VERSION "HNNBNNNYNNNNNNNNNNNNNNNNNNNNNNNNNNNNNNNNNN/4/%%%/4/'%**4NNN///"

NS_ :

BS_:

BU_: Airbag BAP_Tester ICAS1_Gateway ICAS1_KommunikationsServer LE1 LE2 Motor_BEV Schaltbetaetigung

BO_ 514 Daempfer_03: 32 ICAS1_Gateway
 SG_ DR_Aufbaubeschleunigung_HR : 12|10@1+ (0.0327,-15.696) [-15.6960|15.6960] "Unit_MeterPerSeconSquar"  Motor_BEV
 SG_ DR_Aufbaubeschleunigung_VR : 22|10@1+ (0.0327,-15.696) [-15.6960|15.6960] "Unit_MeterPerSeconSquar"  Motor_BEV
 SG_ DR_Aufbaubeschleunigung_VL : 32|10@1+ (0.0327,-15.696) [-15.6960|15.6960] "Unit_MeterPerSeconSquar"  Motor_BEV
 SG_ DR_Aufbaubeschleunigung_HL : 42|10@1+ (0.0327,-15.696) [-15.6960|15.6960] "Unit_MeterPerSeconSquar"  Motor_BEV
 SG_ DR_Funktionsstatus : 52|2@1+ (1.0,0.0) [0.0|3] ""  Vector__XXX
 SG_ DR_Drehwinkelsensortausch_VL : 72|2@1+ (1,0) [1|3] ""  Vector__XXX
 SG_ DR_Drehwinkelsensortausch_VR : 74|2@1+ (1,0) [1|3] ""  Vector__XXX
 SG_ DR_Drehwinkelsensortausch_HL : 76|2@1+ (1,0) [1|3] ""  Vector__XXX
 SG_ DR_Drehwinkelsensortausch_HR : 78|2@1+ (1,0) [1|3] ""  Vector__XXX
 SG_ DR_Drehwinkel_VL : 80|12@1+ (0.088,0) [0.000|359.920] ""  Vector__XXX
 SG_ DR_Drehwinkel_VR : 92|12@1+ (0.088,0) [0.000|359.920] ""  Vector__XXX
 SG_ DR_Drehwinkel_HL : 104|12@1+ (0.088,0) [0.000|359.920] ""  Vector__XXX
 SG_ DR_Drehwinkel_HR : 116|12@1+ (0.088,0) [0.000|359.920] ""  Vector__XXX

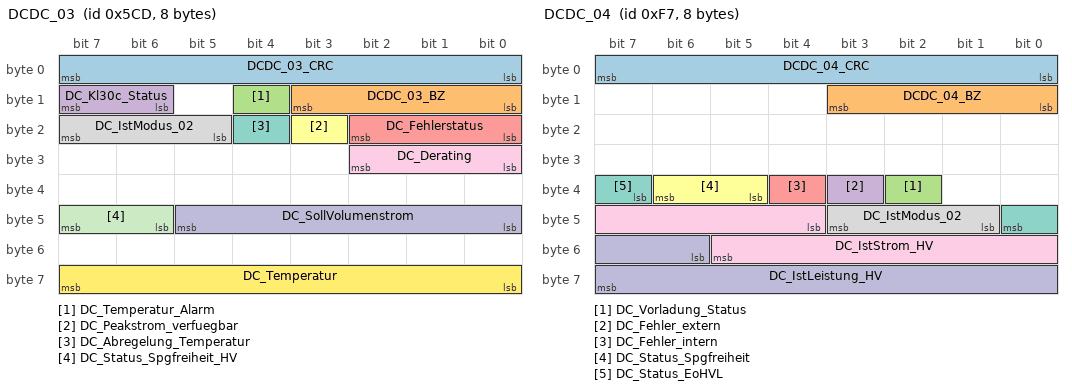
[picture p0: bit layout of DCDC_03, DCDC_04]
BO_ 1485 DCDC_03: 8 ICAS1_Gateway
 SG_ DCDC_03_CRC : 0|8@1+ (1,0) [0|255] ""  Motor_BEV
 SG_ DCDC_03_BZ : 8|4@1+ (1,0) [0|15] ""  Motor_BEV
 SG_ DC_Temperatur_Alarm : 12|1@1+ (1.0,0.0) [0.0|1] ""  Vector__XXX
 SG_ DC_Kl30c_Status : 14|2@1+ (1.0,0.0) [0.0|3] ""  Motor_BEV
 SG_ DC_Fehlerstatus : 16|3@1+ (1.0,0.0) [0.0|7] ""  Vector__XXX
 SG_ DC_Peakstrom_verfuegbar : 19|1@1+ (1.0,0.0) [0.0|1] ""  Vector__XXX
 SG_ DC_Abregelung_Temperatur : 20|1@1+ (1.0,0.0) [0.0|1] ""  Vector__XXX
 SG_ DC_IstModus_02 : 21|3@1+ (1.0,0.0) [0.0|7] ""  Vector__XXX
 SG_ DC_Derating : 24|3@1+ (1.0,0.0) [0.0|7] ""  Vector__XXX
 SG_ DC_SollVolumenstrom : 40|6@1+ (0.5,0) [0.0|30.5] "Unit_LiterPerMinut"  Motor_BEV
 SG_ DC_Status_Spgfreiheit_HV : 46|2@1+ (1.0,0.0) [0.0|3] ""  Vector__XXX
 SG_ DC_Temperatur : 56|8@1+ (1,-40) [-40|213] "Unit_DegreCelsi"  Motor_BEV

BO_ 247 DCDC_04: 8 ICAS1_Gateway
 SG_ DCDC_04_CRC : 0|8@1+ (1,0) [0|255] ""  Vector__XXX
 SG_ DCDC_04_BZ : 8|4@1+ (1,0) [0|15] ""  Vector__XXX
 SG_ DC_Vorladung_Status : 34|1@1+ (1.0,0.0) [0.0|1] ""  Motor_BEV
 SG_ DC_Fehler_extern : 35|1@1+ (1.0,0.0) [0.0|1] ""  Motor_BEV
 SG_ DC_Fehler_intern : 36|1@1+ (1.0,0.0) [0.0|1] ""  Motor_BEV
 SG_ DC_Status_Spgfreiheit : 37|2@1+ (1.0,0.0) [0.0|3] ""  Motor_BEV
 SG_ DC_Status_EoHVL : 39|2@1+ (1.0,0.0) [0.0|3] ""  Motor_BEV
 SG_ DC_IstModus_02 : 41|3@1+ (1.0,0.0) [0.0|7] ""  Motor_BEV
 SG_ DC_IstStrom_HV : 44|10@1+ (0.1,-51.1) [-51.1|51.0] "Unit_Amper"  Motor_BEV
 SG_ DC_IstLeistung_HV : 54|10@1+ (10,-4000) [-4000|6210] "Unit_Watt"  Motor_BEV

BO_ 2617027088 DEV_Airbag_ASM_01: 8 Airbag
 SG_ DEV_Airbag_ASM_01_Data : 0|64@1+ (1.0,0.0) [0.0|18446744073709551615] ""  Vector__XXX

BO_ 2617027072 DEV_Airbag_Resp_00: 8 Airbag
 SG_ DEV_Airbag_Resp_00_Data : 0|64@1+ (1.0,0.0) [0.0|18446744073709551615] ""  Vector__XXX

BO_ 2617027073 DEV_Airbag_Resp_01: 8 Airbag
 SG_ DEV_Airbag_Resp_01_Data : 0|64@1+ (1.0,0.0) [0.0|18446744073709551615] ""  Vector__XXX

BO_ 2617027074 DEV_Airbag_Resp_02: 8 Airbag
 SG_ DEV_Airbag_Resp_02_Data : 0|64@1+ (1.0,0.0) [0.0|18446744073709551615] ""  Vector__XXX

BO_ 2617027075 DEV_Airbag_Resp_03: 8 Airbag
 SG_ DEV_Airbag_Resp_03_Data : 0|64@1+ (1.0,0.0) [0.0|18446744073709551615] ""  Vector__XXX

BO_ 2617027076 DEV_Airbag_Resp_04: 8 Airbag
 SG_ DEV_Airbag_Resp_04_Data : 0|64@1+ (1.0,0.0) [0.0|18446744073709551615] ""  Vector__XXX

BO_ 2617027077 DEV_Airbag_Resp_05: 8 Airbag
 SG_ DEV_Airbag_Resp_05_Data : 0|64@1+ (1.0,0.0) [0.0|18446744073709551615] ""  Vector__XXX

BO_ 2617027078 DEV_Airbag_Resp_06: 8 Airbag
 SG_ DEV_Airbag_Resp_06_Data : 0|64@1+ (1.0,0.0) [0.0|18446744073709551615] ""  Vector__XXX

BO_ 2617027079 DEV_Airbag_Resp_07: 8 Airbag
 SG_ DEV_Airbag_Resp_07_Data : 0|64@1+ (1.0,0.0) [0.0|18446744073709551615] ""  Vector__XXX

BO_ 2617027080 DEV_Airbag_Resp_08: 8 Airbag
 SG_ DEV_Airbag_Resp_08_Data : 0|64@1+ (1.0,0.0) [0.0|18446744073709551615] ""  Vector__XXX

BO_ 2617027081 DEV_Airbag_Resp_09: 8 Airbag
 SG_ DEV_Airbag_Resp_09_Data : 0|64@1+ (1.0,0.0) [0.0|18446744073709551615] ""  Vector__XXX

BO_ 2617027082 DEV_Airbag_Resp_10: 8 Airbag
 SG_ DEV_Airbag_Resp_10_Data : 0|64@1+ (1.0,0.0) [0.0|18446744073709551615] ""  Vector__XXX

BO_ 2617027083 DEV_Airbag_Resp_11: 8 Airbag
 SG_ DEV_Airbag_Resp_11_Data : 0|64@1+ (1.0,0.0) [0.0|18446744073709551615] ""  Vector__XXX

BO_ 2617154048 DEV_Waehlhebel_Resp_00: 8 Schaltbetaetigung
 SG_ DEV_Waehlhebel_Resp_00_Data : 0|64@1+ (1.0,0.0) [0.0|18446744073709551615] ""  Vector__XXX

BO_ 2617154049 DEV_Waehlhebel_Resp_01: 8 Schaltbetaetigung
 SG_ DEV_Waehlhebel_Resp_01_Data : 0|64@1+ (1.0,0.0) [0.0|18446744073709551615] ""  Vector__XXX

BO_ 2617154050 DEV_Waehlhebel_Resp_02: 8 Schaltbetaetigung
 SG_ DEV_Waehlhebel_Resp_02_Data : 0|64@1+ (1.0,0.0) [0.0|18446744073709551615] ""  Vector__XXX

BO_ 2617154051 DEV_Waehlhebel_Resp_03: 8 Schaltbetaetigung
 SG_ DEV_Waehlhebel_Resp_03_Data : 0|64@1+ (1.0,0.0) [0.0|18446744073709551615] ""  Vector__XXX

BO_ 2617154052 DEV_Waehlhebel_Resp_04: 8 Schaltbetaetigung
 SG_ DEV_Waehlhebel_Resp_04_Data : 0|64@1+ (1.0,0.0) [0.0|18446744073709551615] ""  Vector__XXX

BO_ 2617154053 DEV_Waehlhebel_Resp_05: 8 Schaltbetaetigung
 SG_ DEV_Waehlhebel_Resp_05_Data : 0|64@1+ (1.0,0.0) [0.0|18446744073709551615] ""  Vector__XXX

BO_ 2549876269 Diag_Waehlhebel_Req: 8 Motor_BEV
 SG_ Diag_Waehlhebel_Req_Data : 0|64@1+ (1.0,0.0) [0.0|18446744073709551615] ""  Schaltbetaetigung

BO_ 2550007341 Diag_Waehlhebel_Resp: 8 Schaltbetaetigung
 SG_ Diag_Waehlhebel_Resp_Data : 0|64@1+ (1.0,0.0) [0.0|18446744073709551615] ""  Motor_BEV

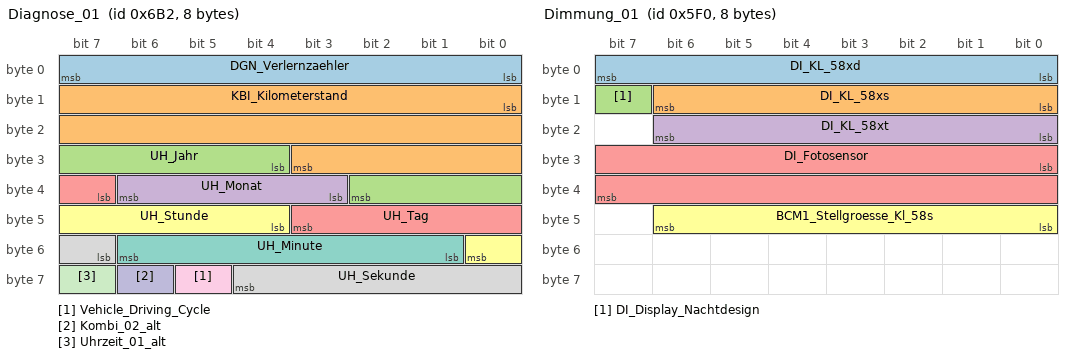
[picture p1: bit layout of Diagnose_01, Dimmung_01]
BO_ 1714 Diagnose_01: 8 ICAS1_Gateway
 SG_ DGN_Verlernzaehler : 0|8@1+ (1,0) [0|254] ""  Airbag,LE1,LE2,Motor_BEV
 SG_ KBI_Kilometerstand : 8|20@1+ (1,0) [0|1048573] "Unit_KiloMeter"  Airbag,LE1,LE2,Motor_BEV
 SG_ UH_Jahr : 28|7@1+ (1,2000) [2000|2127] "Unit_Year"  Airbag,LE1,LE2,Motor_BEV
 SG_ UH_Monat : 35|4@1+ (1,0) [1|12] "Unit_Month"  Airbag,LE1,LE2,Motor_BEV
 SG_ UH_Tag : 39|5@1+ (1,0) [1|31] "Unit_Day"  Airbag,LE1,LE2,Motor_BEV
 SG_ UH_Stunde : 44|5@1+ (1,0) [0|23] "Unit_Hours"  Airbag,LE1,LE2,Motor_BEV
 SG_ UH_Minute : 49|6@1+ (1,0) [0|59] "Unit_Minut"  Airbag,LE1,LE2,Motor_BEV
 SG_ UH_Sekunde : 55|6@1+ (1,0) [0|59] "Unit_Secon"  Airbag,LE1,LE2,Motor_BEV
 SG_ Vehicle_Driving_Cycle : 61|1@1+ (1.0,0.0) [0.0|1] ""  Airbag
 SG_ Kombi_02_alt : 62|1@1+ (1.0,0.0) [0.0|1] ""  Vector__XXX
 SG_ Uhrzeit_01_alt : 63|1@1+ (1.0,0.0) [0.0|1] ""  Vector__XXX

BO_ 851 DiETa_01: 8 ICAS1_Gateway
 SG_ DiETas_01_CRC : 0|8@1+ (1,0) [0|255] ""  Airbag
 SG_ DiETas_01_BZ : 8|4@1+ (1,0) [0|15] ""  Airbag
 SG_ DiETa_Reserve_Byte2_4 : 12|1@1+ (1.0,0.0) [0.0|1] ""  Vector__XXX
 SG_ DiETa_Status : 13|2@1+ (1.0,0.0) [0.0|3] ""  Airbag
 SG_ DiETa_ResponseError : 15|1@1+ (1.0,0.0) [0.0|1] ""  Vector__XXX
 SG_ DiETa_Car : 16|2@1+ (1.0,0.0) [0.0|3] ""  Vector__XXX
 SG_ DiETa_Klima : 18|2@1+ (1.0,0.0) [0.0|3] ""  Vector__XXX
 SG_ DiETa_Mode : 20|2@1+ (1.0,0.0) [0.0|3] ""  Vector__XXX
 SG_ DiETa_Parken : 22|2@1+ (1.0,0.0) [0.0|3] ""  Vector__XXX
 SG_ DiETa_FSH_Taste : 24|2@1+ (1.0,0.0) [0.0|3] ""  Vector__XXX
 SG_ DiETa_HSH_Taste : 26|2@1+ (1.0,0.0) [0.0|3] ""  Vector__XXX
 SG_ DiETa_Warnblink_Taste : 28|2@1+ (1.0,0.0) [0.0|3] ""  Vector__XXX
 SG_ DiETa_FAS_Stufe : 30|2@1+ (1.0,0.0) [0.0|3] ""  Vector__XXX
 SG_ DiETa_PAO_ON_Status : 32|2@1+ (1.0,0.0) [0.0|3] ""  Airbag
 SG_ DiETa_PAO_OFF_Status : 34|2@1+ (1.0,0.0) [0.0|3] ""  Airbag
 SG_ DiETa_Defrost_Taste : 36|2@1+ (1.0,0.0) [0.0|3] ""  Vector__XXX
 SG_ DiETa_Reserve_Byte5_6 : 38|2@1+ (1.0,0.0) [0.0|3] ""  Vector__XXX
 SG_ DiETa_Lock_Unlock_Taste : 40|3@1+ (1.0,0.0) [0.0|7] ""  Vector__XXX
 SG_ DiETa_Mode_roh : 43|1@1+ (1.0,0.0) [0.0|1] ""  Vector__XXX
 SG_ DiETa_Reserve_Byte6_3 : 44|4@1+ (1.0,0.0) [0.0|15] ""  Vector__XXX
 SG_ DiETa_Reserve_Byte7 : 48|8@1+ (1.0,0.0) [0.0|255] ""  Vector__XXX
 SG_ DiETa_Reserve_Byte8 : 56|8@1+ (1.0,0.0) [0.0|255] ""  Vector__XXX

BO_ 1520 Dimmung_01: 8 ICAS1_Gateway
 SG_ DI_KL_58xd : 0|8@1+ (1,0) [0|253] ""  Airbag,Schaltbetaetigung
 SG_ DI_KL_58xs : 8|7@1+ (1,0) [0|100] "Unit_PerCent"  Airbag
 SG_ DI_Display_Nachtdesign : 15|1@1+ (1.0,0.0) [0.0|1] ""  Vector__XXX
 SG_ DI_KL_58xt : 16|7@1+ (1,0) [0|100] "Unit_PerCent"  Airbag,Schaltbetaetigung
 SG_ DI_Fotosensor : 24|16@1+ (1,0) [0|65535] ""  Vector__XXX
 SG_ BCM1_Stellgroesse_Kl_58s : 40|7@1+ (1,0) [0|100] ""  Vector__XXX

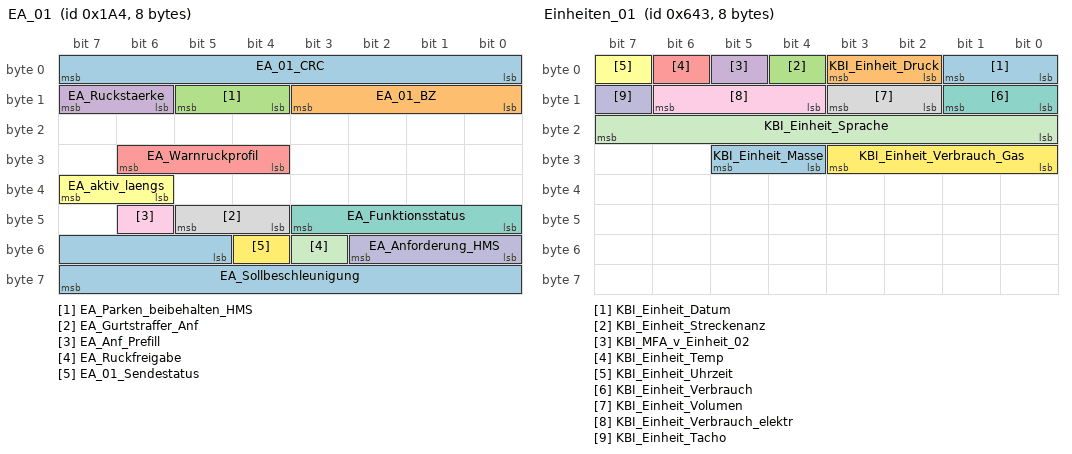
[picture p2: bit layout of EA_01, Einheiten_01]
BO_ 420 EA_01: 8 ICAS1_Gateway
 SG_ EA_01_CRC : 0|8@1+ (1,0) [0|255] ""  Motor_BEV
 SG_ EA_01_BZ : 8|4@1+ (1,0) [0|15] ""  Motor_BEV
 SG_ EA_Parken_beibehalten_HMS : 12|2@1+ (1.0,0.0) [0.0|3] ""  Vector__XXX
 SG_ EA_Ruckstaerke : 14|2@1+ (1.0,0.0) [0.0|3] ""  Vector__XXX
 SG_ EA_Warnruckprofil : 28|3@1+ (1.0,0.0) [0.0|7] ""  Vector__XXX
 SG_ EA_aktiv_laengs : 38|2@1+ (1.0,0.0) [0.0|3] ""  Motor_BEV
 SG_ EA_Funktionsstatus : 40|4@1+ (1.0,0.0) [0.0|15] ""  Motor_BEV
 SG_ EA_Gurtstraffer_Anf : 44|2@1+ (1.0,0.0) [0.0|3] ""  Airbag
 SG_ EA_Anf_Prefill : 46|1@1+ (1.0,0.0) [0.0|1] ""  Vector__XXX
 SG_ EA_Anforderung_HMS : 48|3@1+ (1.0,0.0) [0.0|7] ""  Vector__XXX
 SG_ EA_Ruckfreigabe : 51|1@1+ (1.0,0.0) [0.0|1] ""  Vector__XXX
 SG_ EA_01_Sendestatus : 52|1@1+ (1.0,0.0) [0.0|1] ""  Vector__XXX
 SG_ EA_Sollbeschleunigung : 53|11@1+ (0.005,-7.22) [-7.220|3.005] "Unit_MeterPerSeconSquar"  Motor_BEV

BO_ 374 EBKV_03: 8 ICAS1_Gateway
 SG_ EBKV_03_CRC : 0|8@1+ (1,0) [0|255] ""  Vector__XXX
 SG_ EBKV_03_BZ : 8|4@1+ (1,0) [0|15] ""  Vector__XXX
 SG_ EBKV_Activate_Fallback_ESP : 12|1@1+ (1.0,0.0) [0.0|1] ""  Vector__XXX
 SG_ EBKV_Restdruckabsenkung : 13|3@1+ (1.0,0.0) [0.0|7] ""  Vector__XXX
 SG_ EBKV_Status_02 : 16|4@1+ (1.0,0.0) [0.0|15] ""  Vector__XXX
 SG_ EBKV_Diagnose : 20|1@1+ (1.0,0.0) [0.0|1] ""  Vector__XXX
 SG_ EBKV_Fahrer_bremst : 21|1@1+ (1.0,0.0) [0.0|1] ""  Motor_BEV
 SG_ EBKV_QBit_Fahrer_bremst : 22|1@1+ (1.0,0.0) [0.0|1] ""  Motor_BEV
 SG_ EBKV_Fahrer_bremst_deutlich : 23|1@1+ (1.0,0.0) [0.0|1] ""  Vector__XXX
 SG_ EBKV_OBD_Status : 24|1@1+ (1.0,0.0) [0.0|1] ""  Motor_BEV
 SG_ EBKV_VMM_Sek_Notstopp_Status : 25|3@1+ (1.0,0.0) [0.0|7] ""  Vector__XXX
 SG_ EBKV_Anforderung_HMS : 28|3@1+ (1.0,0.0) [0.0|7] ""  Vector__XXX
 SG_ SBS_Anforderung_GE : 31|1@1+ (1.0,0.0) [0.0|1] ""  Vector__XXX
 SG_ EPB_Status_ext : 32|3@1+ (1.0,0.0) [0.0|7] ""  Motor_BEV
 SG_ EBKV_Bremspedalweg : 40|8@1+ (0.4,-0.4) [0.0|101.2] "Unit_PerCent"  Motor_BEV
 SG_ EBKV_Kraftblending_Reserve : 48|8@1+ (0.5,0) [0.0|125.0] "Unit_Bar"  Vector__XXX
 SG_ EBKV_Aussteuerdruck : 56|8@1+ (1,0) [0|250] "Unit_Bar"  Vector__XXX

BO_ 1603 Einheiten_01: 8 ICAS1_KommunikationsServer
 SG_ KBI_Einheit_Datum : 0|2@1+ (1.0,0.0) [0.0|3] ""  Vector__XXX
 SG_ KBI_Einheit_Druck : 2|2@1+ (1.0,0.0) [0.0|3] ""  Vector__XXX
 SG_ KBI_Einheit_Streckenanz : 4|1@1+ (1.0,0.0) [0.0|1] ""  Vector__XXX
 SG_ KBI_MFA_v_Einheit_02 : 5|1@1+ (1.0,0.0) [0.0|1] ""  Motor_BEV
 SG_ KBI_Einheit_Temp : 6|1@1+ (1.0,0.0) [0.0|1] ""  Vector__XXX
 SG_ KBI_Einheit_Uhrzeit : 7|1@1+ (1.0,0.0) [0.0|1] ""  Vector__XXX
 SG_ KBI_Einheit_Verbrauch : 8|2@1+ (1.0,0.0) [0.0|3] ""  Vector__XXX
 SG_ KBI_Einheit_Volumen : 10|2@1+ (1.0,0.0) [0.0|3] ""  Vector__XXX
 SG_ KBI_Einheit_Verbrauch_elektr : 12|3@1+ (1.0,0.0) [0.0|7] ""  Vector__XXX
 SG_ KBI_Einheit_Tacho : 15|1@1+ (1.0,0.0) [0.0|1] ""  Motor_BEV
 SG_ KBI_Einheit_Sprache : 16|8@1+ (1,0) [0|255] ""  Vector__XXX
 SG_ KBI_Einheit_Verbrauch_Gas : 24|4@1+ (1.0,0.0) [0.0|15] ""  Vector__XXX
 SG_ KBI_Einheit_Masse : 28|2@1+ (1.0,0.0) [0.0|3] ""  Vector__XXX

BO_ 192 EM1_01: 32 LE1
 SG_ EM1_01_CRC : 0|8@1+ (1,0) [0|255] ""  ICAS1_Gateway,Motor_BEV
 SG_ EM1_01_BZ : 8|4@1+ (1,0) [0|15] ""  ICAS1_Gateway,Motor_BEV
 SG_ EM1_Istmodus : 12|4@1+ (1.0,0.0) [0.0|15] ""  ICAS1_Gateway,Motor_BEV
 SG_ EM1_IstMoment : 16|12@1+ (0.5,-1023) [-1023.0|1023.5] "Unit_NewtoMeter"  ICAS1_Gateway,Motor_BEV
 SG_ EM1_Moment_AR_Eingriff : 28|12@1+ (0.5,-1023) [-1023.0|1023.5] "Unit_NewtoMeter"  ICAS1_Gateway,Motor_BEV
 SG_ EM1_IstDrehzahl : 40|15@1+ (1,-10000) [-10000|22765] "Unit_MinutInver"  ICAS1_Gateway,Motor_BEV
 SG_ EM1_AR_aktiv : 55|1@1+ (1.0,0.0) [0.0|1] ""  ICAS1_Gateway,Motor_BEV
 SG_ EM1_IstSpannung : 56|12@1+ (0.25,0) [0.00|1023.25] "Unit_Volt"  ICAS1_Gateway,Motor_BEV
 SG_ EM1_Strom_HV : 68|12@1+ (0.5,-1023) [-1023.0|1023.5] "Unit_Amper"  ICAS1_Gateway,Motor_BEV
 SG_ EM1_Max_Moment : 80|11@1+ (1,-1023) [-1023|1022] "Unit_NewtoMeter"  ICAS1_Gateway,Motor_BEV
 SG_ EM1_ErwGrenzen_aktiv : 91|1@1+ (1.0,0.0) [0.0|1] ""  ICAS1_Gateway,Motor_BEV
 SG_ EM1_Min_Moment : 92|11@1+ (1,-1023) [-1023|1022] "Unit_NewtoMeter"  ICAS1_Gateway,Motor_BEV
 SG_ EM1_Fehler_ElAntriebAbschaltung : 103|1@1+ (1.0,0.0) [0.0|1] ""  ICAS1_Gateway,Motor_BEV
 SG_ EM1_Max_Moment_Lim : 104|11@1+ (1,-1023) [-1023|1022] "Unit_NewtoMeter"  ICAS1_Gateway,Motor_BEV
 SG_ EM1_Fehler_Notabschaltung : 115|1@1+ (1.0,0.0) [0.0|1] ""  ICAS1_Gateway,Motor_BEV
 SG_ EM1_Min_Moment_Lim : 116|11@1+ (1,-1023) [-1023|1022] "Unit_NewtoMeter"  ICAS1_Gateway,Motor_BEV
 SG_ EM1_Status_DrzEingriff : 127|2@1+ (1.0,0.0) [0.0|3] ""  ICAS1_Gateway,Motor_BEV
 SG_ EM1_Mom_DrzEingriff : 129|11@1+ (1,-1023) [-1023|1022] "Unit_NewtoMeter"  ICAS1_Gateway,Motor_BEV

BO_ 2463978673 EM1_02: 32 LE1
 SG_ EM1_Status_Spgfreiheit : 12|2@1+ (1.0,0.0) [0.0|3] ""  Motor_BEV
 SG_ EM1_Status_EoHVL : 14|2@1+ (1.0,0.0) [0.0|3] ""  Motor_BEV
 SG_ EM1_Max_LeistungMech_Sockel : 16|13@1+ (200,-819000) [-819000|818800] "Unit_Watt"  Vector__XXX
 SG_ EM1_Max_Moment_Sockel : 29|11@1+ (1,-1023) [-1023|1022] "Unit_NewtoMeter"  Vector__XXX
 SG_ EM1_Min_LeistungMech_Sockel : 40|13@1+ (200,-819000) [-819000|818800] "Unit_Watt"  Vector__XXX
 SG_ EM1_Min_Moment_Sockel : 53|11@1+ (1,-1023) [-1023|1022] "Unit_NewtoMeter"  Vector__XXX
 SG_ EM1_PerfInd_MaxLeistung : 64|10@1+ (0.2,0) [0.0|200.0] "Unit_PerCent"  Motor_BEV
 SG_ EM1_PerfInd_MaxMoment : 74|10@1+ (0.2,0) [0.0|200.0] "Unit_PerCent"  Motor_BEV
 SG_ EM1_AnlernenElMotor_Anf : 84|1@1+ (1.0,0.0) [0.0|1] ""  Motor_BEV
 SG_ EM1_OBD_Lampe_Anf : 85|1@1+ (1.0,0.0) [0.0|1] ""  Motor_BEV
 SG_ EM1_Generator_Moment : 86|10@1+ (1,0) [0|1021] "Unit_NewtoMeter"  Motor_BEV
 SG_ EM1_PerfInd_Temperatur : 96|8@1+ (0.8,0) [0.0|200.0] "Unit_PerCent"  Motor_BEV
 SG_ EM1_MaxZul_Drehzahl : 104|8@1+ (80,0) [0|20240] "Unit_RevPerMinute"  Motor_BEV
 SG_ EM1_Min_Moment_Gesamt : 112|11@1+ (1,-1023) [-1023|1022] "Unit_NewtoMeter"  Motor_BEV
 SG_ EM1_Fehlerlampe_Anf : 123|1@1+ (1.0,0.0) [0.0|1] ""  Motor_BEV
 SG_ EM1_Max_Moment_Gesamt : 124|11@1+ (1,-1023) [-1023|1022] "Unit_NewtoMeter"  Motor_BEV
 SG_ EM1_Warnlampe_Anf : 135|1@1+ (1.0,0.0) [0.0|1] ""  Motor_BEV
 SG_ EM1_Rekuperation : 136|15@1+ (10,0) [0|327670] "Unit_WattSecond"  Motor_BEV
 SG_ EM1_Rekuperation_Ueberlauf : 151|1@1+ (1.0,0.0) [0.0|1] ""  Motor_BEV
 SG_ EM1_Verbrauch : 152|15@1+ (10,0) [0|327670] "Unit_WattSecond"  Motor_BEV
 SG_ EM1_Verbrauch_Ueberlauf : 167|1@1+ (1.0,0.0) [0.0|1] ""  Motor_BEV
 SG_ EM1_Fehler_AE : 168|1@1+ (1.0,0.0) [0.0|1] ""  Motor_BEV
 SG_ EM1_Fehler_Leistungsred : 169|1@1+ (1.0,0.0) [0.0|1] ""  Motor_BEV
 SG_ EM1_Fehler_ElAntriebFreilauf : 170|1@1+ (1.0,0.0) [0.0|1] ""  Motor_BEV
 SG_ EM1_PWR_SollVolumenstrom : 171|6@1+ (0.5,0) [0.0|30.5] "Unit_LiterPerMinut"  Motor_BEV

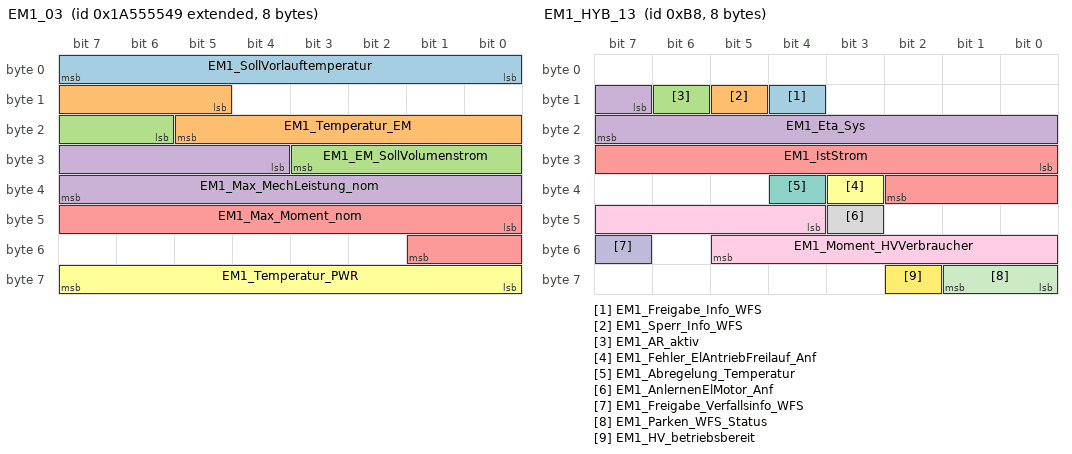
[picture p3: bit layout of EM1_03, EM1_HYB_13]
BO_ 2589283657 EM1_03: 8 LE1
 SG_ EM1_SollVorlauftemperatur : 0|8@1+ (0.5,-40) [-40.0|86.5] "Unit_DegreCelsi"  Motor_BEV
 SG_ EM1_Temperatur_EM : 13|9@1+ (1,-40) [-40|469] "Unit_DegreCelsi"  ICAS1_Gateway,Motor_BEV
 SG_ EM1_EM_SollVolumenstrom : 22|6@1+ (0.5,0) [0.0|30.5] "Unit_LiterPerMinut"  Motor_BEV
 SG_ EM1_Max_MechLeistung_nom : 28|12@1+ (200,0) [0|818600] "Unit_Watt"  Motor_BEV
 SG_ EM1_Max_Moment_nom : 40|10@1+ (1,0) [0|1021] "Unit_NewtoMeter"  Motor_BEV
 SG_ EM1_Temperatur_PWR : 56|8@1+ (1,-40) [-40|213] "Unit_DegreCelsi"  ICAS1_Gateway,Motor_BEV

BO_ 184 EM1_HYB_13: 8 LE1
 SG_ EM1_Freigabe_Info_WFS : 12|1@1+ (1.0,0.0) [0.0|1] ""  ICAS1_Gateway,Motor_BEV
 SG_ EM1_Sperr_Info_WFS : 13|1@1+ (1.0,0.0) [0.0|1] ""  ICAS1_Gateway,Motor_BEV
 SG_ EM1_AR_aktiv : 14|1@1+ (1.0,0.0) [0.0|1] ""  ICAS1_Gateway
 SG_ EM1_Eta_Sys : 15|9@1+ (0.2,0) [0.0|101.8] "Unit_PerCent"  ICAS1_Gateway
 SG_ EM1_IstStrom : 24|11@1+ (1,-1023) [-1023|1022] "Unit_Amper"  ICAS1_Gateway
 SG_ EM1_Fehler_ElAntriebFreilauf_Anf : 35|1@1+ (1.0,0.0) [0.0|1] ""  ICAS1_Gateway
 SG_ EM1_Abregelung_Temperatur : 36|1@1+ (1.0,0.0) [0.0|1] ""  ICAS1_Gateway
 SG_ EM1_AnlernenElMotor_Anf : 43|1@1+ (1.0,0.0) [0.0|1] ""  ICAS1_Gateway
 SG_ EM1_Moment_HVVerbraucher : 44|10@1+ (1,-511) [-511|511] "Unit_NewtoMeter"  ICAS1_Gateway
 SG_ EM1_Freigabe_Verfallsinfo_WFS : 55|1@1+ (1.0,0.0) [0.0|1] ""  ICAS1_Gateway,Motor_BEV
 SG_ EM1_Parken_WFS_Status : 56|2@1+ (1.0,0.0) [0.0|3] ""  ICAS1_Gateway
 SG_ EM1_HV_betriebsbereit : 58|1@1+ (1.0,0.0) [0.0|1] ""  ICAS1_Gateway

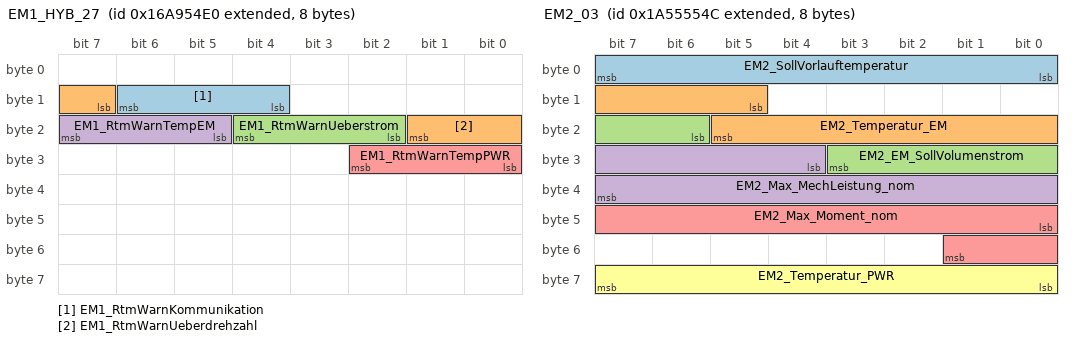
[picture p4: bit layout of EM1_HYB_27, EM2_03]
BO_ 2527679712 EM1_HYB_27: 8 LE1
 SG_ EM1_RtmWarnKommunikation : 12|3@1+ (1.0,0.0) [0.0|7] ""  Vector__XXX
 SG_ EM1_RtmWarnUeberdrehzahl : 15|3@1+ (1.0,0.0) [0.0|7] ""  ICAS1_Gateway
 SG_ EM1_RtmWarnUeberstrom : 18|3@1+ (1.0,0.0) [0.0|7] ""  ICAS1_Gateway
 SG_ EM1_RtmWarnTempEM : 21|3@1+ (1.0,0.0) [0.0|7] ""  ICAS1_Gateway
 SG_ EM1_RtmWarnTempPWR : 24|3@1+ (1.0,0.0) [0.0|7] ""  ICAS1_Gateway

BO_ 193 EM2_01: 32 LE2
 SG_ EM2_01_CRC : 0|8@1+ (1,0) [0|255] ""  Motor_BEV
 SG_ EM2_01_BZ : 8|4@1+ (1,0) [0|15] ""  Motor_BEV
 SG_ EM2_Istmodus : 12|4@1+ (1.0,0.0) [0.0|15] ""  ICAS1_Gateway,Motor_BEV
 SG_ EM2_IstMoment : 16|12@1+ (0.5,-1023) [-1023.0|1023.5] "Unit_NewtoMeter"  ICAS1_Gateway,Motor_BEV
 SG_ EM2_Moment_AR_Eingriff : 28|12@1+ (0.5,-1023) [-1023.0|1023.5] "Unit_NewtoMeter"  Motor_BEV
 SG_ EM2_IstDrehzahl : 40|15@1+ (1,-10000) [-10000|22765] "Unit_MinutInver"  ICAS1_Gateway,Motor_BEV
 SG_ EM2_AR_aktiv : 55|1@1+ (1.0,0.0) [0.0|1] ""  Motor_BEV
 SG_ EM2_IstSpannung : 56|12@1+ (0.25,0) [0.00|1023.25] "Unit_Volt"  ICAS1_Gateway,Motor_BEV
 SG_ EM2_Strom_HV : 68|12@1+ (0.5,-1023) [-1023.0|1023.5] "Unit_Amper"  ICAS1_Gateway,Motor_BEV
 SG_ EM2_Max_Moment : 80|11@1+ (1,-1023) [-1023|1022] "Unit_NewtoMeter"  Motor_BEV
 SG_ EM2_ErwGrenzen_aktiv : 91|1@1+ (1.0,0.0) [0.0|1] ""  Motor_BEV
 SG_ EM2_Min_Moment : 92|11@1+ (1,-1023) [-1023|1022] "Unit_NewtoMeter"  Motor_BEV
 SG_ EM2_Fehler_ElAntriebAbschaltung : 103|1@1+ (1.0,0.0) [0.0|1] ""  Motor_BEV
 SG_ EM2_Max_Moment_Lim : 104|11@1+ (1,-1023) [-1023|1022] "Unit_NewtoMeter"  Motor_BEV
 SG_ EM2_Fehler_Notabschaltung : 115|1@1+ (1.0,0.0) [0.0|1] ""  ICAS1_Gateway,Motor_BEV
 SG_ EM2_Min_Moment_Lim : 116|11@1+ (1,-1023) [-1023|1022] "Unit_NewtoMeter"  Motor_BEV
 SG_ EM2_Status_DrzEingriff : 127|2@1+ (1.0,0.0) [0.0|3] ""  ICAS1_Gateway,Motor_BEV
 SG_ EM2_Mom_DrzEingriff : 129|11@1+ (1,-1023) [-1023|1022] "Unit_NewtoMeter"  Motor_BEV

BO_ 2463978674 EM2_02: 32 LE2
 SG_ EM2_Status_Spgfreiheit : 12|2@1+ (1.0,0.0) [0.0|3] ""  Motor_BEV
 SG_ EM2_Status_EoHVL : 14|2@1+ (1.0,0.0) [0.0|3] ""  Motor_BEV
 SG_ EM2_Max_LeistungMech_Sockel : 16|13@1+ (200,-819000) [-819000|818800] "Unit_Watt"  Vector__XXX
 SG_ EM2_Max_Moment_Sockel : 29|11@1+ (1,-1023) [-1023|1022] "Unit_NewtoMeter"  Vector__XXX
 SG_ EM2_Min_LeistungMech_Sockel : 40|13@1+ (200,-819000) [-819000|818800] "Unit_Watt"  Vector__XXX
 SG_ EM2_Min_Moment_Sockel : 53|11@1+ (1,-1023) [-1023|1022] "Unit_NewtoMeter"  Vector__XXX
 SG_ EM2_PerfInd_MaxLeistung : 64|10@1+ (0.2,0) [0.0|200.0] "Unit_PerCent"  Motor_BEV
 SG_ EM2_PerfInd_MaxMoment : 74|10@1+ (0.2,0) [0.0|200.0] "Unit_PerCent"  Motor_BEV
 SG_ EM2_AnlernenElMotor_Anf : 84|1@1+ (1.0,0.0) [0.0|1] ""  Motor_BEV
 SG_ EM2_OBD_Lampe_Anf : 85|1@1+ (1.0,0.0) [0.0|1] ""  Motor_BEV
 SG_ EM2_Generator_Moment : 86|10@1+ (1,0) [0|1021] "Unit_NewtoMeter"  Motor_BEV
 SG_ EM2_PerfInd_Temperatur : 96|8@1+ (0.8,0) [0.0|200.0] "Unit_PerCent"  Motor_BEV
 SG_ EM2_MaxZul_Drehzahl : 104|8@1+ (80,0) [0|20240] "Unit_RevPerMinute"  Motor_BEV
 SG_ EM2_Min_Moment_Gesamt : 112|11@1+ (1,-1023) [-1023|1022] "Unit_NewtoMeter"  Motor_BEV
 SG_ EM2_Fehlerlampe_Anf : 123|1@1+ (1.0,0.0) [0.0|1] ""  Motor_BEV
 SG_ EM2_Max_Moment_Gesamt : 124|11@1+ (1,-1023) [-1023|1022] "Unit_NewtoMeter"  Motor_BEV
 SG_ EM2_Warnlampe_Anf : 135|1@1+ (1.0,0.0) [0.0|1] ""  Motor_BEV
 SG_ EM2_Rekuperation : 136|15@1+ (10,0) [0|327670] "Unit_WattSecond"  Motor_BEV
 SG_ EM2_Rekuperation_Ueberlauf : 151|1@1+ (1.0,0.0) [0.0|1] ""  Motor_BEV
 SG_ EM2_Verbrauch : 152|15@1+ (10,0) [0|327670] "Unit_WattSecond"  Motor_BEV
 SG_ EM2_Verbrauch_Ueberlauf : 167|1@1+ (1.0,0.0) [0.0|1] ""  Motor_BEV
 SG_ EM2_Fehler_AE : 168|1@1+ (1.0,0.0) [0.0|1] ""  Motor_BEV
 SG_ EM2_Fehler_Leistungsred : 169|1@1+ (1.0,0.0) [0.0|1] ""  Motor_BEV
 SG_ EM2_Fehler_ElAntriebFreilauf : 170|1@1+ (1.0,0.0) [0.0|1] ""  Motor_BEV
 SG_ EM2_PWR_SollVolumenstrom : 171|6@1+ (0.5,0) [0.0|30.5] "Unit_LiterPerMinut"  Motor_BEV

BO_ 2589283660 EM2_03: 8 LE2
 SG_ EM2_SollVorlauftemperatur : 0|8@1+ (0.5,-40) [-40.0|86.5] "Unit_DegreCelsi"  Motor_BEV
 SG_ EM2_Temperatur_EM : 13|9@1+ (1,-40) [-40|469] "Unit_DegreCelsi"  ICAS1_Gateway,Motor_BEV
 SG_ EM2_EM_SollVolumenstrom : 22|6@1+ (0.5,0) [0.0|30.5] "Unit_LiterPerMinut"  Motor_BEV
 SG_ EM2_Max_MechLeistung_nom : 28|12@1+ (200,0) [0|818600] "Unit_Watt"  Motor_BEV
 SG_ EM2_Max_Moment_nom : 40|10@1+ (1,0) [0|1021] "Unit_NewtoMeter"  Motor_BEV
 SG_ EM2_Temperatur_PWR : 56|8@1+ (1,-40) [-40|213] "Unit_DegreCelsi"  ICAS1_Gateway,Motor_BEV

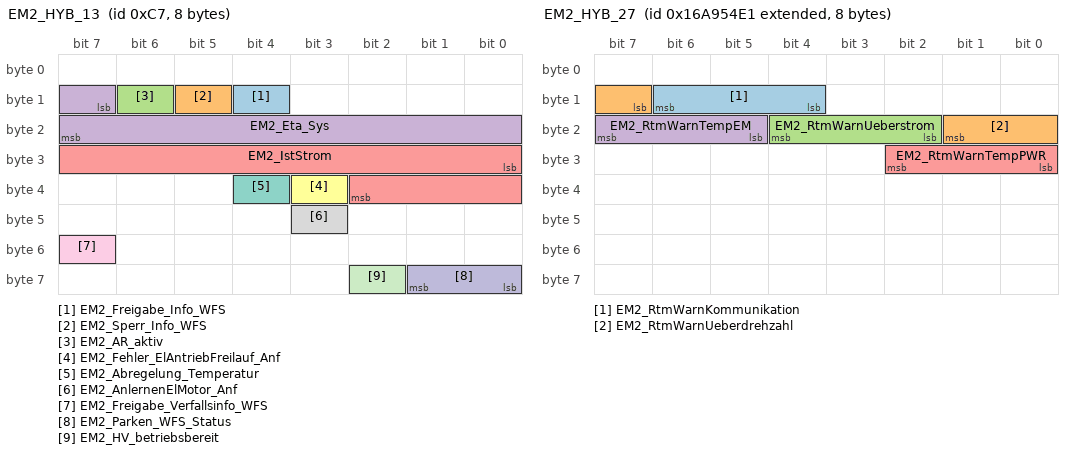
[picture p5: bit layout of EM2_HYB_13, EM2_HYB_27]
BO_ 199 EM2_HYB_13: 8 LE2
 SG_ EM2_Freigabe_Info_WFS : 12|1@1+ (1.0,0.0) [0.0|1] ""  ICAS1_Gateway,Motor_BEV
 SG_ EM2_Sperr_Info_WFS : 13|1@1+ (1.0,0.0) [0.0|1] ""  ICAS1_Gateway,Motor_BEV
 SG_ EM2_AR_aktiv : 14|1@1+ (1.0,0.0) [0.0|1] ""  ICAS1_Gateway
 SG_ EM2_Eta_Sys : 15|9@1+ (0.2,0) [0.0|101.8] "Unit_PerCent"  ICAS1_Gateway
 SG_ EM2_IstStrom : 24|11@1+ (1,-1023) [-1023|1022] "Unit_Amper"  ICAS1_Gateway
 SG_ EM2_Fehler_ElAntriebFreilauf_Anf : 35|1@1+ (1.0,0.0) [0.0|1] ""  ICAS1_Gateway
 SG_ EM2_Abregelung_Temperatur : 36|1@1+ (1.0,0.0) [0.0|1] ""  ICAS1_Gateway
 SG_ EM2_AnlernenElMotor_Anf : 43|1@1+ (1.0,0.0) [0.0|1] ""  ICAS1_Gateway
 SG_ EM2_Freigabe_Verfallsinfo_WFS : 55|1@1+ (1.0,0.0) [0.0|1] ""  ICAS1_Gateway,Motor_BEV
 SG_ EM2_Parken_WFS_Status : 56|2@1+ (1.0,0.0) [0.0|3] ""  ICAS1_Gateway
 SG_ EM2_HV_betriebsbereit : 58|1@1+ (1.0,0.0) [0.0|1] ""  ICAS1_Gateway

BO_ 2527679713 EM2_HYB_27: 8 LE2
 SG_ EM2_RtmWarnKommunikation : 12|3@1+ (1.0,0.0) [0.0|7] ""  Vector__XXX
 SG_ EM2_RtmWarnUeberdrehzahl : 15|3@1+ (1.0,0.0) [0.0|7] ""  ICAS1_Gateway
 SG_ EM2_RtmWarnUeberstrom : 18|3@1+ (1.0,0.0) [0.0|7] ""  ICAS1_Gateway
 SG_ EM2_RtmWarnTempEM : 21|3@1+ (1.0,0.0) [0.0|7] ""  ICAS1_Gateway
 SG_ EM2_RtmWarnTempPWR : 24|3@1+ (1.0,0.0) [0.0|7] ""  ICAS1_Gateway

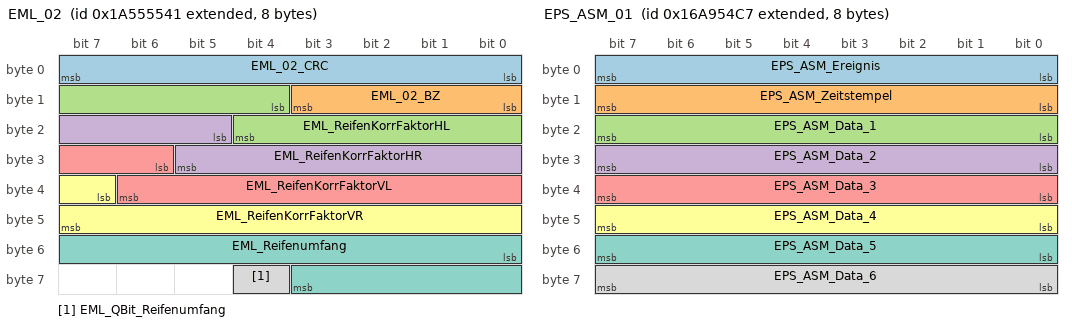
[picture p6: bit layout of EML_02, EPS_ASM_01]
BO_ 2589283649 EML_02: 8 ICAS1_Gateway
 SG_ EML_02_CRC : 0|8@1+ (1,0) [0|255] ""  Vector__XXX
 SG_ EML_02_BZ : 8|4@1+ (1,0) [0|15] ""  Vector__XXX
 SG_ EML_ReifenKorrFaktorHL : 12|9@1+ (0.00048828125,0.85) [0.85000000000|1.09853515625] ""  Vector__XXX
 SG_ EML_ReifenKorrFaktorHR : 21|9@1+ (0.00048828125,0.85) [0.85000000000|1.09853515625] ""  Vector__XXX
 SG_ EML_ReifenKorrFaktorVL : 30|9@1+ (0.00048828125,0.85) [0.85000000000|1.09853515625] ""  Vector__XXX
 SG_ EML_ReifenKorrFaktorVR : 39|9@1+ (0.00048828125,0.85) [0.85000000000|1.09853515625] ""  Vector__XXX
 SG_ EML_Reifenumfang : 48|12@1+ (1,0) [0|4095] "Unit_MilliMeter"  Motor_BEV
 SG_ EML_QBit_Reifenumfang : 60|1@1+ (1.0,0.0) [0.0|1] ""  Motor_BEV

BO_ 608 EML_07: 8 ICAS1_Gateway
 SG_ EML_AnzeigeGeschw : 54|10@1+ (0.32,0) [0.00|325.12] "Unit_KiloMeterPerHour"  Motor_BEV

BO_ 2589283751 Entfernungen_01: 8 ICAS1_KommunikationsServer
 SG_ KBI_Kilometerstand_HiRes_meter : 32|32@1+ (1,0) [0|4294967295] "Unit_Meter"  Motor_BEV

BO_ 2527679687 EPS_ASM_01: 8 ICAS1_Gateway
 SG_ EPS_ASM_Ereignis : 0|8@1+ (1,0) [1|254] "Unit_None"  Airbag
 SG_ EPS_ASM_Zeitstempel : 8|8@1+ (0.08,0) [0.00|20.32] "Unit_None"  Airbag
 SG_ EPS_ASM_Data_1 : 16|8@1+ (1,0) [0|255] "Unit_None"  Airbag
 SG_ EPS_ASM_Data_2 : 24|8@1+ (1,0) [0|255] "Unit_None"  Airbag
 SG_ EPS_ASM_Data_3 : 32|8@1+ (1,0) [0|255] "Unit_None"  Airbag
 SG_ EPS_ASM_Data_4 : 40|8@1+ (1,0) [0|255] "Unit_None"  Airbag
 SG_ EPS_ASM_Data_5 : 48|8@1+ (1,0) [0|255] "Unit_None"  Airbag
 SG_ EPS_ASM_Data_6 : 56|8@1+ (1,0) [0|255] "Unit_None"  Airbag

CM_ BO_ 1520 "ab MQB nach abgestimmten FLH Dimmung";
CM_ BO_ 1603 "ab MQB mit 8 Byte";

CM_ SG_ 514 DR_Aufbaubeschleunigung_HL "Aufbaubeschleunigungssensor
Auflösung 1g/300 
Wertebereich -1,6g..1,6g 
in m/s^2 übertragen.";
CM_ SG_ 514 DR_Aufbaubeschleunigung_HR "Aufbaubeschleunigungssensor
Auflösung 1g/300 
Wertebereich -1,6g..1,6g 
in m/s^2 übertragen.";
CM_ SG_ 514 DR_Aufbaubeschleunigung_VL "Aufbaubeschleunigungssensor
Auflösung 1g/300 
Wertebereich -1,6g..1,6g 
in m/s^2 übertragen.";
CM_ SG_ 514 DR_Aufbaubeschleunigung_VR "Aufbaubeschleunigungssensor
Auflösung 1g/300 
Wertebereich -1,6g..1,6g 
in m/s^2 übertragen.";
CM_ SG_ 514 DR_Drehwinkel_HL "Drehwinkelsensor zur Berechnung von Dämpferweg und  für LWR";
CM_ SG_ 514 DR_Drehwinkel_HR "Drehwinkelsensor zur Berechnung von Dämpferweg und  für LWR";
CM_ SG_ 514 DR_Drehwinkel_VL "Drehwinkelsensor zur Berechnung von Dämpferweg und  für LWR";
CM_ SG_ 514 DR_Drehwinkel_VR "Drehwinkelsensor zur Berechnung von Dämpferweg und  für LWR";
CM_ SG_ 514 DR_Drehwinkelsensortausch_HL "Zähler der bei jedem erkannten Drehwinkelsensortausch inkrementiert wird. Systeme die den Drehwinkelwert empfangen können notwendigen Inbetriebnahmefunktionen starten";
CM_ SG_ 514 DR_Drehwinkelsensortausch_HR "Zähler der bei jedem erkannten Drehwinkelsensortausch inkrementiert wird. Systeme die den Drehwinkelwert empfangen können notwendigen Inbetriebnahmefunktionen starten";
CM_ SG_ 514 DR_Drehwinkelsensortausch_VL "Zähler der bei jedem erkannten Drehwinkelsensortausch inkrementiert wird. Systeme die den Drehwinkelwert empfangen können notwendigen Inbetriebnahmefunktionen starten";
CM_ SG_ 514 DR_Drehwinkelsensortausch_VR "Zähler der bei jedem erkannten Drehwinkelsensortausch inkrementiert wird. Systeme die den Drehwinkelwert empfangen können notwendigen Inbetriebnahmefunktionen starten";
CM_ SG_ 514 DR_Funktionsstatus "Funktionsstatus des DCC_Gen3-SG";

CM_ SG_ 1485 DC_Abregelung_Temperatur "Abregelung aufgrund Übertemperatur im Leistungsteil (Hochtemperatur-Abregelung)";
CM_ SG_ 1485 DC_Derating "Signalisierung, ob der DC/DC-Wandler sich in der Abregelung befindet:
0=keine_Abregelung
1= Abregelung_Ursache_NV
2= Abregelung_Ursache_HV
3= Abregelung_Ursache_Temp
4= Abregelung_Ursache_Intern";
CM_ SG_ 1485 DC_Fehlerstatus "aktueller Fehlerstatus des DCDC-Wandler:";
CM_ SG_ 1485 DC_IstModus_02 "aktuelle Betriebsart des DC/DC Wandlers;
0: Standby; Kommunikation aktiv
1: HV_On_Vorladen
2: Tiefsetzen
3: Hochsetzen
4: Pruefimpuls_12V
5: interner Fehler DC/DC-Wandler / angeforderter Sollmodus kann nicht eingestellt werden
6: reserve
7: Initia";
CM_ SG_ 1485 DC_Kl30c_Status "Signalisierung des
Stecker-Zustandes der Klemme 30c (Service-Disconnect)

0=Init
1=geschlossen
2=offen
3=Fehler";
CM_ SG_ 1485 DC_Peakstrom_verfuegbar "Peakstrom verfügbar/nicht verfügbar";
CM_ SG_ 1485 DC_SollVolumenstrom "Für die Kühlung des DC/DC Wandler aktuell mindestens benötigter Kühlwasservolumenstrom";
CM_ SG_ 1485 DC_Status_Spgfreiheit_HV "HV DC/DC-Wandler Status HV-Spannungsfreiheit";
CM_ SG_ 1485 DC_Temperatur "Momentanwert: Temperatur des DC/DC Wandlers";
CM_ SG_ 1485 DC_Temperatur_Alarm "Temperatur-Alarm DCDC-Wandler RTM";
CM_ SG_ 1485 DCDC_03_CRC "Für MLB:
'Berechnung siehe Lastenheft 'Kommunikationsabsicherung für FlexRay und CAN''

Ab MQB und MLBevo:
'Berechnung siehe Lastenheft 'End-to-End Kommunikationsabsicherung''

Endwerte siehe Begleitdokument 'S-PDU Kennungsfolgen'";

CM_ SG_ 247 DC_Fehler_extern "Fehler/Abschaltung: DC/DC-Wandler ist aufgrund einer Umgebungsbedingung (z.B. HV-Spannung, NV-Spannung Kühlmitteltemperatur oder Systemfehler (ZK-Vorladung) ) nicht in der Lage geforderten Regelbetrieb einzuhalten.";
CM_ SG_ 247 DC_Fehler_intern "Fehler: DC/DC-Wandler ist aufgrund eines internen Hardware-Fehlers abgeschaltet";
CM_ SG_ 247 DC_IstLeistung_HV "Aktuelle Ist-Leistung des Bordnetzwandlers auf der HV-Seite. 

Tiefsetzen - positiv
Hochsetzen- negativ";
CM_ SG_ 247 DC_IstModus_02 "aktuelle Betriebsart des DC/DC Wandlers;
0: Standby; Kommunikation aktiv
1: HV_On_Vorladen
2: Tiefsetzen
3: Hochsetzen
4: Pruefimpuls_12V
5: interner Fehler DC/DC-Wandler / angeforderter Sollmodus kann nicht eingestellt werden
6: reserve
7: Initia";
CM_ SG_ 247 DC_IstStrom_HV "Momentanwert:  Strom aus dem Traktionsnetz in den DC/DC Wandler";
CM_ SG_ 247 DC_Status_EoHVL "Status der EoHVL am DCDC :
0=Init
1=Keine offene HV-Leitung erkannt
2=offene HV-Leitung erkannt
3=Fehler";
CM_ SG_ 247 DC_Status_Spgfreiheit "Status der Spannungsfreiheit für den Standalone DCDC-Wandler (HV-NV)
0=Init (ohne Funktion)
1=BMS Zwischenkreis spannungsfrei (U_Zwkr < 20V)
2=BMS Zwischenkreis nicht spannungsfrei (U_Zwkr >/= 25V, Hysterese)
3=Fehler (z.B. Fehler in der Sensorik)";
CM_ SG_ 247 DC_Vorladung_Status "Status der ZK-Vorladung:

=0, nicht_abgeschlossen
=1, abgeschlossen

DCDC-Wandler gibt Empfehlung für schließen der Schützen. 
HVK/BMS prüft die ZK-Spannung und entscheidet ob die Schütze geschlossen werden können.";
CM_ SG_ 247 DCDC_04_BZ "4bit Botschaftszähler, wird mit jeder Sendebotschaft inkrementiert";
CM_ SG_ 247 DCDC_04_CRC "Für MLB:
Berechnung siehe Lastenheft 'Kommunikationsabsicherung für FlexRay und CAN'
Ab MQB und MLBevo:
Berechnung siehe Lastenheft 'End-to-End Kommunikationsabsicherung'

Endwerte siehe Begleitdokument 'S-PDU Kennungsfolgen'";

CM_ SG_ 2549876269 Diag_Waehlhebel_Req_Data "UDS-Diagnose
ISO-TP Datenkanal - FID2NA
Request Funktion 0x06 Diagnosezugriff vom DK4-Master auf DK1/2-Knoten 0x62D";

CM_ SG_ 2550007341 Diag_Waehlhebel_Resp_Data "UDS-Diganose
ISO-TP Datenkanal - FID2NA
Response DK1/2-Knoten 0x62D an Funktion 0x06 Diagnosezugriff vom DK4-Master";

CM_ SG_ 1714 DGN_Verlernzaehler "wrap around 254 --> 0";
CM_ SG_ 1714 KBI_Kilometerstand "Fehler wird ausgegeben, falls Kilometerstand nicht restaurierbar
";
CM_ SG_ 1714 UH_Minute "0x3C- 0x3f = Werte ungültig";
CM_ SG_ 1714 UH_Monat "0x0D, 0xF =  Werte ungültig
0x0E = reserviert (nur VW)";
CM_ SG_ 1714 UH_Sekunde "0x3C- 0x3f = Werte ungültig";
CM_ SG_ 1714 UH_Stunde "0x18 - 0x1F = Werte ungültig";
CM_ SG_ 1714 UH_Tag "0x0: reserviert bei VW";
CM_ SG_ 1714 Uhrzeit_01_alt "
";
CM_ SG_ 1714 Vehicle_Driving_Cycle "Optimierung der Inbetriebnahme von Steuergeräten in einem Teilverbau in der Produktion.
Siehe VW80114. Signal bildet (durch eine Gateway-Funktion) den Inhalt des Signals OBD_Driving_Cycle ab.";

CM_ SG_ 851 DiETa_Car "Status Car-Taste";
CM_ SG_ 851 DiETa_Defrost_Taste "Max. Defrost AN/AUS";
CM_ SG_ 851 DiETa_FAS_Stufe "Status FAS-Taste";
CM_ SG_ 851 DiETa_FSH_Taste "Frontscheibenheizung AN/AUS";
CM_ SG_ 851 DiETa_HSH_Taste "Heckscheibenheizung AN/AUS";
CM_ SG_ 851 DiETa_Klima "Status Klimataste";
CM_ SG_ 851 DiETa_Lock_Unlock_Taste "Lock-/Unlock-Taste";
CM_ SG_ 851 DiETa_Mode "Status Modetaste";
CM_ SG_ 851 DiETa_Mode_roh "Erweitertes SIgnal zur Erfüllung der OBD-Relevanz für die Funktion Mode auf der DiETa";
CM_ SG_ 851 DiETa_PAO_OFF_Status "Istwert für LED 'OFF' in Anzeige Passenger Airbag On/Off";
CM_ SG_ 851 DiETa_PAO_ON_Status "Istwert für LED 'ON' in Anzeige Passenger Airbag On/Off";
CM_ SG_ 851 DiETa_Parken "Status Parkentaste";
CM_ SG_ 851 DiETa_Reserve_Byte2_4 "Vorhalt, Initialisierung mit '0'";
CM_ SG_ 851 DiETa_Reserve_Byte5_6 "Vorhalt, Initialisierung mit '0'";
CM_ SG_ 851 DiETa_Reserve_Byte6_3 "Vorhalt, Initialisierung mit '0'";
CM_ SG_ 851 DiETa_Reserve_Byte7 "Vorhalt, Initialisierung mit '0'";
CM_ SG_ 851 DiETa_Reserve_Byte8 "Vorhalt, Initialisierung mit '0'";
CM_ SG_ 851 DiETa_ResponseError "siehe LIN2.0-Specification
(Darf nicht über ein Fehlergueltigkeitsbit abgesichtert werden!)";
CM_ SG_ 851 DiETa_Status "Betriebszustand Direkteinstiegstasten";
CM_ SG_ 851 DiETa_Warnblink_Taste "Status Warnblinktaster";
CM_ SG_ 851 DiETas_01_BZ "4bit Botschaftszähler, wird mit jeder Sendebotschaft inkrementiert";
CM_ SG_ 851 DiETas_01_CRC "Für MLB:
Berechnung siehe Lastenheft 'Kommunikationsabsicherung für FlexRay und CAN'
Ab MQB und MLBevo:
Berechnung siehe Lastenheft 'End-to-End Kommunikationsabsicherung'

Endwerte siehe Begleitdokument 'S-PDU Kennungsfolgen'";

CM_ SG_ 1520 BCM1_Stellgroesse_Kl_58s "Rohwert Dimmpoti";
CM_ SG_ 1520 DI_Display_Nachtdesign "Für Displays sind oft  automatische Umschaltungen von Tag-/Nachtdesign vorgesehen.
Es gibt jedoch Zustände, an denen auch tagsüber das Abblendlicht eingeschaltet ist.
z.B. Dauerfahrlicht, Geschwindigkeitsabhängiges 'Licht-An-Bei-Autobahn', 'Regenlicht',";
CM_ SG_ 1520 DI_Fotosensor "Helligkeitswert Fotosensor
Für die Dimmung relevanter Wert zur Sensierung der Umgebungshelligkeit
Im Detail beschrieben im 'Funktionslastenheft Dimmung MQB'.";
CM_ SG_ 1520 DI_KL_58xd "Klemme 58xd Display- und Funktionsbeleuchtung
Mit der Klemme 58xd wird die Helligkeit der Display- und der Funktionsbeleuchtungen der Schalter gesteuert.
Im Detail beschrieben im 'Funktionslastenheft Dimmung MQB'.";
CM_ SG_ 1520 DI_KL_58xs "Suchbeleuchtung Schalter
EIN-AUS-Schaltalgorithmus der allgemeinen Schaltersuchbeleuchtung. 
Im Detail beschrieben im 'Funktionslastenheft Dimmung MQB'.
";
CM_ SG_ 1520 DI_KL_58xt "Timergesteuerte Suchbeleuchtung
Der EIN-AUS-Schaltalgorithmus für die vor- und nachlaufende Schaltersuchbeleuchtungen beim Ein- & Aussteigen; z.B.: Start/Stop-Taster.
Im Detail beschrieben im 'Funktionslastenheft Dimmung MQB'.";

CM_ SG_ 420 EA_01_BZ "EA Botschaftszähler";
CM_ SG_ 420 EA_01_CRC "Ab MQB und MLBevo:
'Berechnung siehe Lastenheft 'End-to-End Kommunikationsabsicherung''";
CM_ SG_ 420 EA_01_Sendestatus "Gibt den Sendestatus der Botschaft EA_01 an (notwendig für IL-Unterstützung)";
CM_ SG_ 420 EA_aktiv_laengs "Zeigt an, ob der Emergency Assist aktiv längs regelt.";
CM_ SG_ 420 EA_Anf_Prefill "Emergency Assist Anforderung an Prefill";
CM_ SG_ 420 EA_Anforderung_HMS "Emergency Assist Anforderung an HMS";
CM_ SG_ 420 EA_Funktionsstatus "Emergency Assist Funktionsstatus";
CM_ SG_ 420 EA_Gurtstraffer_Anf "Emergency Assist Anforderung reversibler Gurtstraffer";
CM_ SG_ 420 EA_Parken_beibehalten_HMS "Anforderung um automatisches lösen der Parkbremse zu verhindern";
CM_ SG_ 420 EA_Ruckfreigabe "Emergency Alert Freigabit für die Warnruck-Anforderung an das ESP";
CM_ SG_ 420 EA_Ruckstaerke "Anforderung der Ruckstaerke in schwach, mittel oder stark.";
CM_ SG_ 420 EA_Sollbeschleunigung "Emergency Assist Beschleunigungsanforderung";
CM_ SG_ 420 EA_Warnruckprofil "Emergency Assist Anforderung an ESP, welcher Ruck verwendet werden soll.";

CM_ SG_ 374 EBKV_03_BZ "4bit Botschaftszähler, wird mit jeder Sendebotschaft inkrementiert";
CM_ SG_ 374 EBKV_03_CRC "Für MLB:
Berechnung siehe Lastenheft 'Kommunikationsabsicherung für FlexRay und CAN'
Ab MQB und MLBevo:
Berechnung siehe Lastenheft 'End-to-End Kommunikationsabsicherung'

Endwerte siehe Begleitdokument 'S-PDU Kennungsfolgen'";
CM_ SG_ 374 EBKV_Activate_Fallback_ESP "Das Signal aktiviert im ESC die Rückfallebene.";
CM_ SG_ 374 EBKV_Anforderung_HMS "Anforderung an dem Haltemanager vom EBKV";
CM_ SG_ 374 EBKV_Aussteuerdruck "Das Signal übermittelt seitens des EBKVs frühzeitig den aktuellen, Fahrsituations-abhängig-variablen Brems-Vordruck an das ESC, bei dem die maximale Bremskraftunterstützung des EBVK erreicht ist. 
Über diesen übermittelten Druck-Wert erkennt das ESC den ";
CM_ SG_ 374 EBKV_Bremspedalweg "Bremspedalwert in Prozent. Der Wert ist Nullpunkt-abgeglichen.
Bremspedalweg von der EBKV eingelesen.";
CM_ SG_ 374 EBKV_Diagnose "eBKV im Diagnosemodus";
CM_ SG_ 374 EBKV_Fahrer_bremst "Fahrer will bremsen (Eintreterkennung).
Wird benötigt, um ACC oder GRA abzuschalten.";
CM_ SG_ 374 EBKV_Fahrer_bremst_deutlich "Rückmeldung des eBKVs, ob der Fahrer deutlich eine Bremsung wünscht.

Eine Aktivierung des Signals erfolgt bei 50N Pedalkraft (Druckäquivalent= 20bar, verwendet in AWV-Fkt.)
";
CM_ SG_ 374 EBKV_Kraftblending_Reserve "Maximale Druckdifferenz, die durch Pedalkraftblending noch simuliert werden kann";
CM_ SG_ 374 EBKV_OBD_Status "Ansteuerung der MIL-Lampe über den MIL-Master (Motorsteuergerät)";
CM_ SG_ 374 EBKV_QBit_Fahrer_bremst "
";
CM_ SG_ 374 EBKV_Restdruckabsenkung "Dieses Signal ermöglicht die Steuerung einer Routine zur Restdruckabsenkung aus dem eBKV heraus.
Die genaue Funktionsausprägung muss für das jeweilige Projekt festgelegt werden.";
CM_ SG_ 374 EBKV_Status_02 "eBKV Status Signal für 2 und 3 Box Systeme";
CM_ SG_ 374 EBKV_VMM_Sek_Notstopp_Status "Beschreibt den eBKV -seitigen Status zur Kommunikation mit der Steuerung der Notstopp Rückfallebene im ESC";
CM_ SG_ 374 EPB_Status_ext "Zustand des separat angeschlossenen Aktuators. Signal wird nur im MEB verwendet.";
CM_ SG_ 374 SBS_Anforderung_GE "Das Sekundärbremssystem (SBS) realisiert mit dieser Schnittstelle ein Sichern des Fahrzeugs. Nach einer Bremsung in den Stillstand über die direkte Verzögerungsschnittstelle wird hierüber die Getriebesperre angefordert.";

CM_ SG_ 1603 KBI_Einheit_Datum "Anzeigevariante des Datums";
CM_ SG_ 1603 KBI_Einheit_Druck "Einheit des Druckes";
CM_ SG_ 1603 KBI_Einheit_Masse "Einheit der Masse (Verwendung z.B. ASTA)";
CM_ SG_ 1603 KBI_Einheit_Sprache "Siehe BAP-Datenfestlegung UnitMaster";
CM_ SG_ 1603 KBI_Einheit_Streckenanz "Einheit der Streckenanzeige";
CM_ SG_ 1603 KBI_Einheit_Tacho "Information, ob es sich um Meilen- oder Kmh-Kombi handelt, Einheit des Tachos entspricht dem Zifferblatt, Grösse ist nicht veränderlich";
CM_ SG_ 1603 KBI_Einheit_Temp "Einheit der Temperatur";
CM_ SG_ 1603 KBI_Einheit_Uhrzeit "Anzeigevariante der Uhrzeit";
CM_ SG_ 1603 KBI_Einheit_Verbrauch "Einheit der Verbrauchs";
CM_ SG_ 1603 KBI_Einheit_Verbrauch_elektr "Einheit elektrischer Verbrauch";
CM_ SG_ 1603 KBI_Einheit_Verbrauch_Gas "Unterscheidung zwischen M3/h und kg/h für Komfortverbrauchsberechnung.";
CM_ SG_ 1603 KBI_Einheit_Volumen "Einheit des Volumens";
CM_ SG_ 1603 KBI_MFA_v_Einheit_02 "Einheit der Geschwindigkeit, die vom Fahrer im Car-Menü gewählt wurde. Veränderliche Grösse, im Gegensatz zur Einheit des Tachokranzes.

Redundant in der Einheiten_01 Botschaft definiert, um Konsistenz zur BAP-Festlegung zu haben.";

CM_ SG_ 192 EM1_01_BZ "4bit Botschaftszähler, wird mit jeder Sendebotschaft inkrementiert";
CM_ SG_ 192 EM1_01_CRC "Für MLB:
Berechnung siehe Lastenheft 'Kommunikationsabsicherung für FlexRay und CAN'
Ab MQB und MLBevo:
Berechnung siehe Lastenheft 'End-to-End Kommunikationsabsicherung'

Endwerte siehe Begleitdokument 'S-PDU Kennungsfolgen'";
CM_ SG_ 192 EM1_AR_aktiv "Ruckeldämpfer aktiv";
CM_ SG_ 192 EM1_ErwGrenzen_aktiv "Die absoluten Momentengrenzen sind für die Durchführung eines VKM-Starts ggf. aufgeweitet";
CM_ SG_ 192 EM1_Fehler_ElAntriebAbschaltung "Fehler: PWR befindet sich im aktiven Kurzschluss
alle vom EMS gesendeten Max- und Min-Momente und das aktuelle EM-Moment nehmen in diesem Zustand den Wert des für die aktuelle Drehzahl entsprechenden Schleppmoments der E-Maschine an";
CM_ SG_ 192 EM1_Fehler_Notabschaltung "Fehler: Leistungselektronik fordert Abschaltung des HV-Netzes wegen eines schweren Fehlers an";
CM_ SG_ 192 EM1_IstDrehzahl "Momentanwert: E-Maschinen Drehzahl";
CM_ SG_ 192 EM1_Istmodus "aktuelle Betriebsart der E-Maschine...
0: Standby; Kommunikation aktiv; PSM: Aktiver Kurzschluss eingenommen
1: Momentenreglung
2: Drehzahlregeung (interner Regelkreis)
3: Spannungsregelung
4: Drehzahlregelung (externer Regelkreis)
5: interner Inver";
CM_ SG_ 192 EM1_IstMoment "Momentanwert: E-Maschinen Moment";
CM_ SG_ 192 EM1_IstSpannung "Momentanwert: HV-Spannung am PWR";
CM_ SG_ 192 EM1_Max_Moment "maximal darstellbares Moment für eine im Funktionslastenheft definierte Dauer

Die Berechnung der Momentengrenzen wird projektspezifisch festgelegt";
CM_ SG_ 192 EM1_Max_Moment_Lim "Maximales Moment bei der momentanen Maschinendrehzahl, motorischer Betrieb, berechnet aus Abregelstrom MO_EMx_Max_Strom_Lim und aktueller Spannung";
CM_ SG_ 192 EM1_Min_Moment "minimal darstellbares Moment für eine im Funktionslastenheft definierte Dauer

Die Berechnung der Momentengrenzen wird projektspezifisch festgelegt
";
CM_ SG_ 192 EM1_Min_Moment_Lim "Minimales Moment bei der momentanen Maschinendrehzahl, generatorischer Betrieb, berechnet aus Abregelstrom MO_EMx_Min_Strom_Lim und aktueller Spannung";
CM_ SG_ 192 EM1_Mom_DrzEingriff "Wirksames Moment der EM zum Begrenzen der Drehzahl auf Drehzahlbegrenzung";
CM_ SG_ 192 EM1_Moment_AR_Eingriff "Momentanwert: Eingriffsmoment der Anti-Ruckel-Funktion im PWR";
CM_ SG_ 192 EM1_Status_DrzEingriff "Status ASR-Eingriff über EM-Regelung";
CM_ SG_ 192 EM1_Strom_HV "Momentanwert: HV DC-Strom des PWR";

CM_ SG_ 2463978673 EM1_AnlernenElMotor_Anf "Diagnoseanforderung von E-Maschine/PWR: Hybrid-Controller schaltet über MO_EM_Sollmodus=6 bzw. MY3_EM_modeReq=6 E-Maschine/PWR aktiv in den Kalibriermodus (Strategie muss sicherstellen, dass kein Moment bei der EM angefordert wird.)";
CM_ SG_ 2463978673 EM1_Fehler_AE "Ausgabe eines Fehlers in der Funktion aktive Entladung im PWR";
CM_ SG_ 2463978673 EM1_Fehler_ElAntriebFreilauf "Fehler: EM im Freilauf; Leistungselektronik fordert Begrenzung der maximalen Drehzahl an, um Überspannung im HV-Zwischenkreis zu vermeiden";
CM_ SG_ 2463978673 EM1_Fehler_Leistungsred "Eingeschränkte Leistungsfähigkeit auf Grund eins internen Fehlers";
CM_ SG_ 2463978673 EM1_Fehlerlampe_Anf "Anforderung der roten Hybrid-Warnlampe im Kombi";
CM_ SG_ 2463978673 EM1_Generator_Moment "Erforderliches generatorisches Moment zur Darstellung der elektrischen Wunschleistung bei der momentanen Maschinendrehzahl";
CM_ SG_ 2463978673 EM1_Max_LeistungMech_Sockel "Maximal mögliche mechanische Leistung oberhalb des Eckpunkts, bezogen auf die zugeteilte elektrische Leistung,";
CM_ SG_ 2463978673 EM1_Max_Moment_Gesamt "Maximal mögliches Moment bei der momentanen Maschinendrehzahl bezogen auf die im System verfügbare elektrische Gesamtleistung MO_EM1_Max_Leistung_Gesamt, motorischer Betrieb";
CM_ SG_ 2463978673 EM1_Max_Moment_Sockel "Maximal mögliches Moment bis zum Eckpunkt bezogen auf die zugeteilte elektrische Leistung, motorischer Betrieb";
CM_ SG_ 2463978673 EM1_MaxZul_Drehzahl "EM1_MaxZul_Drehzahl stellt die maximale Drehzahlgrenze für LE bzw. EM dar die im Freilauf zulässig ist. Für Drehzahlen größer dieser Grenze wird die LE zum Komponentenschutz unabhängig von der Kommandierung in den AKS umschalten.";
CM_ SG_ 2463978673 EM1_Min_LeistungMech_Sockel "Minimal mögliche mechanische Leistung oberhalb des Eckpunkts, bezogen auf die zugeteilte elektrische Leistung, generatorischer Betrieb";
CM_ SG_ 2463978673 EM1_Min_Moment_Gesamt "Minimal mögliches Moment bei der momentanen Maschinendrehzahl bezogen auf die vom System aufnehmbare elektrische Gesamtleistung MO_EM1_Min_Leistung_Gesamt, generatorischer Betrieb";
CM_ SG_ 2463978673 EM1_Min_Moment_Sockel "Minimal mögliches Moment bis zum Eckpunkt bezogen auf die zugeteilte elektrische Leistung, generatorischer Betrieb";
CM_ SG_ 2463978673 EM1_OBD_Lampe_Anf "In allen VW-/Audi-Fahrzeugen ist ein MIL-Master-Konzept umgesetzt. Dazu ermittelt jedes OBD-Steuergerät den eigenen MIL-Status. Eine MIL-Ansteuerung wird vom betroffenen OBD-Steuergerät per MIL-Request über CAN an den MIL-Master weitergegeben. Der MIL-Mas";
CM_ SG_ 2463978673 EM1_PerfInd_MaxLeistung "Performance-Indikator für die Verfügbarkeit der Maximalleistung";
CM_ SG_ 2463978673 EM1_PerfInd_MaxMoment "Performance-Indikator für die Verfügbarkeit des Maximalmoments";
CM_ SG_ 2463978673 EM1_PerfInd_Temperatur "Thermischer Performance-Indikator abhängig von Maschinen- und LE-Temperatur";
CM_ SG_ 2463978673 EM1_PWR_SollVolumenstrom "Für die Kühlung des PWR aktuell mindestens benötigter Kühlwasservolumenstrom";
CM_ SG_ 2463978673 EM1_Rekuperation "Rekuperation-Energie der EM getriebeintegriert";
CM_ SG_ 2463978673 EM1_Rekuperation_Ueberlauf "Rekuperationleistungssignal EM1_Rekuperation mindest 1x übergelaufen";
CM_ SG_ 2463978673 EM1_Status_EoHVL "Status der HV-Spannung am PWR für die Funktion EoHVL";
CM_ SG_ 2463978673 EM1_Status_Spgfreiheit "0 = Init (ohne Funktion)
1 = Leistungselektronik HV-Komponenten spannungsfrei (U_Zwkr < 20V)
2 = Leistungselektronik HV_Komponenten nicht spannungsfrei (U_Zwkr >= 20V)
3 = Fehler (z. B. Fehler in der Sensorik)";
CM_ SG_ 2463978673 EM1_Verbrauch "Antriebs-Energie der EM1 getriebeintegriert";
CM_ SG_ 2463978673 EM1_Verbrauch_Ueberlauf "Überlauf-Bit für das Signal EM1_Verbrauch.
Rekuperationleistungssignal mindest 1x übergelaufen;";
CM_ SG_ 2463978673 EM1_Warnlampe_Anf "Anforderung der gelben Hybrid-Warnlampe im Kombi";

CM_ SG_ 2589283657 EM1_EM_SollVolumenstrom "Für die Kühlung der E-Maschine aktuell mindestens benötigter Kühlwasservolumenstrom


MQB/MEB: funktional 500ms (Cyclic) Zykluszeit notwendig

MLBevo: funktional 50ms (OnChange) Zykluszeit notwendig";
CM_ SG_ 2589283657 EM1_Max_MechLeistung_nom "Maximale parametrierte Leistung des elektrischen Antriebs bestehend aus PWR und EM, interne Begrenzung";
CM_ SG_ 2589283657 EM1_Max_Moment_nom "Maximales parametriertes Moment des elektrischen Antriebs bestehend aus PWR und EM, interne Begrenzung";
CM_ SG_ 2589283657 EM1_SollVorlauftemperatur "Solltemperatur des Kühlmittels am Vorlauf des PWR";
CM_ SG_ 2589283657 EM1_Temperatur_EM "Temperatur der E-Maschine";
CM_ SG_ 2589283657 EM1_Temperatur_PWR "Momentanwert: Temperatur des PWR";

CM_ SG_ 184 EM1_Abregelung_Temperatur "Leistungsbegrenzung aufgrund Übertemperatur der E-Maschine / des PWR";
CM_ SG_ 184 EM1_AnlernenElMotor_Anf "Diagnoseanforderung von E-Maschine/PWR: Hybrid-Controller schaltet über MO_EM_Sollmodus=6 bzw. MY3_EM_modeReq=6 E-Maschine/PWR aktiv in den Kalibriermodus (Strategie muss sicherstellen, dass kein Moment bei der EM angefordert wird.)";
CM_ SG_ 184 EM1_AR_aktiv "Ruckeldämpfer aktiv";
CM_ SG_ 184 EM1_Eta_Sys "Instantaneous efficiency of electrical drive EM1 / Momentaner Wirkungsgrad elektrischer Antrieb EM1";
CM_ SG_ 184 EM1_Fehler_ElAntriebFreilauf_Anf "Wird gesetzt um den zwingenden Bedarf einer Umschaltung in den Freilauf anzuzeigen. Vergleiche Signal EM1_MaxZul_Drehzahl.";
CM_ SG_ 184 EM1_Freigabe_Info_WFS "WFS-Freigabeinformation";
CM_ SG_ 184 EM1_Freigabe_Verfallsinfo_WFS "WFS";
CM_ SG_ 184 EM1_HV_betriebsbereit "1: Ready_HV / 1: HV-Netz Spannung im Betriebsbereich";
CM_ SG_ 184 EM1_IstStrom "Momentanwert: Strom über PWR";
CM_ SG_ 184 EM1_Moment_HVVerbraucher "rechnerisch benötigtes Generator-Moment, um den Bedarf der el. Nebenverbraucher incl. Batterieladung abzudecken";
CM_ SG_ 184 EM1_Parken_WFS_Status "Status der Limitierung";
CM_ SG_ 184 EM1_Sperr_Info_WFS "WFS-Sperrinformation
";

CM_ SG_ 2527679712 EM1_RtmWarnKommunikation "Real Time Monitoring EM1 bus communication fault";
CM_ SG_ 2527679712 EM1_RtmWarnTempEM "RTM Signal over-temp warning EM1";
CM_ SG_ 2527679712 EM1_RtmWarnTempPWR "RTM Signal over-temp warning EM1-PWR";
CM_ SG_ 2527679712 EM1_RtmWarnUeberdrehzahl "RTM Signal overspeed warning EM1";
CM_ SG_ 2527679712 EM1_RtmWarnUeberstrom "RTM Signal over-current warning EM1";

CM_ SG_ 193 EM2_01_BZ "4bit Botschaftszähler, wird mit jeder Sendebotschaft inkrementiert";
CM_ SG_ 193 EM2_01_CRC "Für MLB:
Berechnung siehe Lastenheft 'Kommunikationsabsicherung für FlexRay und CAN'
Ab MQB und MLBevo:
Berechnung siehe Lastenheft 'End-to-End Kommunikationsabsicherung'

Endwerte siehe Begleitdokument 'S-PDU Kennungsfolgen'";
CM_ SG_ 193 EM2_AR_aktiv "Ruckeldämpfer aktiv";
CM_ SG_ 193 EM2_ErwGrenzen_aktiv "Die absoluten Momentengrenzen sind für die Durchführung eines VKM-Starts ggf. aufgeweitet";
CM_ SG_ 193 EM2_Fehler_ElAntriebAbschaltung "Fehler: PWR befindet sich im aktiven Kurzschluss
alle vom EMS gesendeten Max- und Min-Momente und das aktuelle EM-Moment nehmen in diesem Zustand den Wert des für die aktuelle Drehzahl entsprechenden Schleppmoments der E-Maschine an";
CM_ SG_ 193 EM2_Fehler_Notabschaltung "Fehler: Leistungselektronik fordert Abschaltung des HV-Netzes wegen eines schweren Fehlers an";
CM_ SG_ 193 EM2_IstDrehzahl "Momentanwert: E-Maschinen Drehzahl";
CM_ SG_ 193 EM2_Istmodus "aktuelle Betriebsart der E-Maschine...
0: Standby; Kommunikation aktiv; PSM: Aktiver Kurzschluss eingenommen
1: Momentenreglung
2: Drezahlregeung (interner Regelkreis)
3: Spannungsregelung
4: Drehzahlregelung (externer Regelkreis)
5: interner Invert";
CM_ SG_ 193 EM2_IstMoment "Momentanwert: E-Maschinen Moment";
CM_ SG_ 193 EM2_IstSpannung "Momentanwert: HV-Spannung am PWR";
CM_ SG_ 193 EM2_Max_Moment "maximal darstellbares Moment für eine im Funktionslastenheft definierte Dauer

Die Berechnung der Momentengrenzen wird projektspezifisch festgelegt
";
CM_ SG_ 193 EM2_Max_Moment_Lim "Maximales Moment bei der momentanen Maschinendrehzahl, motorischer Betrieb, berechnet aus Abregelstrom MO_EMx_Max_Strom_Lim und aktueller Spannung";
CM_ SG_ 193 EM2_Min_Moment "minimal darstellbares Moment für eine im Funktionslastenheft definierte Dauer

Die Berechnung der Momentengrenzen wird projektspezifisch festgelegt
";
CM_ SG_ 193 EM2_Min_Moment_Lim "Minimales Moment bei der momentanen Maschinendrehzahl, generatorischer Betrieb, berechnet aus Abregelstrom MO_EMx_Min_Strom_Lim und aktueller Spannung";
CM_ SG_ 193 EM2_Mom_DrzEingriff "Wirksames Moment der EM zum Begrenzen der Drehzahl auf Drehzahlbegrenzung";
CM_ SG_ 193 EM2_Moment_AR_Eingriff "Momentanwert: Eingriffsmoment der Anti-Ruckel-Funktion im PWR";
CM_ SG_ 193 EM2_Status_DrzEingriff "Status ASR-Eingriff über EM-Regelung";
CM_ SG_ 193 EM2_Strom_HV "Momentanwert: HV DC-Strom des PWR";

CM_ SG_ 2463978674 EM2_AnlernenElMotor_Anf "Diagnoseanforderung von E-Maschine/PWR: Hybrid-Controller schaltet über MO_EM_Sollmodus=6 bzw. MY3_EM_modeReq=6 E-Maschine/PWR aktiv in den Kalibriermodus (Strategie muss sicherstellen, dass kein Moment bei der EM angefordert wird.)";
CM_ SG_ 2463978674 EM2_Fehler_AE "Ausgabe eines Fehlers in der Funktion aktive Entladung im PWR";
CM_ SG_ 2463978674 EM2_Fehler_ElAntriebFreilauf "Fehler: EM im Freilauf; Leistungselektronik fordert Begrenzung der maximalen Drehzahl an, um Überspannung im HV-Zwischenkreis zu vermeiden";
CM_ SG_ 2463978674 EM2_Fehler_Leistungsred "Eingeschränkte Leistungsfähigkeit auf Grund eins internen Fehlers";
CM_ SG_ 2463978674 EM2_Fehlerlampe_Anf "Anforderung der roten Hybrid-Warnlampe im Kombi";
CM_ SG_ 2463978674 EM2_Generator_Moment "Erforderliches generatorisches Moment zur Darstellung der elektrischen Wunschleistung bei der momentanen Maschinendrehzahl";
CM_ SG_ 2463978674 EM2_Max_LeistungMech_Sockel "Maximal mögliche mechanische Leistung oberhalb des Eckpunkts, bezogen auf die zugeteilte elektrische Leistung,";
CM_ SG_ 2463978674 EM2_Max_Moment_Gesamt "Maximal mögliches Moment bei der momentanen Maschinendrehzahl bezogen auf die im System verfügbare elektrische Gesamtleistung MO_EM1_Max_Leistung_Gesamt, motorischer Betrieb";
CM_ SG_ 2463978674 EM2_Max_Moment_Sockel "Maximal mögliches Moment bis zum Eckpunkt bezogen auf die zugeteilte elektrische Leistung, motorischer Betrieb";
CM_ SG_ 2463978674 EM2_MaxZul_Drehzahl "EM2_MaxZul_Drehzahl stellt die maximale Drehzahlgrenze für LE bzw. EM dar die im Freilauf zulässig ist. Für Drehzahlen größer dieser Grenze wird die LE zum Komponentenschutz unabhängig von der Kommandierung in den AKS umschalten.";
CM_ SG_ 2463978674 EM2_Min_LeistungMech_Sockel "Minimal mögliche mechanische Leistung oberhalb des Eckpunkts, bezogen auf die zugeteilte elektrische Leistung, generatorischer Betrieb";
CM_ SG_ 2463978674 EM2_Min_Moment_Gesamt "Minimal mögliches Moment bei der momentanen Maschinendrehzahl bezogen auf die vom System aufnehmbare elektrische Gesamtleistung MO_EM1_Min_Leistung_Gesamt, generatorischer Betrieb";
CM_ SG_ 2463978674 EM2_Min_Moment_Sockel "Minimal mögliches Moment bis zum Eckpunkt bezogen auf die zugeteilte elektrische Leistung, generatorischer Betrieb";
CM_ SG_ 2463978674 EM2_OBD_Lampe_Anf "In allen VW-/Audi-Fahrzeugen ist ein MIL-Master-Konzept umgesetzt. Dazu ermittelt jedes OBD-Steuergerät den eigenen MIL-Status. Eine MIL-Ansteuerung wird vom betroffenen OBD-Steuergerät per MIL-Request über CAN an den MIL-Master weitergegeben. Der MIL-Mas";
CM_ SG_ 2463978674 EM2_PerfInd_MaxLeistung "Performance-Indikator für die Verfügbarkeit der Maximalleistung";
CM_ SG_ 2463978674 EM2_PerfInd_MaxMoment "Performance-Indikator für die Verfügbarkeit des Maximalmoments";
CM_ SG_ 2463978674 EM2_PerfInd_Temperatur "Thermischer Performance-Indikator abhängig von Maschinen- und LE-Temperatur";
CM_ SG_ 2463978674 EM2_PWR_SollVolumenstrom "Für die Kühlung des PWR aktuell mindestens benötigter Kühlwasservolumenstrom";
CM_ SG_ 2463978674 EM2_Rekuperation "Rekuperation-Energie der EM hinterachsintegriert";
CM_ SG_ 2463978674 EM2_Rekuperation_Ueberlauf "Rekuperationleistungssignal EM2_Rekuperation mindest 1x übergelaufen";
CM_ SG_ 2463978674 EM2_Status_EoHVL "Status der HV-Spannung am PWR für die Funktion EoHVL";
CM_ SG_ 2463978674 EM2_Status_Spgfreiheit "0 = Init (ohne Funktion)
1 = Leistungselektronik HV-Komponenten spannungsfrei (U_Zwkr < 20V)
2 = Leistungselektronik HV_Komponenten nicht spannungsfrei (U_Zwkr >= 20V)
3 = Fehler (z. B. Fehler in der Sensorik)";
CM_ SG_ 2463978674 EM2_Verbrauch "Antriebs-Energie der EM2 hinterachsintegriert";
CM_ SG_ 2463978674 EM2_Verbrauch_Ueberlauf "Überlauf-Bit für das Signal EM2_Verbrauch.
Rekuperationleistungssignal mindest 1x übergelaufen;";
CM_ SG_ 2463978674 EM2_Warnlampe_Anf "Anforderung der gelben Hybrid-Warnlampe im Kombi";

CM_ SG_ 2589283660 EM2_EM_SollVolumenstrom "Für die Kühlung der E-Maschine aktuell mindestens benötigter Kühlwasservolumenstrom


MQB/MEB: funktional 500ms (Cyclic) Zykluszeit notwendig

MLBevo: funktional 50ms (OnChange) Zykluszeit notwendig";
CM_ SG_ 2589283660 EM2_Max_MechLeistung_nom "Maximale parametrierte Leistung des elektrischen Antriebs bestehend aus PWR und EM, interne Begrenzung";
CM_ SG_ 2589283660 EM2_Max_Moment_nom "Maximales parametriertes Moment des elektrischen Antriebs bestehend aus PWR und EM, interne Begrenzung";
CM_ SG_ 2589283660 EM2_SollVorlauftemperatur "Solltemperatur des Kühlmittels am Vorlauf des PWR";
CM_ SG_ 2589283660 EM2_Temperatur_EM "Temperatur der E-Maschine";
CM_ SG_ 2589283660 EM2_Temperatur_PWR "Momentanwert: Temperatur des PWR";

CM_ SG_ 199 EM2_Abregelung_Temperatur "Leistungsbegrenzung aufgrund Übertemperatur der E-Maschine / des PWR";
CM_ SG_ 199 EM2_AnlernenElMotor_Anf "Diagnoseanforderung von E-Maschine/PWR: Hybrid-Controller schaltet über MO_EM_Sollmodus=6 bzw. MY3_EM_modeReq=6 E-Maschine/PWR aktiv in den Kalibriermodus (Strategie muss sicherstellen, dass kein Moment bei der EM angefordert wird.)";
CM_ SG_ 199 EM2_AR_aktiv "Ruckeldämpfer aktiv";
CM_ SG_ 199 EM2_Eta_Sys "Instantaneous efficiency of electrical drive EM2 / Momentaner Wirkungsgrad elektrischer Antrieb EM2";
CM_ SG_ 199 EM2_Fehler_ElAntriebFreilauf_Anf "Wird gesetzt um den zwingenden Bedarf einer Umschaltung in den Freilauf anzuzeigen. Vergleiche Signal EM1_MaxZul_Drehzahl.";
CM_ SG_ 199 EM2_Freigabe_Info_WFS "WFS-Freigabeinformation

";
CM_ SG_ 199 EM2_Freigabe_Verfallsinfo_WFS "WFS";
CM_ SG_ 199 EM2_HV_betriebsbereit "1: Ready_HV / 1: HV-Netz Spannung im Betriebsbereich";
CM_ SG_ 199 EM2_IstStrom "Momentanwert: Strom über PWR";
CM_ SG_ 199 EM2_Parken_WFS_Status "Status der Limitierung";
CM_ SG_ 199 EM2_Sperr_Info_WFS "WFS-Sperrinformation
";

CM_ SG_ 2527679713 EM2_RtmWarnKommunikation "Real Time Monitoring EM2 bus communication fault";
CM_ SG_ 2527679713 EM2_RtmWarnTempEM "RTM Signal over-temp warning EM2";
CM_ SG_ 2527679713 EM2_RtmWarnTempPWR "RTM Signal over-temp warning EM2-PWR";
CM_ SG_ 2527679713 EM2_RtmWarnUeberdrehzahl "RTM Signal overspeed warning EM2";
CM_ SG_ 2527679713 EM2_RtmWarnUeberstrom "RTM Signal over-current warning EM2";

CM_ SG_ 2589283649 EML_02_BZ "4bit Botschaftszähler, wird mit jeder Sendebotschaft inkrementiert";
CM_ SG_ 2589283649 EML_02_CRC "Für MLB:
Berechnung siehe Lastenheft 'Kommunikationsabsicherung für FlexRay und CAN'
Ab MQB und MLBevo:
Berechnung siehe Lastenheft 'End-to-End Kommunikationsabsicherung'

Endwerte siehe Begleitdokument 'S-PDU Kennungsfolgen'";
CM_ SG_ 2589283649 EML_QBit_Reifenumfang "QBit des mittleren Reifenumfangs. Gesetzt bei Ersatzwert, Init oder Fehler.";
CM_ SG_ 2589283649 EML_ReifenKorrFaktorHL "Korrekturfaktor Reifenumfang Hinten Links";
CM_ SG_ 2589283649 EML_ReifenKorrFaktorHR "Korrekturfaktor Reifenumfang Hinten Rechts";
CM_ SG_ 2589283649 EML_ReifenKorrFaktorVL "Korrekturfaktor Reifenumfang Vorne Links";
CM_ SG_ 2589283649 EML_ReifenKorrFaktorVR "Korrekturfaktor Reifenumfang Vorne Rechts";
CM_ SG_ 2589283649 EML_Reifenumfang "Mittlerer Reifenumfang des EML in Millimeter. Bei ASIL-Anforderungen ist die Fachabteilung zu kontaktieren.";

CM_ SG_ 608 EML_AnzeigeGeschw "Betrag des aktuellen Geschwindigkeitssignals in Fahrzeugbewegungsrichtung zur Anzeige nach Euro NCAP. Bei ASIL-Anforderungen ist die Fachabteilung zu kontaktieren.";

CM_ SG_ 2589283751 KBI_Kilometerstand_HiRes_meter "Höchauflösenderes Signal als KBI_Kilometerstand_HiRes um Umrechnung zu vermindern und eine höhere Auflösung als 0,1km zu erhalten.
Auflösung 1m / Bit
4 Byte länge (Doubleword)";

CM_ SG_ 2527679687 EPS_ASM_Data_1 "Diese Signal wird von mehreren Funktionen auf dem EPS-SG gemäß der ASM-Datendefinition befüllt und an den Assistenzsystemmonitor ASM gesendet";
CM_ SG_ 2527679687 EPS_ASM_Data_2 "Diese Signal wird von mehreren Funktionen auf dem EPS-SG gemäß der ASM-Datendefinition befüllt und an den Assistenzsystemmonitor ASM gesendet";
CM_ SG_ 2527679687 EPS_ASM_Data_3 "Diese Signal wird von mehreren Funktionen auf dem EPS-SG gemäß der ASM-Datendefinition befüllt und an den Assistenzsystemmonitor ASM gesendet";
CM_ SG_ 2527679687 EPS_ASM_Data_4 "Diese Signal wird von mehreren Funktionen auf dem EPS-SG gemäß der ASM-Datendefinition befüllt und an den Assistenzsystemmonitor ASM gesendet";
CM_ SG_ 2527679687 EPS_ASM_Data_5 "Diese Signal wird von mehreren Funktionen auf dem EPS-SG gemäß der ASM-Datendefinition befüllt und an den Assistenzsystemmonitor ASM gesendet";
CM_ SG_ 2527679687 EPS_ASM_Data_6 "Diese Signal wird von mehreren Funktionen auf dem EPS-SG gemäß der ASM-Datendefinition befüllt und an den Assistenzsystemmonitor ASM gesendet";
CM_ SG_ 2527679687 EPS_ASM_Ereignis "Dieses Signal definiert, welche Funktion und welche Art von Aktivität das Senden der Botschaft an den Assistenzsystemmonitor ASM veranlasst hat.";
CM_ SG_ 2527679687 EPS_ASM_Zeitstempel "Dieses Signal ermöglicht die zeitliche Zuordnung der von mehreren Funktionen auf dem EPS-SG an den Assistenzsystemmonitor ASM gesendeten Statusbotschaften.";
BA_DEF_REL_ BU_SG_REL_  "GenSigTimeoutTime" INT 0 65535;
BA_DEF_ BO_  "DiagRequest" ENUM "No", "Yes";
BA_DEF_ BO_  "DiagResponse" ENUM "No", "Yes";
BA_DEF_ BO_  "DiagState" ENUM "No", "Yes";
BA_DEF_ BO_  "GenMsgChkConstant" HEX 0 4095;
BA_DEF_ BO_  "GenMsgCycleTime" INT 0 65535;
BA_DEF_ BO_  "GenMsgCycleTimeFast" INT 0 65535;
BA_DEF_ BO_  "GenMsgDelayTime" INT 0 100000;
BA_DEF_ BO_  "GenMsgILSupport" ENUM "No", "Yes";
BA_DEF_ BO_  "GenMsgNrOfRepetition" INT 0 100;
BA_DEF_ BO_  "GenMsgPDUConstants" STRING;
BA_DEF_ BO_  "GenMsgSendType" ENUM "Cyclic", "not_used", "not_used", "not_used", "not_used", "not_used", "not_used", "IfActive", "NoMsgSendType";
BA_DEF_ BO_  "GenMsgStartDelayTime" INT 0 100000;
BA_DEF_ BO_  "NmMessage" ENUM "No", "Yes";
BA_DEF_ BO_  "NmhMessage" ENUM "No", "Yes";
BA_DEF_ BO_  "MsgType" ENUM "Application", "NM ", "NMH", "TP2.0", "ISO-TP ", "BAP", "EID", "KS";
BA_DEF_ BO_  "VAGTP20_API" HEX 0 255;
BA_DEF_ BO_  "VAGTP20_DynConnection" ENUM "No", "Yes";
BA_DEF_ BO_  "VAGTP20_DynSetup" ENUM "No", "Yes";
BA_DEF_ BO_  "VAGTP20_StatConnection" ENUM "No", "Yes";
BA_DEF_ BO_  "CANFD_BRS" ENUM "0", "1";
BA_DEF_ BO_  "VFrameFormat" ENUM "StandardCAN", "ExtendedCAN", "reserved", "reserved", "reserved", "reserved", "reserved", "reserved", "reserved", "reserved", "reserved", "reserved", "reserved", "reserved", "StandardCAN_FD", "ExtendedCAN_FD";
BA_DEF_ SG_  "GenSigActiveRepetitions" INT -2147483648 2147483647;
BA_DEF_ SG_  "GenSigInactiveValue" INT -2147483648 2147483647;
BA_DEF_ SG_  "GenSigSendType" ENUM "Cyclic", "OnWrite", "OnWriteWithRepetition", "OnChange", "OnChangeWithRepetition", "IfActive", "IfActiveWithRepetition", "NoSigSendType", "OnChangeAndIfActive", "OnChangeAndIfActiveWithRepetition";
BA_DEF_ SG_  "GenSigStartValue" INT -2147483648 2147483647;
BA_DEF_ SG_  "NWM-WakeupAllowed" ENUM "No", "Yes";
BA_DEF_ SG_  "GenSigFuncType" ENUM "NoFunction", "MsgCounter", "CRC-8", "XOR", "XOR-2", "DatedBit", "SW-Kl15", "CHK", "Constant", "Protocol", "CRC-8-SAE_J1850";
BA_DEF_ SG_  "GenSigSwitchedByIgnition" ENUM "No", "Yes";
BA_DEF_ SG_  "Fehlerwert" HEX 0 2147483647;
BA_DEF_ SG_  "GenSigMissingSourceValue" HEX 0 2147483647;
BA_DEF_DEF_REL_  "GenSigTimeoutTime" 0;
BA_DEF_DEF_  "DiagRequest" "No";
BA_DEF_DEF_  "DiagResponse" "No";
BA_DEF_DEF_  "DiagState" "No";
BA_DEF_DEF_  "GenMsgChkConstant" 0;
BA_DEF_DEF_  "GenMsgCycleTime" 0;
BA_DEF_DEF_  "GenMsgCycleTimeFast" 0;
BA_DEF_DEF_  "GenMsgDelayTime" 0;
BA_DEF_DEF_  "GenMsgILSupport" "No";
BA_DEF_DEF_  "GenMsgNrOfRepetition" 0;
BA_DEF_DEF_  "GenMsgPDUConstants" "";
BA_DEF_DEF_  "GenMsgSendType" "NoMsgSendType";
BA_DEF_DEF_  "GenMsgStartDelayTime" 0;
BA_DEF_DEF_  "NmMessage" "No";
BA_DEF_DEF_  "NmhMessage" "No";
BA_DEF_DEF_  "MsgType" "Application";
BA_DEF_DEF_  "VAGTP20_API" 0;
BA_DEF_DEF_  "VAGTP20_DynConnection" "No";
BA_DEF_DEF_  "VAGTP20_DynSetup" "No";
BA_DEF_DEF_  "VAGTP20_StatConnection" "No";
BA_DEF_DEF_  "CANFD_BRS" "1";
BA_DEF_DEF_  "VFrameFormat" "StandardCAN";
BA_DEF_DEF_  "GenSigActiveRepetitions" 0;
BA_DEF_DEF_  "GenSigInactiveValue" 0;
BA_DEF_DEF_  "GenSigSendType" "NoSigSendType";
BA_DEF_DEF_  "GenSigStartValue" 0;
BA_DEF_DEF_  "NWM-WakeupAllowed" "No";
BA_DEF_DEF_  "GenSigFuncType" "NoFunction";
BA_DEF_DEF_  "GenSigSwitchedByIgnition" "Yes";
BA_DEF_DEF_  "Fehlerwert" 0;
BA_DEF_DEF_  "GenSigMissingSourceValue" 0;
BA_ "GenMsgCycleTime" BO_ 514 20;
BA_ "GenMsgILSupport" BO_ 514 1;
BA_ "GenMsgSendType" BO_ 514 0;
BA_ "VFrameFormat" BO_ 514 14;
BA_ "GenMsgCycleTime" BO_ 1485 500;
BA_ "GenMsgCycleTimeFast" BO_ 1485 100;
BA_ "GenMsgDelayTime" BO_ 1485 50;
BA_ "GenMsgILSupport" BO_ 1485 1;
BA_ "GenMsgNrOfRepetition" BO_ 1485 5;
BA_ "GenMsgPDUConstants" BO_ 1485 "0x93,0x04,0x18,0x69,0xce,0x8f,0xb1,0x53,0x40,0x2d,0xe4,0xca,0x90,0x25,0x79,0x8c";
BA_ "GenMsgSendType" BO_ 1485 0;
BA_ "VFrameFormat" BO_ 1485 14;
BA_ "GenMsgCycleTime" BO_ 247 10;
BA_ "GenMsgILSupport" BO_ 247 1;
BA_ "GenMsgPDUConstants" BO_ 247 "0x5f,0xa0,0x44,0xd0,0x63,0x59,0x5b,0xa2,0x68,0x04,0x90,0x87,0x52,0x12,0xb4,0x9e";
BA_ "GenMsgSendType" BO_ 247 0;
BA_ "VFrameFormat" BO_ 247 14;
BA_ "MsgType" BO_ 2617027088 6;
BA_ "CANFD_BRS" BO_ 2617027088 0;
BA_ "VFrameFormat" BO_ 2617027088 1;
BA_ "MsgType" BO_ 2617027072 6;
BA_ "CANFD_BRS" BO_ 2617027072 0;
BA_ "VFrameFormat" BO_ 2617027072 1;
BA_ "MsgType" BO_ 2617027073 6;
BA_ "CANFD_BRS" BO_ 2617027073 0;
BA_ "VFrameFormat" BO_ 2617027073 1;
BA_ "MsgType" BO_ 2617027074 6;
BA_ "CANFD_BRS" BO_ 2617027074 0;
BA_ "VFrameFormat" BO_ 2617027074 1;
BA_ "MsgType" BO_ 2617027075 6;
BA_ "CANFD_BRS" BO_ 2617027075 0;
BA_ "VFrameFormat" BO_ 2617027075 1;
BA_ "MsgType" BO_ 2617027076 6;
BA_ "CANFD_BRS" BO_ 2617027076 0;
BA_ "VFrameFormat" BO_ 2617027076 1;
BA_ "MsgType" BO_ 2617027077 6;
BA_ "CANFD_BRS" BO_ 2617027077 0;
BA_ "VFrameFormat" BO_ 2617027077 1;
BA_ "MsgType" BO_ 2617027078 6;
BA_ "CANFD_BRS" BO_ 2617027078 0;
BA_ "VFrameFormat" BO_ 2617027078 1;
BA_ "MsgType" BO_ 2617027079 6;
BA_ "CANFD_BRS" BO_ 2617027079 0;
BA_ "VFrameFormat" BO_ 2617027079 1;
BA_ "MsgType" BO_ 2617027080 6;
BA_ "CANFD_BRS" BO_ 2617027080 0;
BA_ "VFrameFormat" BO_ 2617027080 1;
BA_ "MsgType" BO_ 2617027081 6;
BA_ "CANFD_BRS" BO_ 2617027081 0;
BA_ "VFrameFormat" BO_ 2617027081 1;
BA_ "MsgType" BO_ 2617027082 6;
BA_ "CANFD_BRS" BO_ 2617027082 0;
BA_ "VFrameFormat" BO_ 2617027082 1;
BA_ "MsgType" BO_ 2617027083 6;
BA_ "CANFD_BRS" BO_ 2617027083 0;
BA_ "VFrameFormat" BO_ 2617027083 1;
BA_ "MsgType" BO_ 2617154048 6;
BA_ "VFrameFormat" BO_ 2617154048 15;
BA_ "MsgType" BO_ 2617154049 6;
BA_ "VFrameFormat" BO_ 2617154049 15;
BA_ "MsgType" BO_ 2617154050 6;
BA_ "VFrameFormat" BO_ 2617154050 15;
BA_ "MsgType" BO_ 2617154051 6;
BA_ "VFrameFormat" BO_ 2617154051 15;
BA_ "MsgType" BO_ 2617154052 6;
BA_ "VFrameFormat" BO_ 2617154052 15;
BA_ "MsgType" BO_ 2617154053 6;
BA_ "VFrameFormat" BO_ 2617154053 15;
BA_ "DiagRequest" BO_ 2549876269 1;
BA_ "MsgType" BO_ 2549876269 4;
BA_ "VFrameFormat" BO_ 2549876269 15;
BA_ "DiagResponse" BO_ 2550007341 1;
BA_ "MsgType" BO_ 2550007341 4;
BA_ "VFrameFormat" BO_ 2550007341 15;
BA_ "GenMsgCycleTime" BO_ 1714 1000;
BA_ "GenMsgILSupport" BO_ 1714 1;
BA_ "GenMsgSendType" BO_ 1714 0;
BA_ "VFrameFormat" BO_ 1714 14;
BA_ "GenMsgCycleTime" BO_ 851 80;
BA_ "GenMsgILSupport" BO_ 851 1;
BA_ "GenMsgPDUConstants" BO_ 851 "0x3a,0x97,0x6b,0x70,0x1e,0x84,0xe1,0xb4,0xde,0xb8,0x03,0xe7,0x33,0x20,0x3f,0x7c";
BA_ "GenMsgSendType" BO_ 851 0;
BA_ "VFrameFormat" BO_ 851 14;
BA_ "GenMsgCycleTime" BO_ 1520 200;
BA_ "GenMsgDelayTime" BO_ 1520 50;
BA_ "GenMsgILSupport" BO_ 1520 1;
BA_ "GenMsgSendType" BO_ 1520 0;
BA_ "VFrameFormat" BO_ 1520 14;
BA_ "GenMsgCycleTime" BO_ 420 500;
BA_ "GenMsgCycleTimeFast" BO_ 420 20;
BA_ "GenMsgDelayTime" BO_ 420 20;
BA_ "GenMsgILSupport" BO_ 420 1;
BA_ "GenMsgNrOfRepetition" BO_ 420 5;
BA_ "GenMsgPDUConstants" BO_ 420 "0x69,0xbb,0x54,0xe6,0x4e,0x46,0x8d,0x7b,0xea,0x87,0xe9,0xb3,0x63,0xce,0xf8,0xbf";
BA_ "GenMsgSendType" BO_ 420 0;
BA_ "VFrameFormat" BO_ 420 14;
BA_ "GenMsgCycleTime" BO_ 374 20;
BA_ "GenMsgILSupport" BO_ 374 1;
BA_ "GenMsgPDUConstants" BO_ 374 "0x3c,0x60,0xeb,0x76,0x91,0x27,0x04,0x02,0xa4,0x3a,0x3f,0xa8,0x24,0x32,0x38,0x51";
BA_ "GenMsgSendType" BO_ 374 0;
BA_ "VFrameFormat" BO_ 374 14;
BA_ "GenMsgCycleTime" BO_ 1603 1000;
BA_ "GenMsgDelayTime" BO_ 1603 100;
BA_ "GenMsgILSupport" BO_ 1603 1;
BA_ "GenMsgSendType" BO_ 1603 0;
BA_ "VFrameFormat" BO_ 1603 14;
BA_ "GenMsgCycleTime" BO_ 192 10;
BA_ "GenMsgILSupport" BO_ 192 1;
BA_ "GenMsgPDUConstants" BO_ 192 "0x2f,0x44,0x72,0xd3,0x07,0xf2,0x39,0x09,0x8d,0x6f,0x57,0x20,0x37,0xf9,0x9b,0xfa";
BA_ "GenMsgSendType" BO_ 192 0;
BA_ "VFrameFormat" BO_ 192 14;
BA_ "GenMsgCycleTime" BO_ 2463978673 100;
BA_ "GenMsgILSupport" BO_ 2463978673 1;
BA_ "GenMsgSendType" BO_ 2463978673 0;
BA_ "VFrameFormat" BO_ 2463978673 15;
BA_ "GenMsgCycleTime" BO_ 2589283657 500;
BA_ "GenMsgILSupport" BO_ 2589283657 1;
BA_ "GenMsgSendType" BO_ 2589283657 0;
BA_ "VFrameFormat" BO_ 2589283657 15;
BA_ "GenMsgCycleTime" BO_ 184 500;
BA_ "GenMsgDelayTime" BO_ 184 20;
BA_ "GenMsgILSupport" BO_ 184 1;
BA_ "GenMsgSendType" BO_ 184 0;
BA_ "VFrameFormat" BO_ 184 14;
BA_ "GenMsgCycleTime" BO_ 2527679712 1000;
BA_ "GenMsgILSupport" BO_ 2527679712 1;
BA_ "GenMsgSendType" BO_ 2527679712 0;
BA_ "VFrameFormat" BO_ 2527679712 15;
BA_ "GenMsgCycleTime" BO_ 193 10;
BA_ "GenMsgILSupport" BO_ 193 1;
BA_ "GenMsgPDUConstants" BO_ 193 "0xd7,0x12,0x85,0x7e,0x0b,0x34,0xfa,0x16,0x7a,0x25,0x2d,0x8f,0x04,0x8e,0x5d,0x35";
BA_ "GenMsgSendType" BO_ 193 0;
BA_ "VFrameFormat" BO_ 193 14;
BA_ "GenMsgCycleTime" BO_ 2463978674 100;
BA_ "GenMsgILSupport" BO_ 2463978674 1;
BA_ "GenMsgSendType" BO_ 2463978674 0;
BA_ "VFrameFormat" BO_ 2463978674 15;
BA_ "GenMsgCycleTime" BO_ 2589283660 500;
BA_ "GenMsgILSupport" BO_ 2589283660 1;
BA_ "GenMsgSendType" BO_ 2589283660 0;
BA_ "VFrameFormat" BO_ 2589283660 15;
BA_ "GenMsgCycleTime" BO_ 199 500;
BA_ "GenMsgDelayTime" BO_ 199 20;
BA_ "GenMsgILSupport" BO_ 199 1;
BA_ "GenMsgSendType" BO_ 199 0;
BA_ "VFrameFormat" BO_ 199 14;
BA_ "GenMsgCycleTime" BO_ 2527679713 1000;
BA_ "GenMsgILSupport" BO_ 2527679713 1;
BA_ "GenMsgSendType" BO_ 2527679713 0;
BA_ "VFrameFormat" BO_ 2527679713 15;
BA_ "GenMsgCycleTime" BO_ 2589283649 200;
BA_ "GenMsgILSupport" BO_ 2589283649 1;
BA_ "GenMsgPDUConstants" BO_ 2589283649 "0x3e,0xb4,0x25,0xc1,0x31,0x1f,0xf1,0xd7,0xb1,0xbe,0xcc,0xe0,0x0f,0x46,0x51,0xb2";
BA_ "GenMsgSendType" BO_ 2589283649 0;
BA_ "VFrameFormat" BO_ 2589283649 15;
BA_ "GenMsgCycleTime" BO_ 608 50;
BA_ "GenMsgILSupport" BO_ 608 1;
BA_ "GenMsgSendType" BO_ 608 0;
BA_ "VFrameFormat" BO_ 608 14;
BA_ "GenMsgCycleTime" BO_ 2589283751 500;
BA_ "GenMsgILSupport" BO_ 2589283751 1;
BA_ "GenMsgSendType" BO_ 2589283751 0;
BA_ "VFrameFormat" BO_ 2589283751 15;
BA_ "GenMsgCycleTime" BO_ 2527679687 2000;
BA_ "GenMsgDelayTime" BO_ 2527679687 100;
BA_ "GenMsgILSupport" BO_ 2527679687 1;
BA_ "GenMsgSendType" BO_ 2527679687 0;
BA_ "VFrameFormat" BO_ 2527679687 15;
BA_ "GenSigSendType" SG_ 514 DR_Aufbaubeschleunigung_HL 0;
BA_ "GenSigStartValue" SG_ 514 DR_Aufbaubeschleunigung_HL 1022;
BA_ "GenSigSwitchedByIgnition" SG_ 514 DR_Aufbaubeschleunigung_HL 0;
BA_ "Fehlerwert" SG_ 514 DR_Aufbaubeschleunigung_HL 1023;
BA_ "GenSigSendType" SG_ 514 DR_Aufbaubeschleunigung_HR 0;
BA_ "GenSigStartValue" SG_ 514 DR_Aufbaubeschleunigung_HR 1022;
BA_ "GenSigSwitchedByIgnition" SG_ 514 DR_Aufbaubeschleunigung_HR 0;
BA_ "Fehlerwert" SG_ 514 DR_Aufbaubeschleunigung_HR 1023;
BA_ "GenSigSendType" SG_ 514 DR_Aufbaubeschleunigung_VL 0;
BA_ "GenSigStartValue" SG_ 514 DR_Aufbaubeschleunigung_VL 1022;
BA_ "GenSigSwitchedByIgnition" SG_ 514 DR_Aufbaubeschleunigung_VL 0;
BA_ "Fehlerwert" SG_ 514 DR_Aufbaubeschleunigung_VL 1023;
BA_ "GenSigSendType" SG_ 514 DR_Aufbaubeschleunigung_VR 0;
BA_ "GenSigStartValue" SG_ 514 DR_Aufbaubeschleunigung_VR 1022;
BA_ "GenSigSwitchedByIgnition" SG_ 514 DR_Aufbaubeschleunigung_VR 0;
BA_ "Fehlerwert" SG_ 514 DR_Aufbaubeschleunigung_VR 1023;
BA_ "GenSigSendType" SG_ 514 DR_Drehwinkel_HL 0;
BA_ "GenSigStartValue" SG_ 514 DR_Drehwinkel_HL 4094;
BA_ "GenSigSwitchedByIgnition" SG_ 514 DR_Drehwinkel_HL 0;
BA_ "Fehlerwert" SG_ 514 DR_Drehwinkel_HL 4095;
BA_ "GenSigSendType" SG_ 514 DR_Drehwinkel_HR 0;
BA_ "GenSigStartValue" SG_ 514 DR_Drehwinkel_HR 4094;
BA_ "GenSigSwitchedByIgnition" SG_ 514 DR_Drehwinkel_HR 0;
BA_ "Fehlerwert" SG_ 514 DR_Drehwinkel_HR 4095;
BA_ "GenSigSendType" SG_ 514 DR_Drehwinkel_VL 0;
BA_ "GenSigStartValue" SG_ 514 DR_Drehwinkel_VL 4094;
BA_ "GenSigSwitchedByIgnition" SG_ 514 DR_Drehwinkel_VL 0;
BA_ "Fehlerwert" SG_ 514 DR_Drehwinkel_VL 4095;
BA_ "GenSigSendType" SG_ 514 DR_Drehwinkel_VR 0;
BA_ "GenSigStartValue" SG_ 514 DR_Drehwinkel_VR 4094;
BA_ "GenSigSwitchedByIgnition" SG_ 514 DR_Drehwinkel_VR 0;
BA_ "Fehlerwert" SG_ 514 DR_Drehwinkel_VR 4095;
BA_ "GenSigSendType" SG_ 514 DR_Drehwinkelsensortausch_HL 0;
BA_ "GenSigSwitchedByIgnition" SG_ 514 DR_Drehwinkelsensortausch_HL 0;
BA_ "GenSigSendType" SG_ 514 DR_Drehwinkelsensortausch_HR 0;
BA_ "GenSigSwitchedByIgnition" SG_ 514 DR_Drehwinkelsensortausch_HR 0;
BA_ "GenSigSendType" SG_ 514 DR_Drehwinkelsensortausch_VL 0;
BA_ "GenSigSwitchedByIgnition" SG_ 514 DR_Drehwinkelsensortausch_VL 0;
BA_ "GenSigSendType" SG_ 514 DR_Drehwinkelsensortausch_VR 0;
BA_ "GenSigSwitchedByIgnition" SG_ 514 DR_Drehwinkelsensortausch_VR 0;
BA_ "GenSigSendType" SG_ 514 DR_Funktionsstatus 0;
BA_ "GenSigSwitchedByIgnition" SG_ 514 DR_Funktionsstatus 0;
BA_ "GenSigSendType" SG_ 1485 DC_Abregelung_Temperatur 3;
BA_ "GenSigSwitchedByIgnition" SG_ 1485 DC_Abregelung_Temperatur 0;
BA_ "GenSigSendType" SG_ 1485 DC_Derating 3;
BA_ "GenSigSwitchedByIgnition" SG_ 1485 DC_Derating 0;
BA_ "GenSigSendType" SG_ 1485 DC_Fehlerstatus 3;
BA_ "GenSigStartValue" SG_ 1485 DC_Fehlerstatus 7;
BA_ "GenSigSwitchedByIgnition" SG_ 1485 DC_Fehlerstatus 0;
BA_ "GenSigSendType" SG_ 1485 DC_IstModus_02 3;
BA_ "GenSigStartValue" SG_ 1485 DC_IstModus_02 7;
BA_ "GenSigSwitchedByIgnition" SG_ 1485 DC_IstModus_02 0;
BA_ "Fehlerwert" SG_ 1485 DC_IstModus_02 5;
BA_ "GenSigSendType" SG_ 1485 DC_Kl30c_Status 4;
BA_ "GenSigSwitchedByIgnition" SG_ 1485 DC_Kl30c_Status 0;
BA_ "Fehlerwert" SG_ 1485 DC_Kl30c_Status 3;
BA_ "GenSigSendType" SG_ 1485 DC_Peakstrom_verfuegbar 3;
BA_ "GenSigSwitchedByIgnition" SG_ 1485 DC_Peakstrom_verfuegbar 0;
BA_ "GenSigSendType" SG_ 1485 DC_SollVolumenstrom 0;
BA_ "GenSigStartValue" SG_ 1485 DC_SollVolumenstrom 62;
BA_ "GenSigSwitchedByIgnition" SG_ 1485 DC_SollVolumenstrom 0;
BA_ "Fehlerwert" SG_ 1485 DC_SollVolumenstrom 63;
BA_ "GenSigSendType" SG_ 1485 DC_Status_Spgfreiheit_HV 3;
BA_ "GenSigSwitchedByIgnition" SG_ 1485 DC_Status_Spgfreiheit_HV 0;
BA_ "GenSigSendType" SG_ 1485 DC_Temperatur 0;
BA_ "GenSigStartValue" SG_ 1485 DC_Temperatur 254;
BA_ "GenSigSwitchedByIgnition" SG_ 1485 DC_Temperatur 0;
BA_ "Fehlerwert" SG_ 1485 DC_Temperatur 255;
BA_ "GenSigSendType" SG_ 1485 DC_Temperatur_Alarm 0;
BA_ "GenSigSwitchedByIgnition" SG_ 1485 DC_Temperatur_Alarm 0;
BA_ "Fehlerwert" SG_ 1485 DC_Temperatur_Alarm 1;
BA_ "GenSigSendType" SG_ 1485 DCDC_03_BZ 0;
BA_ "GenSigFuncType" SG_ 1485 DCDC_03_BZ 1;
BA_ "GenSigSwitchedByIgnition" SG_ 1485 DCDC_03_BZ 0;
BA_ "GenSigSendType" SG_ 1485 DCDC_03_CRC 0;
BA_ "GenSigFuncType" SG_ 1485 DCDC_03_CRC 2;
BA_ "GenSigSwitchedByIgnition" SG_ 1485 DCDC_03_CRC 0;
BA_ "GenSigSendType" SG_ 247 DC_Fehler_extern 0;
BA_ "GenSigSwitchedByIgnition" SG_ 247 DC_Fehler_extern 0;
BA_ "Fehlerwert" SG_ 247 DC_Fehler_extern 1;
BA_ "GenSigSendType" SG_ 247 DC_Fehler_intern 0;
BA_ "GenSigSwitchedByIgnition" SG_ 247 DC_Fehler_intern 0;
BA_ "GenSigSendType" SG_ 247 DC_IstLeistung_HV 0;
BA_ "GenSigStartValue" SG_ 247 DC_IstLeistung_HV 1022;
BA_ "GenSigSwitchedByIgnition" SG_ 247 DC_IstLeistung_HV 0;
BA_ "Fehlerwert" SG_ 247 DC_IstLeistung_HV 1023;
BA_ "GenSigSendType" SG_ 247 DC_IstModus_02 0;
BA_ "GenSigStartValue" SG_ 247 DC_IstModus_02 7;
BA_ "GenSigSwitchedByIgnition" SG_ 247 DC_IstModus_02 0;
BA_ "Fehlerwert" SG_ 247 DC_IstModus_02 5;
BA_ "GenSigSendType" SG_ 247 DC_IstStrom_HV 0;
BA_ "GenSigStartValue" SG_ 247 DC_IstStrom_HV 1022;
BA_ "GenSigSwitchedByIgnition" SG_ 247 DC_IstStrom_HV 0;
BA_ "Fehlerwert" SG_ 247 DC_IstStrom_HV 1023;
BA_ "GenSigSendType" SG_ 247 DC_Status_EoHVL 0;
BA_ "GenSigSwitchedByIgnition" SG_ 247 DC_Status_EoHVL 0;
BA_ "Fehlerwert" SG_ 247 DC_Status_EoHVL 3;
BA_ "GenSigSendType" SG_ 247 DC_Status_Spgfreiheit 0;
BA_ "GenSigSwitchedByIgnition" SG_ 247 DC_Status_Spgfreiheit 0;
BA_ "GenSigSendType" SG_ 247 DC_Vorladung_Status 0;
BA_ "GenSigSwitchedByIgnition" SG_ 247 DC_Vorladung_Status 0;
BA_ "GenSigSendType" SG_ 247 DCDC_04_BZ 0;
BA_ "GenSigFuncType" SG_ 247 DCDC_04_BZ 1;
BA_ "GenSigSwitchedByIgnition" SG_ 247 DCDC_04_BZ 0;
BA_ "GenSigSendType" SG_ 247 DCDC_04_CRC 0;
BA_ "GenSigFuncType" SG_ 247 DCDC_04_CRC 2;
BA_ "GenSigSwitchedByIgnition" SG_ 247 DCDC_04_CRC 0;
BA_ "GenSigSwitchedByIgnition" SG_ 2617027088 DEV_Airbag_ASM_01_Data 0;
BA_ "GenSigSwitchedByIgnition" SG_ 2617027072 DEV_Airbag_Resp_00_Data 0;
BA_ "GenSigSwitchedByIgnition" SG_ 2617027073 DEV_Airbag_Resp_01_Data 0;
BA_ "GenSigSwitchedByIgnition" SG_ 2617027074 DEV_Airbag_Resp_02_Data 0;
BA_ "GenSigSwitchedByIgnition" SG_ 2617027075 DEV_Airbag_Resp_03_Data 0;
BA_ "GenSigSwitchedByIgnition" SG_ 2617027076 DEV_Airbag_Resp_04_Data 0;
BA_ "GenSigSwitchedByIgnition" SG_ 2617027077 DEV_Airbag_Resp_05_Data 0;
BA_ "GenSigSwitchedByIgnition" SG_ 2617027078 DEV_Airbag_Resp_06_Data 0;
BA_ "GenSigSwitchedByIgnition" SG_ 2617027079 DEV_Airbag_Resp_07_Data 0;
BA_ "GenSigSwitchedByIgnition" SG_ 2617027080 DEV_Airbag_Resp_08_Data 0;
BA_ "GenSigSwitchedByIgnition" SG_ 2617027081 DEV_Airbag_Resp_09_Data 0;
BA_ "GenSigSwitchedByIgnition" SG_ 2617027082 DEV_Airbag_Resp_10_Data 0;
BA_ "GenSigSwitchedByIgnition" SG_ 2617027083 DEV_Airbag_Resp_11_Data 0;
BA_ "GenSigSwitchedByIgnition" SG_ 2617154048 DEV_Waehlhebel_Resp_00_Data 0;
BA_ "GenSigSwitchedByIgnition" SG_ 2617154049 DEV_Waehlhebel_Resp_01_Data 0;
BA_ "GenSigSwitchedByIgnition" SG_ 2617154050 DEV_Waehlhebel_Resp_02_Data 0;
BA_ "GenSigSwitchedByIgnition" SG_ 2617154051 DEV_Waehlhebel_Resp_03_Data 0;
BA_ "GenSigSwitchedByIgnition" SG_ 2617154052 DEV_Waehlhebel_Resp_04_Data 0;
BA_ "GenSigSwitchedByIgnition" SG_ 2617154053 DEV_Waehlhebel_Resp_05_Data 0;
BA_ "GenSigSendType" SG_ 2549876269 Diag_Waehlhebel_Req_Data 3;
BA_ "GenSigSwitchedByIgnition" SG_ 2549876269 Diag_Waehlhebel_Req_Data 0;
BA_ "GenSigSendType" SG_ 2550007341 Diag_Waehlhebel_Resp_Data 3;
BA_ "GenSigSwitchedByIgnition" SG_ 2550007341 Diag_Waehlhebel_Resp_Data 0;
BA_ "GenSigSendType" SG_ 1714 DGN_Verlernzaehler 0;
BA_ "GenSigSwitchedByIgnition" SG_ 1714 DGN_Verlernzaehler 0;
BA_ "GenSigSendType" SG_ 1714 KBI_Kilometerstand 0;
BA_ "GenSigStartValue" SG_ 1714 KBI_Kilometerstand 1048574;
BA_ "GenSigSwitchedByIgnition" SG_ 1714 KBI_Kilometerstand 0;
BA_ "Fehlerwert" SG_ 1714 KBI_Kilometerstand 1048575;
BA_ "GenSigSendType" SG_ 1714 Kombi_02_alt 0;
BA_ "GenSigStartValue" SG_ 1714 Kombi_02_alt 1;
BA_ "GenSigFuncType" SG_ 1714 Kombi_02_alt 5;
BA_ "GenSigSwitchedByIgnition" SG_ 1714 Kombi_02_alt 0;
BA_ "GenSigSendType" SG_ 1714 UH_Jahr 0;
BA_ "GenSigSwitchedByIgnition" SG_ 1714 UH_Jahr 0;
BA_ "GenSigSendType" SG_ 1714 UH_Minute 0;
BA_ "GenSigSwitchedByIgnition" SG_ 1714 UH_Minute 0;
BA_ "GenSigSendType" SG_ 1714 UH_Monat 0;
BA_ "GenSigSwitchedByIgnition" SG_ 1714 UH_Monat 0;
BA_ "Fehlerwert" SG_ 1714 UH_Monat 15;
BA_ "GenSigSendType" SG_ 1714 UH_Sekunde 0;
BA_ "GenSigSwitchedByIgnition" SG_ 1714 UH_Sekunde 0;
BA_ "GenSigSendType" SG_ 1714 UH_Stunde 0;
BA_ "GenSigSwitchedByIgnition" SG_ 1714 UH_Stunde 0;
BA_ "GenSigSendType" SG_ 1714 UH_Tag 0;
BA_ "GenSigSwitchedByIgnition" SG_ 1714 UH_Tag 0;
BA_ "GenSigSendType" SG_ 1714 Uhrzeit_01_alt 0;
BA_ "GenSigStartValue" SG_ 1714 Uhrzeit_01_alt 1;
BA_ "GenSigFuncType" SG_ 1714 Uhrzeit_01_alt 5;
BA_ "GenSigSwitchedByIgnition" SG_ 1714 Uhrzeit_01_alt 0;
BA_ "GenSigSendType" SG_ 1714 Vehicle_Driving_Cycle 0;
BA_ "GenSigSwitchedByIgnition" SG_ 1714 Vehicle_Driving_Cycle 0;
BA_ "GenSigSendType" SG_ 851 DiETa_Car 0;
BA_ "GenSigSwitchedByIgnition" SG_ 851 DiETa_Car 0;
BA_ "Fehlerwert" SG_ 851 DiETa_Car 3;
BA_ "GenSigSendType" SG_ 851 DiETa_Defrost_Taste 0;
BA_ "GenSigSwitchedByIgnition" SG_ 851 DiETa_Defrost_Taste 0;
BA_ "Fehlerwert" SG_ 851 DiETa_Defrost_Taste 3;
BA_ "GenSigSendType" SG_ 851 DiETa_FAS_Stufe 0;
BA_ "GenSigSwitchedByIgnition" SG_ 851 DiETa_FAS_Stufe 0;
BA_ "Fehlerwert" SG_ 851 DiETa_FAS_Stufe 3;
BA_ "GenSigSendType" SG_ 851 DiETa_FSH_Taste 0;
BA_ "GenSigSwitchedByIgnition" SG_ 851 DiETa_FSH_Taste 0;
BA_ "Fehlerwert" SG_ 851 DiETa_FSH_Taste 3;
BA_ "GenSigSendType" SG_ 851 DiETa_HSH_Taste 0;
BA_ "GenSigSwitchedByIgnition" SG_ 851 DiETa_HSH_Taste 0;
BA_ "Fehlerwert" SG_ 851 DiETa_HSH_Taste 3;
BA_ "GenSigSendType" SG_ 851 DiETa_Klima 0;
BA_ "GenSigSwitchedByIgnition" SG_ 851 DiETa_Klima 0;
BA_ "Fehlerwert" SG_ 851 DiETa_Klima 3;
BA_ "GenSigSendType" SG_ 851 DiETa_Lock_Unlock_Taste 0;
BA_ "GenSigSwitchedByIgnition" SG_ 851 DiETa_Lock_Unlock_Taste 0;
BA_ "Fehlerwert" SG_ 851 DiETa_Lock_Unlock_Taste 7;
BA_ "GenSigSendType" SG_ 851 DiETa_Mode 0;
BA_ "GenSigSwitchedByIgnition" SG_ 851 DiETa_Mode 0;
BA_ "Fehlerwert" SG_ 851 DiETa_Mode 3;
BA_ "GenSigSendType" SG_ 851 DiETa_Mode_roh 0;
BA_ "GenSigSwitchedByIgnition" SG_ 851 DiETa_Mode_roh 0;
BA_ "GenSigSendType" SG_ 851 DiETa_PAO_OFF_Status 0;
BA_ "GenSigSwitchedByIgnition" SG_ 851 DiETa_PAO_OFF_Status 0;
BA_ "GenSigSendType" SG_ 851 DiETa_PAO_ON_Status 0;
BA_ "GenSigSwitchedByIgnition" SG_ 851 DiETa_PAO_ON_Status 0;
BA_ "GenSigSendType" SG_ 851 DiETa_Parken 0;
BA_ "GenSigSwitchedByIgnition" SG_ 851 DiETa_Parken 0;
BA_ "Fehlerwert" SG_ 851 DiETa_Parken 3;
BA_ "GenSigSendType" SG_ 851 DiETa_Reserve_Byte2_4 0;
BA_ "GenSigSwitchedByIgnition" SG_ 851 DiETa_Reserve_Byte2_4 0;
BA_ "GenSigSendType" SG_ 851 DiETa_Reserve_Byte5_6 0;
BA_ "GenSigSwitchedByIgnition" SG_ 851 DiETa_Reserve_Byte5_6 0;
BA_ "GenSigSendType" SG_ 851 DiETa_Reserve_Byte6_3 0;
BA_ "GenSigSwitchedByIgnition" SG_ 851 DiETa_Reserve_Byte6_3 0;
BA_ "GenSigSendType" SG_ 851 DiETa_Reserve_Byte7 0;
BA_ "GenSigSwitchedByIgnition" SG_ 851 DiETa_Reserve_Byte7 0;
BA_ "GenSigSendType" SG_ 851 DiETa_Reserve_Byte8 0;
BA_ "GenSigSwitchedByIgnition" SG_ 851 DiETa_Reserve_Byte8 0;
BA_ "GenSigSendType" SG_ 851 DiETa_ResponseError 0;
BA_ "GenSigSwitchedByIgnition" SG_ 851 DiETa_ResponseError 0;
BA_ "Fehlerwert" SG_ 851 DiETa_ResponseError 1;
BA_ "GenSigSendType" SG_ 851 DiETa_Status 0;
BA_ "GenSigStartValue" SG_ 851 DiETa_Status 2;
BA_ "GenSigSwitchedByIgnition" SG_ 851 DiETa_Status 0;
BA_ "GenSigSendType" SG_ 851 DiETa_Warnblink_Taste 0;
BA_ "GenSigSwitchedByIgnition" SG_ 851 DiETa_Warnblink_Taste 0;
BA_ "Fehlerwert" SG_ 851 DiETa_Warnblink_Taste 3;
BA_ "GenSigSendType" SG_ 851 DiETas_01_BZ 0;
BA_ "GenSigFuncType" SG_ 851 DiETas_01_BZ 1;
BA_ "GenSigSwitchedByIgnition" SG_ 851 DiETas_01_BZ 0;
BA_ "GenSigSendType" SG_ 851 DiETas_01_CRC 0;
BA_ "GenSigFuncType" SG_ 851 DiETas_01_CRC 2;
BA_ "GenSigSwitchedByIgnition" SG_ 851 DiETas_01_CRC 0;
BA_ "GenSigSendType" SG_ 1520 BCM1_Stellgroesse_Kl_58s 3;
BA_ "GenSigStartValue" SG_ 1520 BCM1_Stellgroesse_Kl_58s 126;
BA_ "GenSigSwitchedByIgnition" SG_ 1520 BCM1_Stellgroesse_Kl_58s 0;
BA_ "Fehlerwert" SG_ 1520 BCM1_Stellgroesse_Kl_58s 127;
BA_ "GenSigSendType" SG_ 1520 DI_Display_Nachtdesign 3;
BA_ "GenSigSwitchedByIgnition" SG_ 1520 DI_Display_Nachtdesign 0;
BA_ "GenSigSendType" SG_ 1520 DI_Fotosensor 3;
BA_ "GenSigSwitchedByIgnition" SG_ 1520 DI_Fotosensor 0;
BA_ "GenSigSendType" SG_ 1520 DI_KL_58xd 3;
BA_ "GenSigStartValue" SG_ 1520 DI_KL_58xd 254;
BA_ "GenSigSwitchedByIgnition" SG_ 1520 DI_KL_58xd 0;
BA_ "Fehlerwert" SG_ 1520 DI_KL_58xd 255;
BA_ "GenSigSendType" SG_ 1520 DI_KL_58xs 3;
BA_ "GenSigStartValue" SG_ 1520 DI_KL_58xs 126;
BA_ "GenSigSwitchedByIgnition" SG_ 1520 DI_KL_58xs 0;
BA_ "Fehlerwert" SG_ 1520 DI_KL_58xs 127;
BA_ "GenSigSendType" SG_ 1520 DI_KL_58xt 3;
BA_ "GenSigStartValue" SG_ 1520 DI_KL_58xt 126;
BA_ "GenSigSwitchedByIgnition" SG_ 1520 DI_KL_58xt 0;
BA_ "Fehlerwert" SG_ 1520 DI_KL_58xt 127;
BA_ "GenSigSendType" SG_ 420 EA_01_BZ 0;
BA_ "GenSigFuncType" SG_ 420 EA_01_BZ 1;
BA_ "GenSigSendType" SG_ 420 EA_01_CRC 0;
BA_ "GenSigFuncType" SG_ 420 EA_01_CRC 2;
BA_ "GenSigSendType" SG_ 420 EA_01_Sendestatus 6;
BA_ "GenSigSwitchedByIgnition" SG_ 420 EA_01_Sendestatus 0;
BA_ "GenSigSendType" SG_ 420 EA_aktiv_laengs 0;
BA_ "GenSigSendType" SG_ 420 EA_Anf_Prefill 0;
BA_ "GenSigSendType" SG_ 420 EA_Anforderung_HMS 0;
BA_ "GenSigSendType" SG_ 420 EA_Funktionsstatus 0;
BA_ "GenSigSendType" SG_ 420 EA_Gurtstraffer_Anf 3;
BA_ "GenSigSendType" SG_ 420 EA_Parken_beibehalten_HMS 0;
BA_ "GenSigStartValue" SG_ 420 EA_Parken_beibehalten_HMS 2;
BA_ "Fehlerwert" SG_ 420 EA_Parken_beibehalten_HMS 3;
BA_ "GenSigSendType" SG_ 420 EA_Ruckfreigabe 0;
BA_ "GenSigSendType" SG_ 420 EA_Ruckstaerke 0;
BA_ "GenSigSendType" SG_ 420 EA_Sollbeschleunigung 0;
BA_ "GenSigStartValue" SG_ 420 EA_Sollbeschleunigung 2046;
BA_ "Fehlerwert" SG_ 420 EA_Sollbeschleunigung 2047;
BA_ "GenSigSendType" SG_ 420 EA_Warnruckprofil 0;
BA_ "GenSigSendType" SG_ 374 EBKV_03_BZ 0;
BA_ "GenSigFuncType" SG_ 374 EBKV_03_BZ 1;
BA_ "GenSigSwitchedByIgnition" SG_ 374 EBKV_03_BZ 0;
BA_ "GenSigSendType" SG_ 374 EBKV_03_CRC 0;
BA_ "GenSigFuncType" SG_ 374 EBKV_03_CRC 2;
BA_ "GenSigSwitchedByIgnition" SG_ 374 EBKV_03_CRC 0;
BA_ "GenSigSendType" SG_ 374 EBKV_Activate_Fallback_ESP 0;
BA_ "GenSigSwitchedByIgnition" SG_ 374 EBKV_Activate_Fallback_ESP 0;
BA_ "GenSigSendType" SG_ 374 EBKV_Anforderung_HMS 0;
BA_ "GenSigSwitchedByIgnition" SG_ 374 EBKV_Anforderung_HMS 0;
BA_ "GenSigSendType" SG_ 374 EBKV_Aussteuerdruck 0;
BA_ "GenSigStartValue" SG_ 374 EBKV_Aussteuerdruck 254;
BA_ "GenSigSwitchedByIgnition" SG_ 374 EBKV_Aussteuerdruck 0;
BA_ "Fehlerwert" SG_ 374 EBKV_Aussteuerdruck 255;
BA_ "GenSigSendType" SG_ 374 EBKV_Bremspedalweg 0;
BA_ "GenSigSwitchedByIgnition" SG_ 374 EBKV_Bremspedalweg 0;
BA_ "Fehlerwert" SG_ 374 EBKV_Bremspedalweg 255;
BA_ "GenSigSendType" SG_ 374 EBKV_Diagnose 0;
BA_ "GenSigSwitchedByIgnition" SG_ 374 EBKV_Diagnose 0;
BA_ "GenSigSendType" SG_ 374 EBKV_Fahrer_bremst 0;
BA_ "GenSigSwitchedByIgnition" SG_ 374 EBKV_Fahrer_bremst 0;
BA_ "GenSigSendType" SG_ 374 EBKV_Fahrer_bremst_deutlich 0;
BA_ "GenSigSwitchedByIgnition" SG_ 374 EBKV_Fahrer_bremst_deutlich 0;
BA_ "GenSigSendType" SG_ 374 EBKV_Kraftblending_Reserve 0;
BA_ "GenSigStartValue" SG_ 374 EBKV_Kraftblending_Reserve 254;
BA_ "GenSigSwitchedByIgnition" SG_ 374 EBKV_Kraftblending_Reserve 0;
BA_ "Fehlerwert" SG_ 374 EBKV_Kraftblending_Reserve 255;
BA_ "GenSigSendType" SG_ 374 EBKV_OBD_Status 0;
BA_ "GenSigSwitchedByIgnition" SG_ 374 EBKV_OBD_Status 0;
BA_ "GenSigSendType" SG_ 374 EBKV_QBit_Fahrer_bremst 0;
BA_ "GenSigStartValue" SG_ 374 EBKV_QBit_Fahrer_bremst 1;
BA_ "GenSigSwitchedByIgnition" SG_ 374 EBKV_QBit_Fahrer_bremst 0;
BA_ "GenSigSendType" SG_ 374 EBKV_Restdruckabsenkung 0;
BA_ "GenSigSwitchedByIgnition" SG_ 374 EBKV_Restdruckabsenkung 0;
BA_ "GenSigSendType" SG_ 374 EBKV_Status_02 0;
BA_ "GenSigSwitchedByIgnition" SG_ 374 EBKV_Status_02 0;
BA_ "GenSigSendType" SG_ 374 EBKV_VMM_Sek_Notstopp_Status 0;
BA_ "GenSigSwitchedByIgnition" SG_ 374 EBKV_VMM_Sek_Notstopp_Status 0;
BA_ "GenSigSendType" SG_ 374 EPB_Status_ext 0;
BA_ "GenSigStartValue" SG_ 374 EPB_Status_ext 6;
BA_ "GenSigSwitchedByIgnition" SG_ 374 EPB_Status_ext 0;
BA_ "GenSigSendType" SG_ 374 SBS_Anforderung_GE 0;
BA_ "GenSigSwitchedByIgnition" SG_ 374 SBS_Anforderung_GE 0;
BA_ "GenSigSendType" SG_ 1603 KBI_Einheit_Datum 3;
BA_ "GenSigSwitchedByIgnition" SG_ 1603 KBI_Einheit_Datum 0;
BA_ "GenSigSendType" SG_ 1603 KBI_Einheit_Druck 3;
BA_ "GenSigSwitchedByIgnition" SG_ 1603 KBI_Einheit_Druck 0;
BA_ "GenSigSendType" SG_ 1603 KBI_Einheit_Masse 3;
BA_ "GenSigSwitchedByIgnition" SG_ 1603 KBI_Einheit_Masse 0;
BA_ "GenSigSendType" SG_ 1603 KBI_Einheit_Sprache 3;
BA_ "GenSigSwitchedByIgnition" SG_ 1603 KBI_Einheit_Sprache 0;
BA_ "GenSigSendType" SG_ 1603 KBI_Einheit_Streckenanz 3;
BA_ "GenSigSwitchedByIgnition" SG_ 1603 KBI_Einheit_Streckenanz 0;
BA_ "GenSigSendType" SG_ 1603 KBI_Einheit_Tacho 3;
BA_ "GenSigSwitchedByIgnition" SG_ 1603 KBI_Einheit_Tacho 0;
BA_ "GenSigSendType" SG_ 1603 KBI_Einheit_Temp 3;
BA_ "GenSigSwitchedByIgnition" SG_ 1603 KBI_Einheit_Temp 0;
BA_ "GenSigSendType" SG_ 1603 KBI_Einheit_Uhrzeit 3;
BA_ "GenSigSwitchedByIgnition" SG_ 1603 KBI_Einheit_Uhrzeit 0;
BA_ "GenSigSendType" SG_ 1603 KBI_Einheit_Verbrauch 3;
BA_ "GenSigSwitchedByIgnition" SG_ 1603 KBI_Einheit_Verbrauch 0;
BA_ "GenSigSendType" SG_ 1603 KBI_Einheit_Verbrauch_elektr 3;
BA_ "GenSigSwitchedByIgnition" SG_ 1603 KBI_Einheit_Verbrauch_elektr 0;
BA_ "GenSigSendType" SG_ 1603 KBI_Einheit_Verbrauch_Gas 3;
BA_ "GenSigSwitchedByIgnition" SG_ 1603 KBI_Einheit_Verbrauch_Gas 0;
BA_ "GenSigSendType" SG_ 1603 KBI_Einheit_Volumen 3;
BA_ "GenSigSwitchedByIgnition" SG_ 1603 KBI_Einheit_Volumen 0;
BA_ "GenSigSendType" SG_ 1603 KBI_MFA_v_Einheit_02 3;
BA_ "GenSigSwitchedByIgnition" SG_ 1603 KBI_MFA_v_Einheit_02 0;
BA_ "GenSigSendType" SG_ 192 EM1_01_BZ 0;
BA_ "GenSigFuncType" SG_ 192 EM1_01_BZ 1;
BA_ "GenSigSwitchedByIgnition" SG_ 192 EM1_01_BZ 0;
BA_ "GenSigSendType" SG_ 192 EM1_01_CRC 0;
BA_ "GenSigFuncType" SG_ 192 EM1_01_CRC 2;
BA_ "GenSigSwitchedByIgnition" SG_ 192 EM1_01_CRC 0;
BA_ "GenSigSendType" SG_ 192 EM1_AR_aktiv 0;
BA_ "GenSigSwitchedByIgnition" SG_ 192 EM1_AR_aktiv 0;
BA_ "GenSigSendType" SG_ 192 EM1_ErwGrenzen_aktiv 0;
BA_ "GenSigSwitchedByIgnition" SG_ 192 EM1_ErwGrenzen_aktiv 0;
BA_ "GenSigSendType" SG_ 192 EM1_Fehler_ElAntriebAbschaltung 0;
BA_ "GenSigSwitchedByIgnition" SG_ 192 EM1_Fehler_ElAntriebAbschaltung 0;
BA_ "GenSigSendType" SG_ 192 EM1_Fehler_Notabschaltung 0;
BA_ "GenSigSwitchedByIgnition" SG_ 192 EM1_Fehler_Notabschaltung 0;
BA_ "Fehlerwert" SG_ 192 EM1_Fehler_Notabschaltung 1;
BA_ "GenSigSendType" SG_ 192 EM1_IstDrehzahl 0;
BA_ "GenSigStartValue" SG_ 192 EM1_IstDrehzahl 32766;
BA_ "GenSigSwitchedByIgnition" SG_ 192 EM1_IstDrehzahl 0;
BA_ "Fehlerwert" SG_ 192 EM1_IstDrehzahl 32767;
BA_ "GenSigSendType" SG_ 192 EM1_Istmodus 0;
BA_ "GenSigStartValue" SG_ 192 EM1_Istmodus 15;
BA_ "GenSigSwitchedByIgnition" SG_ 192 EM1_Istmodus 0;
BA_ "GenSigSendType" SG_ 192 EM1_IstMoment 0;
BA_ "GenSigStartValue" SG_ 192 EM1_IstMoment 4094;
BA_ "GenSigSwitchedByIgnition" SG_ 192 EM1_IstMoment 0;
BA_ "Fehlerwert" SG_ 192 EM1_IstMoment 4095;
BA_ "GenSigSendType" SG_ 192 EM1_IstSpannung 0;
BA_ "GenSigStartValue" SG_ 192 EM1_IstSpannung 4094;
BA_ "GenSigSwitchedByIgnition" SG_ 192 EM1_IstSpannung 0;
BA_ "Fehlerwert" SG_ 192 EM1_IstSpannung 4095;
BA_ "GenSigSendType" SG_ 192 EM1_Max_Moment 0;
BA_ "GenSigStartValue" SG_ 192 EM1_Max_Moment 2046;
BA_ "GenSigSwitchedByIgnition" SG_ 192 EM1_Max_Moment 0;
BA_ "Fehlerwert" SG_ 192 EM1_Max_Moment 2047;
BA_ "GenSigSendType" SG_ 192 EM1_Max_Moment_Lim 0;
BA_ "GenSigStartValue" SG_ 192 EM1_Max_Moment_Lim 2046;
BA_ "GenSigSwitchedByIgnition" SG_ 192 EM1_Max_Moment_Lim 0;
BA_ "Fehlerwert" SG_ 192 EM1_Max_Moment_Lim 2047;
BA_ "GenSigSendType" SG_ 192 EM1_Min_Moment 0;
BA_ "GenSigStartValue" SG_ 192 EM1_Min_Moment 2046;
BA_ "GenSigSwitchedByIgnition" SG_ 192 EM1_Min_Moment 0;
BA_ "Fehlerwert" SG_ 192 EM1_Min_Moment 2047;
BA_ "GenSigSendType" SG_ 192 EM1_Min_Moment_Lim 0;
BA_ "GenSigStartValue" SG_ 192 EM1_Min_Moment_Lim 2046;
BA_ "GenSigSwitchedByIgnition" SG_ 192 EM1_Min_Moment_Lim 0;
BA_ "Fehlerwert" SG_ 192 EM1_Min_Moment_Lim 2047;
BA_ "GenSigSendType" SG_ 192 EM1_Mom_DrzEingriff 0;
BA_ "GenSigStartValue" SG_ 192 EM1_Mom_DrzEingriff 2046;
BA_ "GenSigSwitchedByIgnition" SG_ 192 EM1_Mom_DrzEingriff 0;
BA_ "Fehlerwert" SG_ 192 EM1_Mom_DrzEingriff 2047;
BA_ "GenSigSendType" SG_ 192 EM1_Moment_AR_Eingriff 0;
BA_ "GenSigStartValue" SG_ 192 EM1_Moment_AR_Eingriff 4094;
BA_ "GenSigSwitchedByIgnition" SG_ 192 EM1_Moment_AR_Eingriff 0;
BA_ "Fehlerwert" SG_ 192 EM1_Moment_AR_Eingriff 4095;
BA_ "GenSigSendType" SG_ 192 EM1_Status_DrzEingriff 0;
BA_ "GenSigSwitchedByIgnition" SG_ 192 EM1_Status_DrzEingriff 0;
BA_ "Fehlerwert" SG_ 192 EM1_Status_DrzEingriff 3;
BA_ "GenSigSendType" SG_ 192 EM1_Strom_HV 0;
BA_ "GenSigStartValue" SG_ 192 EM1_Strom_HV 4094;
BA_ "GenSigSwitchedByIgnition" SG_ 192 EM1_Strom_HV 0;
BA_ "Fehlerwert" SG_ 192 EM1_Strom_HV 4095;
BA_ "GenSigSendType" SG_ 2463978673 EM1_AnlernenElMotor_Anf 0;
BA_ "GenSigSwitchedByIgnition" SG_ 2463978673 EM1_AnlernenElMotor_Anf 0;
BA_ "GenSigSendType" SG_ 2463978673 EM1_Fehler_AE 0;
BA_ "GenSigSwitchedByIgnition" SG_ 2463978673 EM1_Fehler_AE 0;
BA_ "GenSigSendType" SG_ 2463978673 EM1_Fehler_ElAntriebFreilauf 0;
BA_ "GenSigSwitchedByIgnition" SG_ 2463978673 EM1_Fehler_ElAntriebFreilauf 0;
BA_ "GenSigSendType" SG_ 2463978673 EM1_Fehler_Leistungsred 0;
BA_ "GenSigSwitchedByIgnition" SG_ 2463978673 EM1_Fehler_Leistungsred 0;
BA_ "GenSigSendType" SG_ 2463978673 EM1_Fehlerlampe_Anf 0;
BA_ "GenSigSwitchedByIgnition" SG_ 2463978673 EM1_Fehlerlampe_Anf 0;
BA_ "GenSigSendType" SG_ 2463978673 EM1_Generator_Moment 0;
BA_ "GenSigStartValue" SG_ 2463978673 EM1_Generator_Moment 1022;
BA_ "GenSigSwitchedByIgnition" SG_ 2463978673 EM1_Generator_Moment 0;
BA_ "Fehlerwert" SG_ 2463978673 EM1_Generator_Moment 1023;
BA_ "GenSigSendType" SG_ 2463978673 EM1_Max_LeistungMech_Sockel 0;
BA_ "GenSigStartValue" SG_ 2463978673 EM1_Max_LeistungMech_Sockel 8190;
BA_ "GenSigSwitchedByIgnition" SG_ 2463978673 EM1_Max_LeistungMech_Sockel 0;
BA_ "Fehlerwert" SG_ 2463978673 EM1_Max_LeistungMech_Sockel 8191;
BA_ "GenSigSendType" SG_ 2463978673 EM1_Max_Moment_Gesamt 0;
BA_ "GenSigStartValue" SG_ 2463978673 EM1_Max_Moment_Gesamt 2046;
BA_ "GenSigSwitchedByIgnition" SG_ 2463978673 EM1_Max_Moment_Gesamt 0;
BA_ "Fehlerwert" SG_ 2463978673 EM1_Max_Moment_Gesamt 2047;
BA_ "GenSigSendType" SG_ 2463978673 EM1_Max_Moment_Sockel 0;
BA_ "GenSigStartValue" SG_ 2463978673 EM1_Max_Moment_Sockel 2046;
BA_ "GenSigSwitchedByIgnition" SG_ 2463978673 EM1_Max_Moment_Sockel 0;
BA_ "Fehlerwert" SG_ 2463978673 EM1_Max_Moment_Sockel 2047;
BA_ "GenSigSendType" SG_ 2463978673 EM1_MaxZul_Drehzahl 0;
BA_ "GenSigStartValue" SG_ 2463978673 EM1_MaxZul_Drehzahl 254;
BA_ "GenSigSwitchedByIgnition" SG_ 2463978673 EM1_MaxZul_Drehzahl 0;
BA_ "Fehlerwert" SG_ 2463978673 EM1_MaxZul_Drehzahl 255;
BA_ "GenSigSendType" SG_ 2463978673 EM1_Min_LeistungMech_Sockel 0;
BA_ "GenSigStartValue" SG_ 2463978673 EM1_Min_LeistungMech_Sockel 8190;
BA_ "GenSigSwitchedByIgnition" SG_ 2463978673 EM1_Min_LeistungMech_Sockel 0;
BA_ "Fehlerwert" SG_ 2463978673 EM1_Min_LeistungMech_Sockel 8191;
BA_ "GenSigSendType" SG_ 2463978673 EM1_Min_Moment_Gesamt 0;
BA_ "GenSigStartValue" SG_ 2463978673 EM1_Min_Moment_Gesamt 2046;
BA_ "GenSigSwitchedByIgnition" SG_ 2463978673 EM1_Min_Moment_Gesamt 0;
BA_ "Fehlerwert" SG_ 2463978673 EM1_Min_Moment_Gesamt 2047;
BA_ "GenSigSendType" SG_ 2463978673 EM1_Min_Moment_Sockel 0;
BA_ "GenSigStartValue" SG_ 2463978673 EM1_Min_Moment_Sockel 2046;
BA_ "GenSigSwitchedByIgnition" SG_ 2463978673 EM1_Min_Moment_Sockel 0;
BA_ "Fehlerwert" SG_ 2463978673 EM1_Min_Moment_Sockel 2047;
BA_ "GenSigSendType" SG_ 2463978673 EM1_OBD_Lampe_Anf 0;
BA_ "GenSigSwitchedByIgnition" SG_ 2463978673 EM1_OBD_Lampe_Anf 0;
BA_ "GenSigSendType" SG_ 2463978673 EM1_PerfInd_MaxLeistung 0;
BA_ "GenSigStartValue" SG_ 2463978673 EM1_PerfInd_MaxLeistung 1022;
BA_ "GenSigSwitchedByIgnition" SG_ 2463978673 EM1_PerfInd_MaxLeistung 0;
BA_ "GenSigSendType" SG_ 2463978673 EM1_PerfInd_MaxMoment 0;
BA_ "GenSigStartValue" SG_ 2463978673 EM1_PerfInd_MaxMoment 1022;
BA_ "GenSigSwitchedByIgnition" SG_ 2463978673 EM1_PerfInd_MaxMoment 0;
BA_ "GenSigSendType" SG_ 2463978673 EM1_PerfInd_Temperatur 0;
BA_ "GenSigStartValue" SG_ 2463978673 EM1_PerfInd_Temperatur 254;
BA_ "GenSigSwitchedByIgnition" SG_ 2463978673 EM1_PerfInd_Temperatur 0;
BA_ "GenSigSendType" SG_ 2463978673 EM1_PWR_SollVolumenstrom 0;
BA_ "GenSigStartValue" SG_ 2463978673 EM1_PWR_SollVolumenstrom 62;
BA_ "GenSigSwitchedByIgnition" SG_ 2463978673 EM1_PWR_SollVolumenstrom 0;
BA_ "Fehlerwert" SG_ 2463978673 EM1_PWR_SollVolumenstrom 63;
BA_ "GenSigSendType" SG_ 2463978673 EM1_Rekuperation 0;
BA_ "GenSigSwitchedByIgnition" SG_ 2463978673 EM1_Rekuperation 0;
BA_ "GenSigSendType" SG_ 2463978673 EM1_Rekuperation_Ueberlauf 0;
BA_ "GenSigSwitchedByIgnition" SG_ 2463978673 EM1_Rekuperation_Ueberlauf 0;
BA_ "GenSigSendType" SG_ 2463978673 EM1_Status_EoHVL 0;
BA_ "GenSigSwitchedByIgnition" SG_ 2463978673 EM1_Status_EoHVL 0;
BA_ "Fehlerwert" SG_ 2463978673 EM1_Status_EoHVL 3;
BA_ "GenSigSendType" SG_ 2463978673 EM1_Status_Spgfreiheit 0;
BA_ "GenSigSwitchedByIgnition" SG_ 2463978673 EM1_Status_Spgfreiheit 0;
BA_ "GenSigSendType" SG_ 2463978673 EM1_Verbrauch 0;
BA_ "GenSigSwitchedByIgnition" SG_ 2463978673 EM1_Verbrauch 0;
BA_ "GenSigSendType" SG_ 2463978673 EM1_Verbrauch_Ueberlauf 0;
BA_ "GenSigSwitchedByIgnition" SG_ 2463978673 EM1_Verbrauch_Ueberlauf 0;
BA_ "GenSigSendType" SG_ 2463978673 EM1_Warnlampe_Anf 0;
BA_ "GenSigSwitchedByIgnition" SG_ 2463978673 EM1_Warnlampe_Anf 0;
BA_ "GenSigSendType" SG_ 2589283657 EM1_EM_SollVolumenstrom 0;
BA_ "GenSigStartValue" SG_ 2589283657 EM1_EM_SollVolumenstrom 62;
BA_ "GenSigSwitchedByIgnition" SG_ 2589283657 EM1_EM_SollVolumenstrom 0;
BA_ "Fehlerwert" SG_ 2589283657 EM1_EM_SollVolumenstrom 63;
BA_ "GenSigSendType" SG_ 2589283657 EM1_Max_MechLeistung_nom 0;
BA_ "GenSigStartValue" SG_ 2589283657 EM1_Max_MechLeistung_nom 4094;
BA_ "GenSigSwitchedByIgnition" SG_ 2589283657 EM1_Max_MechLeistung_nom 0;
BA_ "Fehlerwert" SG_ 2589283657 EM1_Max_MechLeistung_nom 4095;
BA_ "GenSigSendType" SG_ 2589283657 EM1_Max_Moment_nom 0;
BA_ "GenSigStartValue" SG_ 2589283657 EM1_Max_Moment_nom 1022;
BA_ "GenSigSwitchedByIgnition" SG_ 2589283657 EM1_Max_Moment_nom 0;
BA_ "Fehlerwert" SG_ 2589283657 EM1_Max_Moment_nom 1023;
BA_ "GenSigSendType" SG_ 2589283657 EM1_SollVorlauftemperatur 0;
BA_ "GenSigStartValue" SG_ 2589283657 EM1_SollVorlauftemperatur 254;
BA_ "GenSigSwitchedByIgnition" SG_ 2589283657 EM1_SollVorlauftemperatur 0;
BA_ "Fehlerwert" SG_ 2589283657 EM1_SollVorlauftemperatur 255;
BA_ "GenSigSendType" SG_ 2589283657 EM1_Temperatur_EM 0;
BA_ "GenSigStartValue" SG_ 2589283657 EM1_Temperatur_EM 510;
BA_ "GenSigSwitchedByIgnition" SG_ 2589283657 EM1_Temperatur_EM 0;
BA_ "Fehlerwert" SG_ 2589283657 EM1_Temperatur_EM 511;
BA_ "GenSigSendType" SG_ 2589283657 EM1_Temperatur_PWR 0;
BA_ "GenSigStartValue" SG_ 2589283657 EM1_Temperatur_PWR 254;
BA_ "GenSigSwitchedByIgnition" SG_ 2589283657 EM1_Temperatur_PWR 0;
BA_ "Fehlerwert" SG_ 2589283657 EM1_Temperatur_PWR 255;
BA_ "GenSigSendType" SG_ 184 EM1_Abregelung_Temperatur 0;
BA_ "GenSigSwitchedByIgnition" SG_ 184 EM1_Abregelung_Temperatur 0;
BA_ "GenSigSendType" SG_ 184 EM1_AnlernenElMotor_Anf 0;
BA_ "GenSigSwitchedByIgnition" SG_ 184 EM1_AnlernenElMotor_Anf 0;
BA_ "GenSigSendType" SG_ 184 EM1_AR_aktiv 0;
BA_ "GenSigSwitchedByIgnition" SG_ 184 EM1_AR_aktiv 0;
BA_ "GenSigSendType" SG_ 184 EM1_Eta_Sys 0;
BA_ "GenSigStartValue" SG_ 184 EM1_Eta_Sys 510;
BA_ "GenSigSwitchedByIgnition" SG_ 184 EM1_Eta_Sys 0;
BA_ "Fehlerwert" SG_ 184 EM1_Eta_Sys 511;
BA_ "GenSigSendType" SG_ 184 EM1_Fehler_ElAntriebFreilauf_Anf 0;
BA_ "GenSigSwitchedByIgnition" SG_ 184 EM1_Fehler_ElAntriebFreilauf_Anf 0;
BA_ "GenSigSendType" SG_ 184 EM1_Freigabe_Info_WFS 3;
BA_ "GenSigSwitchedByIgnition" SG_ 184 EM1_Freigabe_Info_WFS 0;
BA_ "GenSigSendType" SG_ 184 EM1_Freigabe_Verfallsinfo_WFS 3;
BA_ "GenSigSwitchedByIgnition" SG_ 184 EM1_Freigabe_Verfallsinfo_WFS 0;
BA_ "GenSigSendType" SG_ 184 EM1_HV_betriebsbereit 0;
BA_ "GenSigSwitchedByIgnition" SG_ 184 EM1_HV_betriebsbereit 0;
BA_ "GenSigSendType" SG_ 184 EM1_IstStrom 0;
BA_ "GenSigStartValue" SG_ 184 EM1_IstStrom 2046;
BA_ "GenSigSwitchedByIgnition" SG_ 184 EM1_IstStrom 0;
BA_ "Fehlerwert" SG_ 184 EM1_IstStrom 2047;
BA_ "GenSigSendType" SG_ 184 EM1_Moment_HVVerbraucher 0;
BA_ "GenSigStartValue" SG_ 184 EM1_Moment_HVVerbraucher 1023;
BA_ "GenSigSwitchedByIgnition" SG_ 184 EM1_Moment_HVVerbraucher 0;
BA_ "GenSigSendType" SG_ 184 EM1_Parken_WFS_Status 0;
BA_ "GenSigSwitchedByIgnition" SG_ 184 EM1_Parken_WFS_Status 0;
BA_ "GenSigSendType" SG_ 184 EM1_Sperr_Info_WFS 3;
BA_ "GenSigSwitchedByIgnition" SG_ 184 EM1_Sperr_Info_WFS 0;
BA_ "GenSigSendType" SG_ 2527679712 EM1_RtmWarnKommunikation 0;
BA_ "GenSigSwitchedByIgnition" SG_ 2527679712 EM1_RtmWarnKommunikation 0;
BA_ "GenSigSendType" SG_ 2527679712 EM1_RtmWarnTempEM 0;
BA_ "GenSigSwitchedByIgnition" SG_ 2527679712 EM1_RtmWarnTempEM 0;
BA_ "GenSigSendType" SG_ 2527679712 EM1_RtmWarnTempPWR 0;
BA_ "GenSigSwitchedByIgnition" SG_ 2527679712 EM1_RtmWarnTempPWR 0;
BA_ "GenSigSendType" SG_ 2527679712 EM1_RtmWarnUeberdrehzahl 0;
BA_ "GenSigSwitchedByIgnition" SG_ 2527679712 EM1_RtmWarnUeberdrehzahl 0;
BA_ "GenSigSendType" SG_ 2527679712 EM1_RtmWarnUeberstrom 0;
BA_ "GenSigSwitchedByIgnition" SG_ 2527679712 EM1_RtmWarnUeberstrom 0;
BA_ "GenSigSendType" SG_ 193 EM2_01_BZ 0;
BA_ "GenSigFuncType" SG_ 193 EM2_01_BZ 1;
BA_ "GenSigSwitchedByIgnition" SG_ 193 EM2_01_BZ 0;
BA_ "GenSigSendType" SG_ 193 EM2_01_CRC 0;
BA_ "GenSigFuncType" SG_ 193 EM2_01_CRC 2;
BA_ "GenSigSwitchedByIgnition" SG_ 193 EM2_01_CRC 0;
BA_ "GenSigSendType" SG_ 193 EM2_AR_aktiv 0;
BA_ "GenSigSwitchedByIgnition" SG_ 193 EM2_AR_aktiv 0;
BA_ "GenSigSendType" SG_ 193 EM2_ErwGrenzen_aktiv 0;
BA_ "GenSigSwitchedByIgnition" SG_ 193 EM2_ErwGrenzen_aktiv 0;
BA_ "GenSigSendType" SG_ 193 EM2_Fehler_ElAntriebAbschaltung 0;
BA_ "GenSigSwitchedByIgnition" SG_ 193 EM2_Fehler_ElAntriebAbschaltung 0;
BA_ "GenSigSendType" SG_ 193 EM2_Fehler_Notabschaltung 0;
BA_ "GenSigSwitchedByIgnition" SG_ 193 EM2_Fehler_Notabschaltung 0;
BA_ "Fehlerwert" SG_ 193 EM2_Fehler_Notabschaltung 1;
BA_ "GenSigSendType" SG_ 193 EM2_IstDrehzahl 0;
BA_ "GenSigStartValue" SG_ 193 EM2_IstDrehzahl 32766;
BA_ "GenSigSwitchedByIgnition" SG_ 193 EM2_IstDrehzahl 0;
BA_ "Fehlerwert" SG_ 193 EM2_IstDrehzahl 32767;
BA_ "GenSigSendType" SG_ 193 EM2_Istmodus 0;
BA_ "GenSigStartValue" SG_ 193 EM2_Istmodus 15;
BA_ "GenSigSwitchedByIgnition" SG_ 193 EM2_Istmodus 0;
BA_ "GenSigSendType" SG_ 193 EM2_IstMoment 0;
BA_ "GenSigStartValue" SG_ 193 EM2_IstMoment 4094;
BA_ "GenSigSwitchedByIgnition" SG_ 193 EM2_IstMoment 0;
BA_ "Fehlerwert" SG_ 193 EM2_IstMoment 4095;
BA_ "GenSigSendType" SG_ 193 EM2_IstSpannung 0;
BA_ "GenSigStartValue" SG_ 193 EM2_IstSpannung 4094;
BA_ "GenSigSwitchedByIgnition" SG_ 193 EM2_IstSpannung 0;
BA_ "Fehlerwert" SG_ 193 EM2_IstSpannung 4095;
BA_ "GenSigSendType" SG_ 193 EM2_Max_Moment 0;
BA_ "GenSigStartValue" SG_ 193 EM2_Max_Moment 2046;
BA_ "GenSigSwitchedByIgnition" SG_ 193 EM2_Max_Moment 0;
BA_ "Fehlerwert" SG_ 193 EM2_Max_Moment 2047;
BA_ "GenSigSendType" SG_ 193 EM2_Max_Moment_Lim 0;
BA_ "GenSigStartValue" SG_ 193 EM2_Max_Moment_Lim 2046;
BA_ "GenSigSwitchedByIgnition" SG_ 193 EM2_Max_Moment_Lim 0;
BA_ "Fehlerwert" SG_ 193 EM2_Max_Moment_Lim 2047;
BA_ "GenSigSendType" SG_ 193 EM2_Min_Moment 0;
BA_ "GenSigStartValue" SG_ 193 EM2_Min_Moment 2046;
BA_ "GenSigSwitchedByIgnition" SG_ 193 EM2_Min_Moment 0;
BA_ "Fehlerwert" SG_ 193 EM2_Min_Moment 2047;
BA_ "GenSigSendType" SG_ 193 EM2_Min_Moment_Lim 0;
BA_ "GenSigStartValue" SG_ 193 EM2_Min_Moment_Lim 2046;
BA_ "GenSigSwitchedByIgnition" SG_ 193 EM2_Min_Moment_Lim 0;
BA_ "Fehlerwert" SG_ 193 EM2_Min_Moment_Lim 2047;
BA_ "GenSigSendType" SG_ 193 EM2_Mom_DrzEingriff 0;
BA_ "GenSigStartValue" SG_ 193 EM2_Mom_DrzEingriff 2046;
BA_ "GenSigSwitchedByIgnition" SG_ 193 EM2_Mom_DrzEingriff 0;
BA_ "Fehlerwert" SG_ 193 EM2_Mom_DrzEingriff 2047;
BA_ "GenSigSendType" SG_ 193 EM2_Moment_AR_Eingriff 0;
BA_ "GenSigStartValue" SG_ 193 EM2_Moment_AR_Eingriff 4094;
BA_ "GenSigSwitchedByIgnition" SG_ 193 EM2_Moment_AR_Eingriff 0;
BA_ "Fehlerwert" SG_ 193 EM2_Moment_AR_Eingriff 4095;
BA_ "GenSigSendType" SG_ 193 EM2_Status_DrzEingriff 0;
BA_ "GenSigSwitchedByIgnition" SG_ 193 EM2_Status_DrzEingriff 0;
BA_ "Fehlerwert" SG_ 193 EM2_Status_DrzEingriff 3;
BA_ "GenSigSendType" SG_ 193 EM2_Strom_HV 0;
BA_ "GenSigStartValue" SG_ 193 EM2_Strom_HV 4094;
BA_ "GenSigSwitchedByIgnition" SG_ 193 EM2_Strom_HV 0;
BA_ "Fehlerwert" SG_ 193 EM2_Strom_HV 4095;
BA_ "GenSigSendType" SG_ 2463978674 EM2_AnlernenElMotor_Anf 0;
BA_ "GenSigSwitchedByIgnition" SG_ 2463978674 EM2_AnlernenElMotor_Anf 0;
BA_ "GenSigSendType" SG_ 2463978674 EM2_Fehler_AE 0;
BA_ "GenSigSwitchedByIgnition" SG_ 2463978674 EM2_Fehler_AE 0;
BA_ "GenSigSendType" SG_ 2463978674 EM2_Fehler_ElAntriebFreilauf 0;
BA_ "GenSigSwitchedByIgnition" SG_ 2463978674 EM2_Fehler_ElAntriebFreilauf 0;
BA_ "GenSigSendType" SG_ 2463978674 EM2_Fehler_Leistungsred 0;
BA_ "GenSigSwitchedByIgnition" SG_ 2463978674 EM2_Fehler_Leistungsred 0;
BA_ "GenSigSendType" SG_ 2463978674 EM2_Fehlerlampe_Anf 0;
BA_ "GenSigSwitchedByIgnition" SG_ 2463978674 EM2_Fehlerlampe_Anf 0;
BA_ "GenSigSendType" SG_ 2463978674 EM2_Generator_Moment 0;
BA_ "GenSigStartValue" SG_ 2463978674 EM2_Generator_Moment 1022;
BA_ "GenSigSwitchedByIgnition" SG_ 2463978674 EM2_Generator_Moment 0;
BA_ "Fehlerwert" SG_ 2463978674 EM2_Generator_Moment 1023;
BA_ "GenSigSendType" SG_ 2463978674 EM2_Max_LeistungMech_Sockel 0;
BA_ "GenSigStartValue" SG_ 2463978674 EM2_Max_LeistungMech_Sockel 8190;
BA_ "GenSigSwitchedByIgnition" SG_ 2463978674 EM2_Max_LeistungMech_Sockel 0;
BA_ "Fehlerwert" SG_ 2463978674 EM2_Max_LeistungMech_Sockel 8191;
BA_ "GenSigSendType" SG_ 2463978674 EM2_Max_Moment_Gesamt 0;
BA_ "GenSigStartValue" SG_ 2463978674 EM2_Max_Moment_Gesamt 2046;
BA_ "GenSigSwitchedByIgnition" SG_ 2463978674 EM2_Max_Moment_Gesamt 0;
BA_ "Fehlerwert" SG_ 2463978674 EM2_Max_Moment_Gesamt 2047;
BA_ "GenSigSendType" SG_ 2463978674 EM2_Max_Moment_Sockel 0;
BA_ "GenSigStartValue" SG_ 2463978674 EM2_Max_Moment_Sockel 2046;
BA_ "GenSigSwitchedByIgnition" SG_ 2463978674 EM2_Max_Moment_Sockel 0;
BA_ "Fehlerwert" SG_ 2463978674 EM2_Max_Moment_Sockel 2047;
BA_ "GenSigSendType" SG_ 2463978674 EM2_MaxZul_Drehzahl 0;
BA_ "GenSigStartValue" SG_ 2463978674 EM2_MaxZul_Drehzahl 254;
BA_ "GenSigSwitchedByIgnition" SG_ 2463978674 EM2_MaxZul_Drehzahl 0;
BA_ "Fehlerwert" SG_ 2463978674 EM2_MaxZul_Drehzahl 255;
BA_ "GenSigSendType" SG_ 2463978674 EM2_Min_LeistungMech_Sockel 0;
BA_ "GenSigStartValue" SG_ 2463978674 EM2_Min_LeistungMech_Sockel 8190;
BA_ "GenSigSwitchedByIgnition" SG_ 2463978674 EM2_Min_LeistungMech_Sockel 0;
BA_ "Fehlerwert" SG_ 2463978674 EM2_Min_LeistungMech_Sockel 8191;
BA_ "GenSigSendType" SG_ 2463978674 EM2_Min_Moment_Gesamt 0;
BA_ "GenSigStartValue" SG_ 2463978674 EM2_Min_Moment_Gesamt 2046;
BA_ "GenSigSwitchedByIgnition" SG_ 2463978674 EM2_Min_Moment_Gesamt 0;
BA_ "Fehlerwert" SG_ 2463978674 EM2_Min_Moment_Gesamt 2047;
BA_ "GenSigSendType" SG_ 2463978674 EM2_Min_Moment_Sockel 0;
BA_ "GenSigStartValue" SG_ 2463978674 EM2_Min_Moment_Sockel 2046;
BA_ "GenSigSwitchedByIgnition" SG_ 2463978674 EM2_Min_Moment_Sockel 0;
BA_ "Fehlerwert" SG_ 2463978674 EM2_Min_Moment_Sockel 2047;
BA_ "GenSigSendType" SG_ 2463978674 EM2_OBD_Lampe_Anf 0;
BA_ "GenSigSwitchedByIgnition" SG_ 2463978674 EM2_OBD_Lampe_Anf 0;
BA_ "GenSigSendType" SG_ 2463978674 EM2_PerfInd_MaxLeistung 0;
BA_ "GenSigStartValue" SG_ 2463978674 EM2_PerfInd_MaxLeistung 1022;
BA_ "GenSigSwitchedByIgnition" SG_ 2463978674 EM2_PerfInd_MaxLeistung 0;
BA_ "GenSigSendType" SG_ 2463978674 EM2_PerfInd_MaxMoment 0;
BA_ "GenSigStartValue" SG_ 2463978674 EM2_PerfInd_MaxMoment 1022;
BA_ "GenSigSwitchedByIgnition" SG_ 2463978674 EM2_PerfInd_MaxMoment 0;
BA_ "GenSigSendType" SG_ 2463978674 EM2_PerfInd_Temperatur 0;
BA_ "GenSigStartValue" SG_ 2463978674 EM2_PerfInd_Temperatur 254;
BA_ "GenSigSwitchedByIgnition" SG_ 2463978674 EM2_PerfInd_Temperatur 0;
BA_ "GenSigSendType" SG_ 2463978674 EM2_PWR_SollVolumenstrom 0;
BA_ "GenSigStartValue" SG_ 2463978674 EM2_PWR_SollVolumenstrom 62;
BA_ "GenSigSwitchedByIgnition" SG_ 2463978674 EM2_PWR_SollVolumenstrom 0;
BA_ "Fehlerwert" SG_ 2463978674 EM2_PWR_SollVolumenstrom 63;
BA_ "GenSigSendType" SG_ 2463978674 EM2_Rekuperation 0;
BA_ "GenSigSwitchedByIgnition" SG_ 2463978674 EM2_Rekuperation 0;
BA_ "GenSigSendType" SG_ 2463978674 EM2_Rekuperation_Ueberlauf 0;
BA_ "GenSigSwitchedByIgnition" SG_ 2463978674 EM2_Rekuperation_Ueberlauf 0;
BA_ "GenSigSendType" SG_ 2463978674 EM2_Status_EoHVL 0;
BA_ "GenSigSwitchedByIgnition" SG_ 2463978674 EM2_Status_EoHVL 0;
BA_ "Fehlerwert" SG_ 2463978674 EM2_Status_EoHVL 3;
BA_ "GenSigSendType" SG_ 2463978674 EM2_Status_Spgfreiheit 0;
BA_ "GenSigSwitchedByIgnition" SG_ 2463978674 EM2_Status_Spgfreiheit 0;
BA_ "GenSigSendType" SG_ 2463978674 EM2_Verbrauch 0;
BA_ "GenSigSwitchedByIgnition" SG_ 2463978674 EM2_Verbrauch 0;
BA_ "GenSigSendType" SG_ 2463978674 EM2_Verbrauch_Ueberlauf 0;
BA_ "GenSigSwitchedByIgnition" SG_ 2463978674 EM2_Verbrauch_Ueberlauf 0;
BA_ "GenSigSendType" SG_ 2463978674 EM2_Warnlampe_Anf 0;
BA_ "GenSigSwitchedByIgnition" SG_ 2463978674 EM2_Warnlampe_Anf 0;
BA_ "GenSigSendType" SG_ 2589283660 EM2_EM_SollVolumenstrom 0;
BA_ "GenSigStartValue" SG_ 2589283660 EM2_EM_SollVolumenstrom 62;
BA_ "GenSigSwitchedByIgnition" SG_ 2589283660 EM2_EM_SollVolumenstrom 0;
BA_ "Fehlerwert" SG_ 2589283660 EM2_EM_SollVolumenstrom 63;
BA_ "GenSigSendType" SG_ 2589283660 EM2_Max_MechLeistung_nom 0;
BA_ "GenSigStartValue" SG_ 2589283660 EM2_Max_MechLeistung_nom 4094;
BA_ "GenSigSwitchedByIgnition" SG_ 2589283660 EM2_Max_MechLeistung_nom 0;
BA_ "Fehlerwert" SG_ 2589283660 EM2_Max_MechLeistung_nom 4095;
BA_ "GenSigSendType" SG_ 2589283660 EM2_Max_Moment_nom 0;
BA_ "GenSigStartValue" SG_ 2589283660 EM2_Max_Moment_nom 1022;
BA_ "GenSigSwitchedByIgnition" SG_ 2589283660 EM2_Max_Moment_nom 0;
BA_ "Fehlerwert" SG_ 2589283660 EM2_Max_Moment_nom 1023;
BA_ "GenSigSendType" SG_ 2589283660 EM2_SollVorlauftemperatur 0;
BA_ "GenSigStartValue" SG_ 2589283660 EM2_SollVorlauftemperatur 254;
BA_ "GenSigSwitchedByIgnition" SG_ 2589283660 EM2_SollVorlauftemperatur 0;
BA_ "Fehlerwert" SG_ 2589283660 EM2_SollVorlauftemperatur 255;
BA_ "GenSigSendType" SG_ 2589283660 EM2_Temperatur_EM 0;
BA_ "GenSigStartValue" SG_ 2589283660 EM2_Temperatur_EM 510;
BA_ "GenSigSwitchedByIgnition" SG_ 2589283660 EM2_Temperatur_EM 0;
BA_ "Fehlerwert" SG_ 2589283660 EM2_Temperatur_EM 511;
BA_ "GenSigSendType" SG_ 2589283660 EM2_Temperatur_PWR 0;
BA_ "GenSigStartValue" SG_ 2589283660 EM2_Temperatur_PWR 254;
BA_ "GenSigSwitchedByIgnition" SG_ 2589283660 EM2_Temperatur_PWR 0;
BA_ "Fehlerwert" SG_ 2589283660 EM2_Temperatur_PWR 255;
BA_ "GenSigSendType" SG_ 199 EM2_Abregelung_Temperatur 0;
BA_ "GenSigSwitchedByIgnition" SG_ 199 EM2_Abregelung_Temperatur 0;
BA_ "GenSigSendType" SG_ 199 EM2_AnlernenElMotor_Anf 0;
BA_ "GenSigSwitchedByIgnition" SG_ 199 EM2_AnlernenElMotor_Anf 0;
BA_ "GenSigSendType" SG_ 199 EM2_AR_aktiv 0;
BA_ "GenSigSwitchedByIgnition" SG_ 199 EM2_AR_aktiv 0;
BA_ "GenSigSendType" SG_ 199 EM2_Eta_Sys 0;
BA_ "GenSigStartValue" SG_ 199 EM2_Eta_Sys 510;
BA_ "GenSigSwitchedByIgnition" SG_ 199 EM2_Eta_Sys 0;
BA_ "Fehlerwert" SG_ 199 EM2_Eta_Sys 511;
BA_ "GenSigSendType" SG_ 199 EM2_Fehler_ElAntriebFreilauf_Anf 0;
BA_ "GenSigSwitchedByIgnition" SG_ 199 EM2_Fehler_ElAntriebFreilauf_Anf 0;
BA_ "GenSigSendType" SG_ 199 EM2_Freigabe_Info_WFS 3;
BA_ "GenSigSwitchedByIgnition" SG_ 199 EM2_Freigabe_Info_WFS 0;
BA_ "GenSigSendType" SG_ 199 EM2_Freigabe_Verfallsinfo_WFS 3;
BA_ "GenSigSwitchedByIgnition" SG_ 199 EM2_Freigabe_Verfallsinfo_WFS 0;
BA_ "GenSigSendType" SG_ 199 EM2_HV_betriebsbereit 0;
BA_ "GenSigSwitchedByIgnition" SG_ 199 EM2_HV_betriebsbereit 0;
BA_ "GenSigSendType" SG_ 199 EM2_IstStrom 0;
BA_ "GenSigStartValue" SG_ 199 EM2_IstStrom 2046;
BA_ "GenSigSwitchedByIgnition" SG_ 199 EM2_IstStrom 0;
BA_ "Fehlerwert" SG_ 199 EM2_IstStrom 2047;
BA_ "GenSigSendType" SG_ 199 EM2_Parken_WFS_Status 0;
BA_ "GenSigSwitchedByIgnition" SG_ 199 EM2_Parken_WFS_Status 0;
BA_ "GenSigSendType" SG_ 199 EM2_Sperr_Info_WFS 3;
BA_ "GenSigSwitchedByIgnition" SG_ 199 EM2_Sperr_Info_WFS 0;
BA_ "GenSigSendType" SG_ 2527679713 EM2_RtmWarnKommunikation 0;
BA_ "GenSigSwitchedByIgnition" SG_ 2527679713 EM2_RtmWarnKommunikation 0;
BA_ "GenSigSendType" SG_ 2527679713 EM2_RtmWarnTempEM 0;
BA_ "GenSigSwitchedByIgnition" SG_ 2527679713 EM2_RtmWarnTempEM 0;
BA_ "GenSigSendType" SG_ 2527679713 EM2_RtmWarnTempPWR 0;
BA_ "GenSigSwitchedByIgnition" SG_ 2527679713 EM2_RtmWarnTempPWR 0;
BA_ "GenSigSendType" SG_ 2527679713 EM2_RtmWarnUeberdrehzahl 0;
BA_ "GenSigSwitchedByIgnition" SG_ 2527679713 EM2_RtmWarnUeberdrehzahl 0;
BA_ "GenSigSendType" SG_ 2527679713 EM2_RtmWarnUeberstrom 0;
BA_ "GenSigSwitchedByIgnition" SG_ 2527679713 EM2_RtmWarnUeberstrom 0;
BA_ "GenSigSendType" SG_ 2589283649 EML_02_BZ 0;
BA_ "GenSigFuncType" SG_ 2589283649 EML_02_BZ 1;
BA_ "GenSigSendType" SG_ 2589283649 EML_02_CRC 0;
BA_ "GenSigFuncType" SG_ 2589283649 EML_02_CRC 2;
BA_ "GenSigSendType" SG_ 2589283649 EML_QBit_Reifenumfang 0;
BA_ "GenSigStartValue" SG_ 2589283649 EML_QBit_Reifenumfang 1;
BA_ "GenSigSwitchedByIgnition" SG_ 2589283649 EML_QBit_Reifenumfang 0;
BA_ "GenSigSendType" SG_ 2589283649 EML_ReifenKorrFaktorHL 0;
BA_ "GenSigStartValue" SG_ 2589283649 EML_ReifenKorrFaktorHL 510;
BA_ "Fehlerwert" SG_ 2589283649 EML_ReifenKorrFaktorHL 511;
BA_ "GenSigSendType" SG_ 2589283649 EML_ReifenKorrFaktorHR 0;
BA_ "GenSigStartValue" SG_ 2589283649 EML_ReifenKorrFaktorHR 510;
BA_ "Fehlerwert" SG_ 2589283649 EML_ReifenKorrFaktorHR 511;
BA_ "GenSigSendType" SG_ 2589283649 EML_ReifenKorrFaktorVL 0;
BA_ "GenSigStartValue" SG_ 2589283649 EML_ReifenKorrFaktorVL 510;
BA_ "Fehlerwert" SG_ 2589283649 EML_ReifenKorrFaktorVL 511;
BA_ "GenSigSendType" SG_ 2589283649 EML_ReifenKorrFaktorVR 0;
BA_ "GenSigStartValue" SG_ 2589283649 EML_ReifenKorrFaktorVR 510;
BA_ "Fehlerwert" SG_ 2589283649 EML_ReifenKorrFaktorVR 511;
BA_ "GenSigSendType" SG_ 2589283649 EML_Reifenumfang 0;
BA_ "GenSigSwitchedByIgnition" SG_ 2589283649 EML_Reifenumfang 0;
BA_ "GenSigSendType" SG_ 608 EML_AnzeigeGeschw 0;
BA_ "GenSigStartValue" SG_ 608 EML_AnzeigeGeschw 1022;
BA_ "Fehlerwert" SG_ 608 EML_AnzeigeGeschw 1023;
BA_ "GenSigSendType" SG_ 2589283751 KBI_Kilometerstand_HiRes_meter 0;
BA_ "GenSigSwitchedByIgnition" SG_ 2589283751 KBI_Kilometerstand_HiRes_meter 0;
BA_ "GenSigSendType" SG_ 2527679687 EPS_ASM_Data_1 0;
BA_ "GenSigSendType" SG_ 2527679687 EPS_ASM_Data_2 0;
BA_ "GenSigSendType" SG_ 2527679687 EPS_ASM_Data_3 0;
BA_ "GenSigSendType" SG_ 2527679687 EPS_ASM_Data_4 0;
BA_ "GenSigSendType" SG_ 2527679687 EPS_ASM_Data_5 0;
BA_ "GenSigSendType" SG_ 2527679687 EPS_ASM_Data_6 0;
BA_ "GenSigSendType" SG_ 2527679687 EPS_ASM_Ereignis 3;
BA_ "GenSigSendType" SG_ 2527679687 EPS_ASM_Zeitstempel 3;
BA_ "GenSigStartValue" SG_ 2527679687 EPS_ASM_Zeitstempel 255;
BA_REL_ "GenSigTimeoutTime" BU_SG_REL_ Airbag SG_ 1714 DGN_Verlernzaehler 5000;
BA_REL_ "GenSigTimeoutTime" BU_SG_REL_ Airbag SG_ 1714 KBI_Kilometerstand 5000;
BA_REL_ "GenSigTimeoutTime" BU_SG_REL_ Airbag SG_ 1714 UH_Jahr 5000;
BA_REL_ "GenSigTimeoutTime" BU_SG_REL_ Airbag SG_ 1714 UH_Monat 5000;
BA_REL_ "GenSigTimeoutTime" BU_SG_REL_ Airbag SG_ 1714 UH_Tag 5000;
BA_REL_ "GenSigTimeoutTime" BU_SG_REL_ Airbag SG_ 1714 UH_Stunde 5000;
BA_REL_ "GenSigTimeoutTime" BU_SG_REL_ Airbag SG_ 1714 UH_Minute 5000;
BA_REL_ "GenSigTimeoutTime" BU_SG_REL_ Airbag SG_ 1714 UH_Sekunde 5000;
BA_REL_ "GenSigTimeoutTime" BU_SG_REL_ Airbag SG_ 1714 Vehicle_Driving_Cycle 5000;
BA_REL_ "GenSigTimeoutTime" BU_SG_REL_ Airbag SG_ 851 DiETas_01_CRC 800;
BA_REL_ "GenSigTimeoutTime" BU_SG_REL_ Airbag SG_ 851 DiETas_01_BZ 800;
BA_REL_ "GenSigTimeoutTime" BU_SG_REL_ Airbag SG_ 851 DiETa_Status 800;
BA_REL_ "GenSigTimeoutTime" BU_SG_REL_ Airbag SG_ 851 DiETa_PAO_ON_Status 800;
BA_REL_ "GenSigTimeoutTime" BU_SG_REL_ Airbag SG_ 851 DiETa_PAO_OFF_Status 800;
BA_REL_ "GenSigTimeoutTime" BU_SG_REL_ Airbag SG_ 1520 DI_KL_58xd 2000;
BA_REL_ "GenSigTimeoutTime" BU_SG_REL_ Airbag SG_ 1520 DI_KL_58xs 2000;
BA_REL_ "GenSigTimeoutTime" BU_SG_REL_ Airbag SG_ 1520 DI_KL_58xt 2000;
BA_REL_ "GenSigTimeoutTime" BU_SG_REL_ Airbag SG_ 420 EA_Gurtstraffer_Anf 5000;
BA_REL_ "GenSigTimeoutTime" BU_SG_REL_ Airbag SG_ 2527679687 EPS_ASM_Ereignis 5000;
BA_REL_ "GenSigTimeoutTime" BU_SG_REL_ Airbag SG_ 2527679687 EPS_ASM_Zeitstempel 5000;
BA_REL_ "GenSigTimeoutTime" BU_SG_REL_ Airbag SG_ 2527679687 EPS_ASM_Data_1 5000;
BA_REL_ "GenSigTimeoutTime" BU_SG_REL_ Airbag SG_ 2527679687 EPS_ASM_Data_2 5000;
BA_REL_ "GenSigTimeoutTime" BU_SG_REL_ Airbag SG_ 2527679687 EPS_ASM_Data_3 5000;
BA_REL_ "GenSigTimeoutTime" BU_SG_REL_ Airbag SG_ 2527679687 EPS_ASM_Data_4 5000;
BA_REL_ "GenSigTimeoutTime" BU_SG_REL_ Airbag SG_ 2527679687 EPS_ASM_Data_5 5000;
BA_REL_ "GenSigTimeoutTime" BU_SG_REL_ Airbag SG_ 2527679687 EPS_ASM_Data_6 5000;
BA_REL_ "GenSigTimeoutTime" BU_SG_REL_ ICAS1_Gateway SG_ 192 EM1_Istmodus 500;
BA_REL_ "GenSigTimeoutTime" BU_SG_REL_ ICAS1_Gateway SG_ 192 EM1_IstMoment 500;
BA_REL_ "GenSigTimeoutTime" BU_SG_REL_ ICAS1_Gateway SG_ 192 EM1_IstDrehzahl 500;
BA_REL_ "GenSigTimeoutTime" BU_SG_REL_ ICAS1_Gateway SG_ 192 EM1_IstSpannung 500;
BA_REL_ "GenSigTimeoutTime" BU_SG_REL_ ICAS1_Gateway SG_ 192 EM1_Strom_HV 500;
BA_REL_ "GenSigTimeoutTime" BU_SG_REL_ ICAS1_Gateway SG_ 192 EM1_Fehler_Notabschaltung 500;
BA_REL_ "GenSigTimeoutTime" BU_SG_REL_ ICAS1_Gateway SG_ 2589283657 EM1_Temperatur_EM 5000;
BA_REL_ "GenSigTimeoutTime" BU_SG_REL_ ICAS1_Gateway SG_ 2589283657 EM1_Temperatur_PWR 5000;
BA_REL_ "GenSigTimeoutTime" BU_SG_REL_ ICAS1_Gateway SG_ 184 EM1_Sperr_Info_WFS 5000;
BA_REL_ "GenSigTimeoutTime" BU_SG_REL_ ICAS1_Gateway SG_ 2527679712 EM1_RtmWarnUeberdrehzahl 5000;
BA_REL_ "GenSigTimeoutTime" BU_SG_REL_ ICAS1_Gateway SG_ 2527679712 EM1_RtmWarnUeberstrom 5000;
BA_REL_ "GenSigTimeoutTime" BU_SG_REL_ ICAS1_Gateway SG_ 2527679712 EM1_RtmWarnTempEM 5000;
BA_REL_ "GenSigTimeoutTime" BU_SG_REL_ ICAS1_Gateway SG_ 2527679712 EM1_RtmWarnTempPWR 5000;
BA_REL_ "GenSigTimeoutTime" BU_SG_REL_ ICAS1_Gateway SG_ 193 EM2_Istmodus 500;
BA_REL_ "GenSigTimeoutTime" BU_SG_REL_ ICAS1_Gateway SG_ 193 EM2_IstMoment 500;
BA_REL_ "GenSigTimeoutTime" BU_SG_REL_ ICAS1_Gateway SG_ 193 EM2_IstDrehzahl 500;
BA_REL_ "GenSigTimeoutTime" BU_SG_REL_ ICAS1_Gateway SG_ 193 EM2_IstSpannung 500;
BA_REL_ "GenSigTimeoutTime" BU_SG_REL_ ICAS1_Gateway SG_ 193 EM2_Strom_HV 500;
BA_REL_ "GenSigTimeoutTime" BU_SG_REL_ ICAS1_Gateway SG_ 193 EM2_Fehler_Notabschaltung 500;
BA_REL_ "GenSigTimeoutTime" BU_SG_REL_ ICAS1_Gateway SG_ 2589283660 EM2_Temperatur_EM 5000;
BA_REL_ "GenSigTimeoutTime" BU_SG_REL_ ICAS1_Gateway SG_ 2589283660 EM2_Temperatur_PWR 5000;
BA_REL_ "GenSigTimeoutTime" BU_SG_REL_ ICAS1_Gateway SG_ 199 EM2_Sperr_Info_WFS 5000;
BA_REL_ "GenSigTimeoutTime" BU_SG_REL_ ICAS1_Gateway SG_ 2527679713 EM2_RtmWarnUeberdrehzahl 5000;
BA_REL_ "GenSigTimeoutTime" BU_SG_REL_ ICAS1_Gateway SG_ 2527679713 EM2_RtmWarnUeberstrom 5000;
BA_REL_ "GenSigTimeoutTime" BU_SG_REL_ ICAS1_Gateway SG_ 2527679713 EM2_RtmWarnTempEM 5000;
BA_REL_ "GenSigTimeoutTime" BU_SG_REL_ ICAS1_Gateway SG_ 2527679713 EM2_RtmWarnTempPWR 5000;
BA_REL_ "GenSigTimeoutTime" BU_SG_REL_ LE1 SG_ 1714 DGN_Verlernzaehler 5000;
BA_REL_ "GenSigTimeoutTime" BU_SG_REL_ LE1 SG_ 1714 KBI_Kilometerstand 5000;
BA_REL_ "GenSigTimeoutTime" BU_SG_REL_ LE1 SG_ 1714 UH_Jahr 5000;
BA_REL_ "GenSigTimeoutTime" BU_SG_REL_ LE1 SG_ 1714 UH_Monat 5000;
BA_REL_ "GenSigTimeoutTime" BU_SG_REL_ LE1 SG_ 1714 UH_Tag 5000;
BA_REL_ "GenSigTimeoutTime" BU_SG_REL_ LE1 SG_ 1714 UH_Stunde 5000;
BA_REL_ "GenSigTimeoutTime" BU_SG_REL_ LE1 SG_ 1714 UH_Minute 5000;
BA_REL_ "GenSigTimeoutTime" BU_SG_REL_ LE1 SG_ 1714 UH_Sekunde 5000;
BA_REL_ "GenSigTimeoutTime" BU_SG_REL_ LE2 SG_ 1714 DGN_Verlernzaehler 5000;
BA_REL_ "GenSigTimeoutTime" BU_SG_REL_ LE2 SG_ 1714 KBI_Kilometerstand 5000;
BA_REL_ "GenSigTimeoutTime" BU_SG_REL_ LE2 SG_ 1714 UH_Jahr 5000;
BA_REL_ "GenSigTimeoutTime" BU_SG_REL_ LE2 SG_ 1714 UH_Monat 5000;
BA_REL_ "GenSigTimeoutTime" BU_SG_REL_ LE2 SG_ 1714 UH_Tag 5000;
BA_REL_ "GenSigTimeoutTime" BU_SG_REL_ LE2 SG_ 1714 UH_Stunde 5000;
BA_REL_ "GenSigTimeoutTime" BU_SG_REL_ LE2 SG_ 1714 UH_Minute 5000;
BA_REL_ "GenSigTimeoutTime" BU_SG_REL_ LE2 SG_ 1714 UH_Sekunde 5000;
BA_REL_ "GenSigTimeoutTime" BU_SG_REL_ Motor_BEV SG_ 514 DR_Aufbaubeschleunigung_HR 500;
BA_REL_ "GenSigTimeoutTime" BU_SG_REL_ Motor_BEV SG_ 514 DR_Aufbaubeschleunigung_VR 500;
BA_REL_ "GenSigTimeoutTime" BU_SG_REL_ Motor_BEV SG_ 514 DR_Aufbaubeschleunigung_VL 500;
BA_REL_ "GenSigTimeoutTime" BU_SG_REL_ Motor_BEV SG_ 514 DR_Aufbaubeschleunigung_HL 500;
BA_REL_ "GenSigTimeoutTime" BU_SG_REL_ Motor_BEV SG_ 1485 DCDC_03_CRC 5000;
BA_REL_ "GenSigTimeoutTime" BU_SG_REL_ Motor_BEV SG_ 1485 DCDC_03_BZ 5000;
BA_REL_ "GenSigTimeoutTime" BU_SG_REL_ Motor_BEV SG_ 1485 DC_Kl30c_Status 5000;
BA_REL_ "GenSigTimeoutTime" BU_SG_REL_ Motor_BEV SG_ 1485 DC_SollVolumenstrom 5000;
BA_REL_ "GenSigTimeoutTime" BU_SG_REL_ Motor_BEV SG_ 1485 DC_Temperatur 5000;
BA_REL_ "GenSigTimeoutTime" BU_SG_REL_ Motor_BEV SG_ 247 DC_Vorladung_Status 500;
BA_REL_ "GenSigTimeoutTime" BU_SG_REL_ Motor_BEV SG_ 247 DC_Fehler_extern 500;
BA_REL_ "GenSigTimeoutTime" BU_SG_REL_ Motor_BEV SG_ 247 DC_Fehler_intern 500;
BA_REL_ "GenSigTimeoutTime" BU_SG_REL_ Motor_BEV SG_ 247 DC_Status_Spgfreiheit 500;
BA_REL_ "GenSigTimeoutTime" BU_SG_REL_ Motor_BEV SG_ 247 DC_Status_EoHVL 500;
BA_REL_ "GenSigTimeoutTime" BU_SG_REL_ Motor_BEV SG_ 247 DC_IstModus_02 500;
BA_REL_ "GenSigTimeoutTime" BU_SG_REL_ Motor_BEV SG_ 247 DC_IstStrom_HV 500;
BA_REL_ "GenSigTimeoutTime" BU_SG_REL_ Motor_BEV SG_ 247 DC_IstLeistung_HV 500;
BA_REL_ "GenSigTimeoutTime" BU_SG_REL_ Motor_BEV SG_ 1714 DGN_Verlernzaehler 5000;
BA_REL_ "GenSigTimeoutTime" BU_SG_REL_ Motor_BEV SG_ 1714 KBI_Kilometerstand 5000;
BA_REL_ "GenSigTimeoutTime" BU_SG_REL_ Motor_BEV SG_ 1714 UH_Jahr 5000;
BA_REL_ "GenSigTimeoutTime" BU_SG_REL_ Motor_BEV SG_ 1714 UH_Monat 5000;
BA_REL_ "GenSigTimeoutTime" BU_SG_REL_ Motor_BEV SG_ 1714 UH_Tag 5000;
BA_REL_ "GenSigTimeoutTime" BU_SG_REL_ Motor_BEV SG_ 1714 UH_Stunde 5000;
BA_REL_ "GenSigTimeoutTime" BU_SG_REL_ Motor_BEV SG_ 1714 UH_Minute 5000;
BA_REL_ "GenSigTimeoutTime" BU_SG_REL_ Motor_BEV SG_ 1714 UH_Sekunde 5000;
BA_REL_ "GenSigTimeoutTime" BU_SG_REL_ Motor_BEV SG_ 420 EA_01_CRC 5000;
BA_REL_ "GenSigTimeoutTime" BU_SG_REL_ Motor_BEV SG_ 420 EA_01_BZ 5000;
BA_REL_ "GenSigTimeoutTime" BU_SG_REL_ Motor_BEV SG_ 420 EA_aktiv_laengs 5000;
BA_REL_ "GenSigTimeoutTime" BU_SG_REL_ Motor_BEV SG_ 420 EA_Funktionsstatus 5000;
BA_REL_ "GenSigTimeoutTime" BU_SG_REL_ Motor_BEV SG_ 420 EA_Sollbeschleunigung 5000;
BA_REL_ "GenSigTimeoutTime" BU_SG_REL_ Motor_BEV SG_ 374 EBKV_Fahrer_bremst 500;
BA_REL_ "GenSigTimeoutTime" BU_SG_REL_ Motor_BEV SG_ 374 EBKV_QBit_Fahrer_bremst 500;
BA_REL_ "GenSigTimeoutTime" BU_SG_REL_ Motor_BEV SG_ 374 EBKV_OBD_Status 500;
BA_REL_ "GenSigTimeoutTime" BU_SG_REL_ Motor_BEV SG_ 374 EPB_Status_ext 500;
BA_REL_ "GenSigTimeoutTime" BU_SG_REL_ Motor_BEV SG_ 374 EBKV_Bremspedalweg 500;
BA_REL_ "GenSigTimeoutTime" BU_SG_REL_ Motor_BEV SG_ 1603 KBI_MFA_v_Einheit_02 5000;
BA_REL_ "GenSigTimeoutTime" BU_SG_REL_ Motor_BEV SG_ 1603 KBI_Einheit_Tacho 5000;
BA_REL_ "GenSigTimeoutTime" BU_SG_REL_ Motor_BEV SG_ 192 EM1_01_CRC 500;
BA_REL_ "GenSigTimeoutTime" BU_SG_REL_ Motor_BEV SG_ 192 EM1_01_BZ 500;
BA_REL_ "GenSigTimeoutTime" BU_SG_REL_ Motor_BEV SG_ 192 EM1_Istmodus 500;
BA_REL_ "GenSigTimeoutTime" BU_SG_REL_ Motor_BEV SG_ 192 EM1_IstMoment 500;
BA_REL_ "GenSigTimeoutTime" BU_SG_REL_ Motor_BEV SG_ 192 EM1_Moment_AR_Eingriff 500;
BA_REL_ "GenSigTimeoutTime" BU_SG_REL_ Motor_BEV SG_ 192 EM1_IstDrehzahl 500;
BA_REL_ "GenSigTimeoutTime" BU_SG_REL_ Motor_BEV SG_ 192 EM1_AR_aktiv 500;
BA_REL_ "GenSigTimeoutTime" BU_SG_REL_ Motor_BEV SG_ 192 EM1_IstSpannung 500;
BA_REL_ "GenSigTimeoutTime" BU_SG_REL_ Motor_BEV SG_ 192 EM1_Strom_HV 500;
BA_REL_ "GenSigTimeoutTime" BU_SG_REL_ Motor_BEV SG_ 192 EM1_Max_Moment 500;
BA_REL_ "GenSigTimeoutTime" BU_SG_REL_ Motor_BEV SG_ 192 EM1_ErwGrenzen_aktiv 500;
BA_REL_ "GenSigTimeoutTime" BU_SG_REL_ Motor_BEV SG_ 192 EM1_Min_Moment 500;
BA_REL_ "GenSigTimeoutTime" BU_SG_REL_ Motor_BEV SG_ 192 EM1_Fehler_ElAntriebAbschaltung 500;
BA_REL_ "GenSigTimeoutTime" BU_SG_REL_ Motor_BEV SG_ 192 EM1_Max_Moment_Lim 500;
BA_REL_ "GenSigTimeoutTime" BU_SG_REL_ Motor_BEV SG_ 192 EM1_Fehler_Notabschaltung 500;
BA_REL_ "GenSigTimeoutTime" BU_SG_REL_ Motor_BEV SG_ 192 EM1_Min_Moment_Lim 500;
BA_REL_ "GenSigTimeoutTime" BU_SG_REL_ Motor_BEV SG_ 192 EM1_Status_DrzEingriff 500;
BA_REL_ "GenSigTimeoutTime" BU_SG_REL_ Motor_BEV SG_ 192 EM1_Mom_DrzEingriff 500;
BA_REL_ "GenSigTimeoutTime" BU_SG_REL_ Motor_BEV SG_ 2463978673 EM1_Status_Spgfreiheit 1000;
BA_REL_ "GenSigTimeoutTime" BU_SG_REL_ Motor_BEV SG_ 2463978673 EM1_Status_EoHVL 1000;
BA_REL_ "GenSigTimeoutTime" BU_SG_REL_ Motor_BEV SG_ 2463978673 EM1_PerfInd_MaxLeistung 1000;
BA_REL_ "GenSigTimeoutTime" BU_SG_REL_ Motor_BEV SG_ 2463978673 EM1_PerfInd_MaxMoment 1000;
BA_REL_ "GenSigTimeoutTime" BU_SG_REL_ Motor_BEV SG_ 2463978673 EM1_AnlernenElMotor_Anf 1000;
BA_REL_ "GenSigTimeoutTime" BU_SG_REL_ Motor_BEV SG_ 2463978673 EM1_OBD_Lampe_Anf 1000;
BA_REL_ "GenSigTimeoutTime" BU_SG_REL_ Motor_BEV SG_ 2463978673 EM1_Generator_Moment 1000;
BA_REL_ "GenSigTimeoutTime" BU_SG_REL_ Motor_BEV SG_ 2463978673 EM1_PerfInd_Temperatur 1000;
BA_REL_ "GenSigTimeoutTime" BU_SG_REL_ Motor_BEV SG_ 2463978673 EM1_MaxZul_Drehzahl 1000;
BA_REL_ "GenSigTimeoutTime" BU_SG_REL_ Motor_BEV SG_ 2463978673 EM1_Min_Moment_Gesamt 1000;
BA_REL_ "GenSigTimeoutTime" BU_SG_REL_ Motor_BEV SG_ 2463978673 EM1_Fehlerlampe_Anf 1000;
BA_REL_ "GenSigTimeoutTime" BU_SG_REL_ Motor_BEV SG_ 2463978673 EM1_Max_Moment_Gesamt 1000;
BA_REL_ "GenSigTimeoutTime" BU_SG_REL_ Motor_BEV SG_ 2463978673 EM1_Warnlampe_Anf 1000;
BA_REL_ "GenSigTimeoutTime" BU_SG_REL_ Motor_BEV SG_ 2463978673 EM1_Rekuperation 1000;
BA_REL_ "GenSigTimeoutTime" BU_SG_REL_ Motor_BEV SG_ 2463978673 EM1_Rekuperation_Ueberlauf 1000;
BA_REL_ "GenSigTimeoutTime" BU_SG_REL_ Motor_BEV SG_ 2463978673 EM1_Verbrauch 1000;
BA_REL_ "GenSigTimeoutTime" BU_SG_REL_ Motor_BEV SG_ 2463978673 EM1_Verbrauch_Ueberlauf 1000;
BA_REL_ "GenSigTimeoutTime" BU_SG_REL_ Motor_BEV SG_ 2463978673 EM1_Fehler_AE 1000;
BA_REL_ "GenSigTimeoutTime" BU_SG_REL_ Motor_BEV SG_ 2463978673 EM1_Fehler_Leistungsred 1000;
BA_REL_ "GenSigTimeoutTime" BU_SG_REL_ Motor_BEV SG_ 2463978673 EM1_Fehler_ElAntriebFreilauf 1000;
BA_REL_ "GenSigTimeoutTime" BU_SG_REL_ Motor_BEV SG_ 2463978673 EM1_PWR_SollVolumenstrom 1000;
BA_REL_ "GenSigTimeoutTime" BU_SG_REL_ Motor_BEV SG_ 2589283657 EM1_SollVorlauftemperatur 5000;
BA_REL_ "GenSigTimeoutTime" BU_SG_REL_ Motor_BEV SG_ 2589283657 EM1_Temperatur_EM 5000;
BA_REL_ "GenSigTimeoutTime" BU_SG_REL_ Motor_BEV SG_ 2589283657 EM1_EM_SollVolumenstrom 5000;
BA_REL_ "GenSigTimeoutTime" BU_SG_REL_ Motor_BEV SG_ 2589283657 EM1_Max_MechLeistung_nom 5000;
BA_REL_ "GenSigTimeoutTime" BU_SG_REL_ Motor_BEV SG_ 2589283657 EM1_Max_Moment_nom 5000;
BA_REL_ "GenSigTimeoutTime" BU_SG_REL_ Motor_BEV SG_ 2589283657 EM1_Temperatur_PWR 5000;
BA_REL_ "GenSigTimeoutTime" BU_SG_REL_ Motor_BEV SG_ 184 EM1_Freigabe_Info_WFS 5000;
BA_REL_ "GenSigTimeoutTime" BU_SG_REL_ Motor_BEV SG_ 184 EM1_Sperr_Info_WFS 5000;
BA_REL_ "GenSigTimeoutTime" BU_SG_REL_ Motor_BEV SG_ 184 EM1_Freigabe_Verfallsinfo_WFS 5000;
BA_REL_ "GenSigTimeoutTime" BU_SG_REL_ Motor_BEV SG_ 193 EM2_01_CRC 500;
BA_REL_ "GenSigTimeoutTime" BU_SG_REL_ Motor_BEV SG_ 193 EM2_01_BZ 500;
BA_REL_ "GenSigTimeoutTime" BU_SG_REL_ Motor_BEV SG_ 193 EM2_Istmodus 500;
BA_REL_ "GenSigTimeoutTime" BU_SG_REL_ Motor_BEV SG_ 193 EM2_IstMoment 500;
BA_REL_ "GenSigTimeoutTime" BU_SG_REL_ Motor_BEV SG_ 193 EM2_Moment_AR_Eingriff 500;
BA_REL_ "GenSigTimeoutTime" BU_SG_REL_ Motor_BEV SG_ 193 EM2_IstDrehzahl 500;
BA_REL_ "GenSigTimeoutTime" BU_SG_REL_ Motor_BEV SG_ 193 EM2_AR_aktiv 500;
BA_REL_ "GenSigTimeoutTime" BU_SG_REL_ Motor_BEV SG_ 193 EM2_IstSpannung 500;
BA_REL_ "GenSigTimeoutTime" BU_SG_REL_ Motor_BEV SG_ 193 EM2_Strom_HV 500;
BA_REL_ "GenSigTimeoutTime" BU_SG_REL_ Motor_BEV SG_ 193 EM2_Max_Moment 500;
BA_REL_ "GenSigTimeoutTime" BU_SG_REL_ Motor_BEV SG_ 193 EM2_ErwGrenzen_aktiv 500;
BA_REL_ "GenSigTimeoutTime" BU_SG_REL_ Motor_BEV SG_ 193 EM2_Min_Moment 500;
BA_REL_ "GenSigTimeoutTime" BU_SG_REL_ Motor_BEV SG_ 193 EM2_Fehler_ElAntriebAbschaltung 500;
BA_REL_ "GenSigTimeoutTime" BU_SG_REL_ Motor_BEV SG_ 193 EM2_Max_Moment_Lim 500;
BA_REL_ "GenSigTimeoutTime" BU_SG_REL_ Motor_BEV SG_ 193 EM2_Fehler_Notabschaltung 500;
BA_REL_ "GenSigTimeoutTime" BU_SG_REL_ Motor_BEV SG_ 193 EM2_Min_Moment_Lim 500;
BA_REL_ "GenSigTimeoutTime" BU_SG_REL_ Motor_BEV SG_ 193 EM2_Status_DrzEingriff 500;
BA_REL_ "GenSigTimeoutTime" BU_SG_REL_ Motor_BEV SG_ 193 EM2_Mom_DrzEingriff 500;
BA_REL_ "GenSigTimeoutTime" BU_SG_REL_ Motor_BEV SG_ 2463978674 EM2_Status_Spgfreiheit 1000;
BA_REL_ "GenSigTimeoutTime" BU_SG_REL_ Motor_BEV SG_ 2463978674 EM2_Status_EoHVL 1000;
BA_REL_ "GenSigTimeoutTime" BU_SG_REL_ Motor_BEV SG_ 2463978674 EM2_PerfInd_MaxLeistung 1000;
BA_REL_ "GenSigTimeoutTime" BU_SG_REL_ Motor_BEV SG_ 2463978674 EM2_PerfInd_MaxMoment 1000;
BA_REL_ "GenSigTimeoutTime" BU_SG_REL_ Motor_BEV SG_ 2463978674 EM2_AnlernenElMotor_Anf 1000;
BA_REL_ "GenSigTimeoutTime" BU_SG_REL_ Motor_BEV SG_ 2463978674 EM2_OBD_Lampe_Anf 1000;
BA_REL_ "GenSigTimeoutTime" BU_SG_REL_ Motor_BEV SG_ 2463978674 EM2_Generator_Moment 1000;
BA_REL_ "GenSigTimeoutTime" BU_SG_REL_ Motor_BEV SG_ 2463978674 EM2_PerfInd_Temperatur 1000;
BA_REL_ "GenSigTimeoutTime" BU_SG_REL_ Motor_BEV SG_ 2463978674 EM2_MaxZul_Drehzahl 1000;
BA_REL_ "GenSigTimeoutTime" BU_SG_REL_ Motor_BEV SG_ 2463978674 EM2_Min_Moment_Gesamt 1000;
BA_REL_ "GenSigTimeoutTime" BU_SG_REL_ Motor_BEV SG_ 2463978674 EM2_Fehlerlampe_Anf 1000;
BA_REL_ "GenSigTimeoutTime" BU_SG_REL_ Motor_BEV SG_ 2463978674 EM2_Max_Moment_Gesamt 1000;
BA_REL_ "GenSigTimeoutTime" BU_SG_REL_ Motor_BEV SG_ 2463978674 EM2_Warnlampe_Anf 1000;
BA_REL_ "GenSigTimeoutTime" BU_SG_REL_ Motor_BEV SG_ 2463978674 EM2_Rekuperation 1000;
BA_REL_ "GenSigTimeoutTime" BU_SG_REL_ Motor_BEV SG_ 2463978674 EM2_Rekuperation_Ueberlauf 1000;
BA_REL_ "GenSigTimeoutTime" BU_SG_REL_ Motor_BEV SG_ 2463978674 EM2_Verbrauch 1000;
BA_REL_ "GenSigTimeoutTime" BU_SG_REL_ Motor_BEV SG_ 2463978674 EM2_Verbrauch_Ueberlauf 1000;
BA_REL_ "GenSigTimeoutTime" BU_SG_REL_ Motor_BEV SG_ 2463978674 EM2_Fehler_AE 1000;
BA_REL_ "GenSigTimeoutTime" BU_SG_REL_ Motor_BEV SG_ 2463978674 EM2_Fehler_Leistungsred 1000;
BA_REL_ "GenSigTimeoutTime" BU_SG_REL_ Motor_BEV SG_ 2463978674 EM2_Fehler_ElAntriebFreilauf 1000;
BA_REL_ "GenSigTimeoutTime" BU_SG_REL_ Motor_BEV SG_ 2463978674 EM2_PWR_SollVolumenstrom 1000;
BA_REL_ "GenSigTimeoutTime" BU_SG_REL_ Motor_BEV SG_ 2589283660 EM2_SollVorlauftemperatur 5000;
BA_REL_ "GenSigTimeoutTime" BU_SG_REL_ Motor_BEV SG_ 2589283660 EM2_Temperatur_EM 5000;
BA_REL_ "GenSigTimeoutTime" BU_SG_REL_ Motor_BEV SG_ 2589283660 EM2_EM_SollVolumenstrom 5000;
BA_REL_ "GenSigTimeoutTime" BU_SG_REL_ Motor_BEV SG_ 2589283660 EM2_Max_MechLeistung_nom 5000;
BA_REL_ "GenSigTimeoutTime" BU_SG_REL_ Motor_BEV SG_ 2589283660 EM2_Max_Moment_nom 5000;
BA_REL_ "GenSigTimeoutTime" BU_SG_REL_ Motor_BEV SG_ 2589283660 EM2_Temperatur_PWR 5000;
BA_REL_ "GenSigTimeoutTime" BU_SG_REL_ Motor_BEV SG_ 199 EM2_Freigabe_Info_WFS 5000;
BA_REL_ "GenSigTimeoutTime" BU_SG_REL_ Motor_BEV SG_ 199 EM2_Sperr_Info_WFS 5000;
BA_REL_ "GenSigTimeoutTime" BU_SG_REL_ Motor_BEV SG_ 199 EM2_Freigabe_Verfallsinfo_WFS 5000;
BA_REL_ "GenSigTimeoutTime" BU_SG_REL_ Motor_BEV SG_ 2589283649 EML_Reifenumfang 2000;
BA_REL_ "GenSigTimeoutTime" BU_SG_REL_ Motor_BEV SG_ 2589283649 EML_QBit_Reifenumfang 2000;
BA_REL_ "GenSigTimeoutTime" BU_SG_REL_ Motor_BEV SG_ 608 EML_AnzeigeGeschw 500;
BA_REL_ "GenSigTimeoutTime" BU_SG_REL_ Motor_BEV SG_ 2589283751 KBI_Kilometerstand_HiRes_meter 5000;
BA_REL_ "GenSigTimeoutTime" BU_SG_REL_ Schaltbetaetigung SG_ 1520 DI_KL_58xd 2000;
BA_REL_ "GenSigTimeoutTime" BU_SG_REL_ Schaltbetaetigung SG_ 1520 DI_KL_58xt 2000;
VAL_ 514 DR_Aufbaubeschleunigung_HR 1021 "Sensor_nicht_verbaut" 1022 "Init" 1023 "Fehler" ;
VAL_ 514 DR_Aufbaubeschleunigung_VR 1021 "Sensor_nicht_verbaut" 1022 "Init" 1023 "Fehler" ;
VAL_ 514 DR_Aufbaubeschleunigung_VL 1021 "Sensor_nicht_verbaut" 1022 "Init" 1023 "Fehler" ;
VAL_ 514 DR_Aufbaubeschleunigung_HL 1021 "Sensor_nicht_verbaut" 1022 "Init" 1023 "Fehler" ;
VAL_ 514 DR_Funktionsstatus 0 "Init" 1 "Funktion_iO" 2 "Fehlerzustand_erkannt" 3 "keine_Inbetriebnahme" ;
VAL_ 514 DR_Drehwinkelsensortausch_VL 0 "Init" ;
VAL_ 514 DR_Drehwinkelsensortausch_VR 0 "Init" ;
VAL_ 514 DR_Drehwinkelsensortausch_HL 0 "Init" ;
VAL_ 514 DR_Drehwinkelsensortausch_HR 0 "Init" ;
VAL_ 514 DR_Drehwinkel_VL 4091 "nicht_verwendet" 4092 "nicht_verwendet" 4093 "Sensor_nicht_verbaut" 4094 "Init" 4095 "Fehler" ;
VAL_ 514 DR_Drehwinkel_VR 4091 "nicht_verwendet" 4092 "nicht_verwendet" 4093 "Sensor_nicht_verbaut" 4094 "Init" 4095 "Fehler" ;
VAL_ 514 DR_Drehwinkel_HL 4091 "nicht_verwendet" 4092 "nicht_verwendet" 4093 "Sensor_nicht_verbaut" 4094 "Init" 4095 "Fehler" ;
VAL_ 514 DR_Drehwinkel_HR 4091 "nicht_verwendet" 4092 "nicht_verwendet" 4093 "Sensor_nicht_verbaut" 4094 "Init" 4095 "Fehler" ;
VAL_ 1485 DC_Temperatur_Alarm 0 "kein_Fehler" 1 "Fehler" ;
VAL_ 1485 DC_Kl30c_Status 0 "Init" 1 "geschlossen" 2 "offen" 3 "Fehler" ;
VAL_ 1485 DC_Fehlerstatus 0 "Komponente_IO" 1 "Eingeschr_KompFkt_Entlad_defekt" 3 "Eingeschr_KompFkt_Interlock" 6 "Keine_Komponentenfunktion" 7 "Init" ;
VAL_ 1485 DC_Peakstrom_verfuegbar 0 "Peakstrom_nicht_verfuegbar" 1 "Peakstrom_verfuegbar" ;
VAL_ 1485 DC_Abregelung_Temperatur 0 "keine_Abregelung" 1 "Abregelung_Temp" ;
VAL_ 1485 DC_IstModus_02 0 "Standby" 1 "HV_On_Vorladen" 2 "Tiefsetzen" 3 "Hochsetzen" 4 "Pruefimpuls_12V" 5 "Fehler" 7 "Initialisierung" ;
VAL_ 1485 DC_Derating 0 "keine_Abregelung" 1 "Abregelung_Ursache_NV" 2 "Abregelung_Ursache_HV" 3 "Abregelung_Ursache_Temp" 4 "Abregelung_Ursache_Intern" ;
VAL_ 1485 DC_SollVolumenstrom 62 "Init" 63 "Fehler" ;
VAL_ 1485 DC_Status_Spgfreiheit_HV 0 "Init" 1 "HV_Komponente_spannungsfrei" 2 "HV_Komp_nicht_spannungsfrei" 3 "Fehler_nicht_spannungsfrei" ;
VAL_ 1485 DC_Temperatur 254 "Init" 255 "Fehler" ;
VAL_ 247 DC_Vorladung_Status 0 "nicht_abgeschlossen" 1 "abgeschlossen" ;
VAL_ 247 DC_Fehler_extern 0 "kein_Fehler" 1 "Fehler" ;
VAL_ 247 DC_Fehler_intern 0 "Init" 1 "interner_Fehler_erkannt" ;
VAL_ 247 DC_Status_Spgfreiheit 0 "Init" 1 "HV_Komponente_spannungsfrei" 2 "HV_Komp_nicht_spannungsfrei" 3 "Fehler_nicht_spannungsfrei" ;
VAL_ 247 DC_Status_EoHVL 0 "Init" 1 "Keine_offene_HV_Leitung_erkannt" 2 "offene_HV_Leitung_erkannt" 3 "Fehler" ;
VAL_ 247 DC_IstModus_02 0 "Standby" 1 "HV_On_Vorladen" 2 "Tiefsetzen" 3 "Hochsetzen" 4 "Pruefimpuls_12V" 5 "Fehler" 7 "Initialisierung" ;
VAL_ 247 DC_IstStrom_HV 1022 "Init" 1023 "Fehler" ;
VAL_ 247 DC_IstLeistung_HV 1022 "Init" 1023 "Fehler" ;
VAL_ 1714 DGN_Verlernzaehler 255 "ungültiger Zählerstand oder kein gültiger Fahrzyklus" ;
VAL_ 1714 KBI_Kilometerstand 1048574 "Init" 1048575 "Fehler" ;
VAL_ 1714 UH_Monat 0 "Init" 14 "reserviert" 15 "Fehler" ;
VAL_ 1714 UH_Tag 0 "Init" ;
VAL_ 1714 Vehicle_Driving_Cycle 0 "kein_Driving_Cycle_erkannt" 1 "Driving_Cycle_erkannt" ;
VAL_ 1714 Kombi_02_alt 0 "aktuell" 1 "veraltet" ;
VAL_ 1714 Uhrzeit_01_alt 0 "aktuell" 1 "veraltet" ;
VAL_ 851 DiETa_Status 0 "DiETa_betriebsbereit" 2 "Init" 3 "Fehler_oder_defekt" ;
VAL_ 851 DiETa_ResponseError 0 "normal" 1 "Fehler" ;
VAL_ 851 DiETa_Car 0 "Init_oder_nicht_verbaut" 1 "Taste_unbetaetigt" 2 "Taste_betaetigt" 3 "Fehler" ;
VAL_ 851 DiETa_Klima 0 "Init_oder_nicht_verbaut" 1 "Taste_unbetaetigt" 2 "Taste_betaetigt" 3 "Fehler" ;
VAL_ 851 DiETa_Mode 0 "Init_oder_nicht_verbaut" 1 "Taste_unbetaetigt" 2 "Taste_betaetigt" 3 "Fehler" ;
VAL_ 851 DiETa_Parken 0 "Init_oder_nicht_verbaut" 1 "Taste_unbetaetigt" 2 "Taste_betaetigt" 3 "Fehler" ;
VAL_ 851 DiETa_FSH_Taste 0 "Init_oder_nicht_verbaut" 1 "Taste_unbetaetigt" 2 "Taste_betaetigt" 3 "Fehler" ;
VAL_ 851 DiETa_HSH_Taste 0 "Init_oder_nicht_verbaut" 1 "Taste_unbetaetigt" 2 "Taste_betaetigt" 3 "Fehler" ;
VAL_ 851 DiETa_Warnblink_Taste 0 "Init_oder_nicht_verbaut" 1 "Taste_unbetaetigt" 2 "Taste_betaetigt" 3 "Fehler" ;
VAL_ 851 DiETa_FAS_Stufe 0 "Init_oder_nicht_verbaut" 1 "Taste_unbetaetigt" 2 "Taste_betaetigt" 3 "Fehler" ;
VAL_ 851 DiETa_PAO_ON_Status 0 "LED_Aus" 1 "LED_Ein" 2 "LED_Blinkt" 3 "LED_defekt" ;
VAL_ 851 DiETa_PAO_OFF_Status 0 "LED_Aus" 1 "LED_Ein" 2 "LED_Blinkt" 3 "LED_defekt" ;
VAL_ 851 DiETa_Defrost_Taste 0 "Init_oder_nicht_verbaut" 1 "Taste_unbetaetigt" 2 "Taste_betaetigt" 3 "Fehler" ;
VAL_ 851 DiETa_Lock_Unlock_Taste 0 "Init" 1 "Taste_unbetaetigt" 2 "Taste_betaetigt_unlock" 3 "Taste_betaetigt_lock" 4 "Reserviert" 5 "Reserviert" 6 "Reserviert" 7 "Fehler" ;
VAL_ 851 DiETa_Mode_roh 0 "Taste_unbetaetigt" 1 "Taste_betaetigt" ;
VAL_ 1520 DI_KL_58xd 254 "Init" 255 "Fehler" ;
VAL_ 1520 DI_KL_58xs 126 "Init" 127 "Fehler" ;
VAL_ 1520 DI_KL_58xt 126 "Init" 127 "Fehler" ;
VAL_ 1520 BCM1_Stellgroesse_Kl_58s 125 "Nicht_verbaut" 126 "Init" 127 "Fehler" ;
VAL_ 420 EA_Parken_beibehalten_HMS 0 "Parken_nicht_beibehalten" 1 "Parken_beibehalten" 2 "Init" 3 "Fehler" ;
VAL_ 420 EA_Ruckstaerke 0 "Keine_Anforderung" 1 "Schwach" 2 "Mittel" 3 "Stark" ;
VAL_ 420 EA_Warnruckprofil 0 "keine_Ruckanforderung" 1 "Profil_1" 2 "Profil_2" 3 "Profil_3" 4 "Profil_4" 5 "Profil_5" 6 "Profil_6" 7 "Profil_7" ;
VAL_ 420 EA_aktiv_laengs 0 "nicht_aktiv" 1 "aktiv_Vorstufe" 2 "aktiv_Hauptstufe" ;
VAL_ 420 EA_Funktionsstatus 0 "EA_INIT" 1 "EA_OFF" 2 "EA_STANDBY" 3 "EA_PHASE0_AKTIV" 4 "EA_PHASE1_AKTIV" 5 "EA_PHASE2_AKTIV" 6 "EA_PHASE3_AKTIV" 7 "EA_REVERSIBLER_FEHLER" 8 "EA_IRREVERSIBLER_FEHLER" ;
VAL_ 420 EA_Gurtstraffer_Anf 0 "Keine_Anforderung" 1 "Haptik_1" 2 "Haptik_2" 3 "Haptik_3" ;
VAL_ 420 EA_Anf_Prefill 0 "Prefill_nicht_aktivieren" 1 "Prefill_aktivieren" ;
VAL_ 420 EA_Anforderung_HMS 0 "keine_Anforderung" 1 "halten" 2 "parken" 3 "halten_Standby" 4 "anfahren" 5 "Loesen_ueber_Rampe" 6 "Parken_mit_P" ;
VAL_ 420 EA_Ruckfreigabe 0 "keine_Freigabe" 1 "Freigabe" ;
VAL_ 420 EA_01_Sendestatus 0 "EA_01_im_langsamen_Zyklus" 1 "EA_01_im_schnellen_Zyklus" ;
VAL_ 420 EA_Sollbeschleunigung 2046 "Neutralwert" 2047 "Fehler" ;
VAL_ 374 EBKV_Activate_Fallback_ESP 0 "Rueckfallebene_nicht_aktiv" 1 "Rueckfallebene_aktiv" ;
VAL_ 374 EBKV_Restdruckabsenkung 0 "RPR_Passive" 1 "RPR_Preload" 2 "RPR_Hold" 3 "RPR_Suction" 4 "RPR_HoldLowPressure" 5 "RPR_Abort" ;
VAL_ 374 EBKV_Status_02 0 "EBKV_nicht_initialisiert" 1 "EBKV_Fehler_Zustand_aus" 2 "EBKV_Diagnose" 3 "EBKV_nicht_belegt" 4 "EBKV_Standalone" 5 "EBKV_degradiert" 6 "EBKV_Nachlauf_degradiert" 7 "EBKV_bereit" 8 "EBKV_Ausfall_Rekukomponente" 9 "EBKV_nicht_belegt" 10 "EBKV_nicht_belegt" 11 "EBKV_nicht_belegt" 12 "EBKV_nicht_belegt" 13 "EBKV_nicht_belegt" 14 "EBKV_nicht_belegt" 15 "EBKV_nicht_belegt" ;
VAL_ 374 EBKV_Diagnose 0 "Diagnose_inaktiv" 1 "Diagnose_aktiv" ;
VAL_ 374 EBKV_Fahrer_bremst 0 "Fahrer_bremst_nicht_selbst" 1 "Fahrer_will_selbst_bremsen" ;
VAL_ 374 EBKV_QBit_Fahrer_bremst 0 "gueltiger_Wert" 1 "Ersatz_Init_oder_Fehlerwert" ;
VAL_ 374 EBKV_Fahrer_bremst_deutlich 0 "Fahrer_uebertritt_Schwelle_nicht" 1 "Fahrer_uebertritt_Schwelle" ;
VAL_ 374 EBKV_OBD_Status 0 "MIL_aus" 1 "MIL_ein" ;
VAL_ 374 EBKV_VMM_Sek_Notstopp_Status 0 "Init" 1 "Verfuegbar" 2 "Passiv_Ueberwachung" 3 "Aktiv_Ausgeloest" 4 "Systemkomponente_Defekt" ;
VAL_ 374 EBKV_Anforderung_HMS 0 "keine_Anforderung" 1 "halten" 2 "parken" 3 "halten_Standby" 4 "anfahren" 5 "Loesen_ueber_Rampe" ;
VAL_ 374 SBS_Anforderung_GE 0 "keine_Anforderung" 1 "P_einlegen" ;
VAL_ 374 EPB_Status_ext 0 "offen" 1 "geschlossen_Parken" 2 "teilgespannt_Halten" 3 "im_Lauf_oeffnen" 4 "im_Lauf_schliessen" 5 "tbd" 6 "Init" 7 "unbekannt" ;
VAL_ 374 EBKV_Bremspedalweg 0 "Init" 255 "Fehler" ;
VAL_ 374 EBKV_Kraftblending_Reserve 254 "Init" 255 "Fehler" ;
VAL_ 374 EBKV_Aussteuerdruck 251 "Aussteuerdruck_VKM_Start" 252 "Aussteuerdruck_Nachlauf_Phase1" 253 "Aussteuerdruck_Nachlauf_Phase2" 254 "Init" 255 "Fehler" ;
VAL_ 1603 KBI_Einheit_Datum 0 "Tag/Monat/Jahr" 1 "Monat/Tag/Jahr" 2 "Jahr/Monat/Tag" 3 "reserviert" ;
VAL_ 1603 KBI_Einheit_Druck 0 "Druckangabe in bar" 1 "Druckangabe in psi" 2 "Druckangabe in kPa" 3 "tbd." ;
VAL_ 1603 KBI_Einheit_Streckenanz 0 "Kilometer" 1 "Meilen" ;
VAL_ 1603 KBI_MFA_v_Einheit_02 0 "kmh" 1 "mph" ;
VAL_ 1603 KBI_Einheit_Temp 0 "Grad Celsius °C" 1 "Grad Fahrenheit °F" ;
VAL_ 1603 KBI_Einheit_Uhrzeit 0 "24h" 1 " 12h AM/PM" ;
VAL_ 1603 KBI_Einheit_Verbrauch 0 "mpg UK" 1 "mpg USA" 2 "Liter/100km" 3 "km/Liter" ;
VAL_ 1603 KBI_Einheit_Volumen 0 "Liter" 1 "Gallonen UK" 2 "Gallonen USA" 3 "reserviert" ;
VAL_ 1603 KBI_Einheit_Verbrauch_elektr 0 "kWh_pro_100km" 1 "km_pro_kWh" 2 "kWh_pro_100mls" 3 "mls_pro_kWh" 4 "MPGe" ;
VAL_ 1603 KBI_Einheit_Tacho 0 "km/h" 1 "mph" ;
VAL_ 1603 KBI_Einheit_Verbrauch_Gas 0 "kg_per_100km" 1 "km_per_kg" 2 "m3_per_100km" 3 "km_per_m3" 4 "miles_per_lbs" 5 "miles_per_yard3" 6 "miles_per_kg" 7 "miles_per_m3" 8 "miles_per_gallon_equivalent_US" ;
VAL_ 1603 KBI_Einheit_Masse 0 "kg" 1 "lbs" 2 "reserviert" ;
VAL_ 192 EM1_Istmodus 0 "Standby" 1 "Momentenreg" 2 "Int_Drehzahlreg" 3 "Spannungsreg" 4 "Ext_Drehzahlreg" 5 "Inverter_Fehler" 6 "Kalibrierung" 7 "Sonderbremsbetrieb" 8 "Freilauf" 15 "Initialisierung" ;
VAL_ 192 EM1_IstMoment 4094 "Init" 4095 "Fehler" ;
VAL_ 192 EM1_Moment_AR_Eingriff 4094 "Init" 4095 "Fehler" ;
VAL_ 192 EM1_IstDrehzahl 32766 "Init" 32767 "Fehler" ;
VAL_ 192 EM1_AR_aktiv 0 "Init" 1 "Ruckeldaempfer_aktiv" ;
VAL_ 192 EM1_IstSpannung 4094 "Init" 4095 "Fehler" ;
VAL_ 192 EM1_Strom_HV 4094 "Init" 4095 "Fehler" ;
VAL_ 192 EM1_Max_Moment 2046 "Init" 2047 "Fehler" ;
VAL_ 192 EM1_ErwGrenzen_aktiv 0 "kein_extended_Range" 1 "extended_Range" ;
VAL_ 192 EM1_Min_Moment 2046 "Init" 2047 "Fehler" ;
VAL_ 192 EM1_Fehler_ElAntriebAbschaltung 0 "Init" 1 "Abschaltung" ;
VAL_ 192 EM1_Max_Moment_Lim 2046 "Init" 2047 "Fehler" ;
VAL_ 192 EM1_Fehler_Notabschaltung 0 "kein_Fehler" 1 "Fehler" ;
VAL_ 192 EM1_Min_Moment_Lim 2046 "Init" 2047 "Fehler" ;
VAL_ 192 EM1_Status_DrzEingriff 0 "kein_Eingriff" 1 "Eingriff_Max_Drehzahlregler" 2 "Eingriff_Min_Drehzahlregler" 3 "Fehler" ;
VAL_ 192 EM1_Mom_DrzEingriff 2046 "Init" 2047 "Fehler" ;
VAL_ 2463978673 EM1_Status_Spgfreiheit 0 "Init" 1 "HV_Komponente_spannungsfrei" 2 "HV_Komp_nicht_spannungsfrei" 3 "Fehler_nicht_spannungsfrei" ;
VAL_ 2463978673 EM1_Status_EoHVL 0 "Init" 1 "Keine_offene_HV_Leitung_erkannt" 2 "offene_HV_Leitung_erkannt" 3 "Fehler" ;
VAL_ 2463978673 EM1_Max_LeistungMech_Sockel 8190 "Init" 8191 "Fehler" ;
VAL_ 2463978673 EM1_Max_Moment_Sockel 2046 "Init" 2047 "Fehler" ;
VAL_ 2463978673 EM1_Min_LeistungMech_Sockel 8190 "Init" 8191 "Fehler" ;
VAL_ 2463978673 EM1_Min_Moment_Sockel 2046 "Init" 2047 "Fehler" ;
VAL_ 2463978673 EM1_PerfInd_MaxLeistung 1022 "Init" ;
VAL_ 2463978673 EM1_PerfInd_MaxMoment 1022 "Init" ;
VAL_ 2463978673 EM1_AnlernenElMotor_Anf 0 "kein_Diagnose_Request" 1 "Diagnose_Request" ;
VAL_ 2463978673 EM1_OBD_Lampe_Anf 0 "kein_MIL_Request" 1 "MIL_Request" ;
VAL_ 2463978673 EM1_Generator_Moment 1022 "Init" 1023 "Fehler" ;
VAL_ 2463978673 EM1_PerfInd_Temperatur 254 "Init" ;
VAL_ 2463978673 EM1_MaxZul_Drehzahl 254 "Init" 255 "Fehler" ;
VAL_ 2463978673 EM1_Min_Moment_Gesamt 2046 "Init" 2047 "Fehler" ;
VAL_ 2463978673 EM1_Fehlerlampe_Anf 0 "kein_Fehler" 1 "Anforderung_rote_Lampe" ;
VAL_ 2463978673 EM1_Max_Moment_Gesamt 2046 "Init" 2047 "Fehler" ;
VAL_ 2463978673 EM1_Warnlampe_Anf 0 "kein_Fehler" 1 "Anforderung_gelbe_Lampe" ;
VAL_ 2463978673 EM1_Rekuperation_Ueberlauf 0 "kein_Ueberlauf" 1 "Ueberlauf" ;
VAL_ 2463978673 EM1_Verbrauch_Ueberlauf 0 "kein_Ueberlauf" 1 "Ueberlauf" ;
VAL_ 2463978673 EM1_Fehler_AE 0 "kein_Fehler" 1 "Fehler_aktive_Entladung" ;
VAL_ 2463978673 EM1_Fehler_Leistungsred 0 "Init" 1 "Leistungsreduzierung" ;
VAL_ 2463978673 EM1_Fehler_ElAntriebFreilauf 0 "Init" 1 "Fehler__EM_im_Freilauf" ;
VAL_ 2463978673 EM1_PWR_SollVolumenstrom 62 "Init" 63 "Fehler" ;
VAL_ 2589283657 EM1_SollVorlauftemperatur 254 "Init" 255 "Fehler" ;
VAL_ 2589283657 EM1_Temperatur_EM 510 "Init" 511 "Fehler" ;
VAL_ 2589283657 EM1_EM_SollVolumenstrom 62 "Init" 63 "Fehler" ;
VAL_ 2589283657 EM1_Max_MechLeistung_nom 4094 "Init" 4095 "Fehler" ;
VAL_ 2589283657 EM1_Max_Moment_nom 1022 "Init" 1023 "Fehler" ;
VAL_ 2589283657 EM1_Temperatur_PWR 254 "Init" 255 "Fehler" ;
VAL_ 184 EM1_Freigabe_Info_WFS 0 "ungueltig" 1 "gueltig" ;
VAL_ 184 EM1_Sperr_Info_WFS 0 "nicht_gesperrt" 1 "gesperrt" ;
VAL_ 184 EM1_AR_aktiv 0 "Init" 1 "Ruckeldaempfer_aktiv" ;
VAL_ 184 EM1_Eta_Sys 510 "Init" 511 "Fehler" ;
VAL_ 184 EM1_IstStrom 2046 "Init" 2047 "Fehler" ;
VAL_ 184 EM1_Fehler_ElAntriebFreilauf_Anf 0 "Init" 1 "Fehler_EM_im_Freilauf" ;
VAL_ 184 EM1_Abregelung_Temperatur 0 "Init" 1 "Abregelung_Temperatur" ;
VAL_ 184 EM1_AnlernenElMotor_Anf 0 "kein_Diagnose_Request" 1 "Diagnose_Request" ;
VAL_ 184 EM1_Moment_HVVerbraucher 1023 "Init" ;
VAL_ 184 EM1_Freigabe_Verfallsinfo_WFS 0 "Aus" 1 "Ein" ;
VAL_ 184 EM1_Parken_WFS_Status 0 "Limitierung_Inaktiv" 1 "Limitierung_Aktiv" 2 "Abbruch" ;
VAL_ 184 EM1_HV_betriebsbereit 0 "Init" 1 "Ready_HV" ;
VAL_ 2527679712 EM1_RtmWarnKommunikation 0 "kein_Fehler" 1 "Fehler_Stufe_1" 2 "Fehler_Stufe_2" 3 "Fehler_Stufe_3" 4 "reserviert" 5 "reserviert" 6 "reserviert" 7 "reserviert" ;
VAL_ 2527679712 EM1_RtmWarnUeberdrehzahl 0 "kein_Fehler" 1 "Fehler_Stufe_1" 2 "Fehler_Stufe_2" 3 "Fehler_Stufe_3" 4 "reserviert" 5 "reserviert" 6 "reserviert" 7 "reserviert" ;
VAL_ 2527679712 EM1_RtmWarnUeberstrom 0 "kein_Fehler" 1 "Fehler_Stufe_1" 2 "Fehler_Stufe_2" 3 "Fehler_Stufe_3" 4 "reserviert" 5 "reserviert" 6 "reserviert" 7 "reserviert" ;
VAL_ 2527679712 EM1_RtmWarnTempEM 0 "kein_Fehler" 1 "Fehler_Stufe_1" 2 "Fehler_Stufe_2" 3 "Fehler_Stufe_3" 4 "reserviert" 5 "reserviert" 6 "reserviert" 7 "reserviert" ;
VAL_ 2527679712 EM1_RtmWarnTempPWR 0 "kein_Fehler" 1 "Fehler_Stufe_1" 2 "Fehler_Stufe_2" 3 "Fehler_Stufe_3" 4 "reserviert" 5 "reserviert" 6 "reserviert" 7 "reserviert" ;
VAL_ 193 EM2_Istmodus 0 "Standby" 1 "Momentenreg" 2 "Int_Drehzahlreg" 3 "Spannungsreg" 4 "Ext_Drehzahlreg" 5 "Inverter_Fehler" 6 "Kalibrierung" 7 "Sonderbremsbetrieb" 8 "Freilauf" 15 "Initialisierung" ;
VAL_ 193 EM2_IstMoment 4094 "Init" 4095 "Fehler" ;
VAL_ 193 EM2_Moment_AR_Eingriff 4094 "Init" 4095 "Fehler" ;
VAL_ 193 EM2_IstDrehzahl 32766 "Init" 32767 "Fehler" ;
VAL_ 193 EM2_AR_aktiv 0 "Init" ;
VAL_ 193 EM2_IstSpannung 4094 "Init" 4095 "Fehler" ;
VAL_ 193 EM2_Strom_HV 4094 "Init" 4095 "Fehler" ;
VAL_ 193 EM2_Max_Moment 2046 "Init" 2047 "Fehler" ;
VAL_ 193 EM2_ErwGrenzen_aktiv 0 "kein_extended_Range" 1 "extended_Range" ;
VAL_ 193 EM2_Min_Moment 2046 "Init" 2047 "Fehler" ;
VAL_ 193 EM2_Fehler_ElAntriebAbschaltung 0 "Init" 1 "Abschaltung" ;
VAL_ 193 EM2_Max_Moment_Lim 2046 "Init" 2047 "Fehler" ;
VAL_ 193 EM2_Fehler_Notabschaltung 0 "kein_Fehler" 1 "Fehler" ;
VAL_ 193 EM2_Min_Moment_Lim 2046 "Init" 2047 "Fehler" ;
VAL_ 193 EM2_Status_DrzEingriff 0 "kein_Eingriff" 1 "Eingriff_Max_Drehzahlregler" 2 "Eingriff_Min_Drehzahlregler" 3 "Fehler" ;
VAL_ 193 EM2_Mom_DrzEingriff 2046 "Init" 2047 "Fehler" ;
VAL_ 2463978674 EM2_Status_Spgfreiheit 0 "Init" 1 "HV_Komponente_spannungsfrei" 2 "HV_Komp_nicht_spannungsfrei" 3 "Fehler_nicht_spannungsfrei" ;
VAL_ 2463978674 EM2_Status_EoHVL 0 "Init" 1 "Keine_offene_HV_Leitung_erkannt" 2 "offene_HV_Leitung_erkannt" 3 "Fehler" ;
VAL_ 2463978674 EM2_Max_LeistungMech_Sockel 8190 "Init" 8191 "Fehler" ;
VAL_ 2463978674 EM2_Max_Moment_Sockel 2046 "Init" 2047 "Fehler" ;
VAL_ 2463978674 EM2_Min_LeistungMech_Sockel 8190 "Init" 8191 "Fehler" ;
VAL_ 2463978674 EM2_Min_Moment_Sockel 2046 "Init" 2047 "Fehler" ;
VAL_ 2463978674 EM2_PerfInd_MaxLeistung 1022 "Init" ;
VAL_ 2463978674 EM2_PerfInd_MaxMoment 1022 "Init" ;
VAL_ 2463978674 EM2_AnlernenElMotor_Anf 0 "kein_Diagnose_Request" 1 "Diagnose_Request" ;
VAL_ 2463978674 EM2_OBD_Lampe_Anf 0 "kein_MIL_Request" 1 "MIL_Request" ;
VAL_ 2463978674 EM2_Generator_Moment 1022 "Init" 1023 "Fehler" ;
VAL_ 2463978674 EM2_PerfInd_Temperatur 254 "Init" ;
VAL_ 2463978674 EM2_MaxZul_Drehzahl 254 "Init" 255 "Fehler" ;
VAL_ 2463978674 EM2_Min_Moment_Gesamt 2046 "Init" 2047 "Fehler" ;
VAL_ 2463978674 EM2_Fehlerlampe_Anf 0 "kein_Fehler" 1 "Anforderung_rote_Lampe" ;
VAL_ 2463978674 EM2_Max_Moment_Gesamt 2046 "Init" 2047 "Fehler" ;
VAL_ 2463978674 EM2_Warnlampe_Anf 0 "kein_Fehler" 1 "Anforderung_gelbe_Lampe" ;
VAL_ 2463978674 EM2_Rekuperation_Ueberlauf 0 "kein_Ueberlauf" 1 "Ueberlauf" ;
VAL_ 2463978674 EM2_Verbrauch_Ueberlauf 0 "kein_Ueberlauf" 1 "Ueberlauf" ;
VAL_ 2463978674 EM2_Fehler_AE 0 "kein_Fehler" 1 "Fehler_aktive_Entladung" ;
VAL_ 2463978674 EM2_Fehler_Leistungsred 0 "Init" 1 "Leistungsreduzierung" ;
VAL_ 2463978674 EM2_Fehler_ElAntriebFreilauf 0 "Init" 1 "Fehler__EM_im_Freilauf" ;
VAL_ 2463978674 EM2_PWR_SollVolumenstrom 62 "Init" 63 "Fehler" ;
VAL_ 2589283660 EM2_SollVorlauftemperatur 254 "Init" 255 "Fehler" ;
VAL_ 2589283660 EM2_Temperatur_EM 510 "Init" 511 "Fehler" ;
VAL_ 2589283660 EM2_EM_SollVolumenstrom 62 "Init" 63 "Fehler" ;
VAL_ 2589283660 EM2_Max_MechLeistung_nom 4094 "Init" 4095 "Fehler" ;
VAL_ 2589283660 EM2_Max_Moment_nom 1022 "Init" 1023 "Fehler" ;
VAL_ 2589283660 EM2_Temperatur_PWR 254 "Init" 255 "Fehler" ;
VAL_ 199 EM2_Freigabe_Info_WFS 0 "ungueltig" 1 "gueltig" ;
VAL_ 199 EM2_Sperr_Info_WFS 0 "nicht_gesperrt" 1 "gesperrt" ;
VAL_ 199 EM2_AR_aktiv 0 "Init" ;
VAL_ 199 EM2_Eta_Sys 510 "Init" 511 "Fehler" ;
VAL_ 199 EM2_IstStrom 2046 "Init" 2047 "Fehler" ;
VAL_ 199 EM2_Fehler_ElAntriebFreilauf_Anf 0 "Init" 1 "Fehler_EM_im_Freilauf" ;
VAL_ 199 EM2_Abregelung_Temperatur 0 "Init" 1 "Abregelung_Temperatur" ;
VAL_ 199 EM2_AnlernenElMotor_Anf 0 "kein_Diagnose_Request" 1 "Diagnose_Request" ;
VAL_ 199 EM2_Freigabe_Verfallsinfo_WFS 0 "Aus" 1 "Ein" ;
VAL_ 199 EM2_Parken_WFS_Status 0 "Limitierung_Inaktiv" 1 "Limitierung_Aktiv" 2 "Abbruch" ;
VAL_ 199 EM2_HV_betriebsbereit 0 "Init" 1 "Ready_HV" ;
VAL_ 2527679713 EM2_RtmWarnKommunikation 0 "kein_Fehler" 1 "Fehler_Stufe_1" 2 "Fehler_Stufe_2" 3 "Fehler_Stufe_3" 4 "reserviert" 5 "reserviert" 6 "reserviert" 7 "reserviert" ;
VAL_ 2527679713 EM2_RtmWarnUeberdrehzahl 0 "kein_Fehler" 1 "Fehler_Stufe_1" 2 "Fehler_Stufe_2" 3 "Fehler_Stufe_3" 4 "reserviert" 5 "reserviert" 6 "reserviert" 7 "reserviert" ;
VAL_ 2527679713 EM2_RtmWarnUeberstrom 0 "kein_Fehler" 1 "Fehler_Stufe_1" 2 "Fehler_Stufe_2" 3 "Fehler_Stufe_3" 4 "reserviert" 5 "reserviert" 6 "reserviert" 7 "reserviert" ;
VAL_ 2527679713 EM2_RtmWarnTempEM 0 "kein_Fehler" 1 "Fehler_Stufe_1" 2 "Fehler_Stufe_2" 3 "Fehler_Stufe_3" 4 "reserviert" 5 "reserviert" 6 "reserviert" 7 "reserviert" ;
VAL_ 2527679713 EM2_RtmWarnTempPWR 0 "kein_Fehler" 1 "Fehler_Stufe_1" 2 "Fehler_Stufe_2" 3 "Fehler_Stufe_3" 4 "reserviert" 5 "reserviert" 6 "reserviert" 7 "reserviert" ;
VAL_ 2589283649 EML_ReifenKorrFaktorHL 510 "Init" 511 "Fehler" ;
VAL_ 2589283649 EML_ReifenKorrFaktorHR 510 "Init" 511 "Fehler" ;
VAL_ 2589283649 EML_ReifenKorrFaktorVL 510 "Init" 511 "Fehler" ;
VAL_ 2589283649 EML_ReifenKorrFaktorVR 510 "Init" 511 "Fehler" ;
VAL_ 2589283649 EML_QBit_Reifenumfang 0 "gueltiger_Wert" 1 "Ersatz_Init_oder_Fehlerwert" ;
VAL_ 608 EML_AnzeigeGeschw 1022 "Init" 1023 "Fehler" ;
VAL_ 2527679687 EPS_ASM_Ereignis 0 "No_Event" 255 "ASM_Trigger" ;
VAL_ 2527679687 EPS_ASM_Zeitstempel 255 "INIT" ;
